VERSION ""

NS_ :

BS_:

BU_: FBD_HL IPB_App1 FBD_HM FBD_HR FBD_Miko FBD_MM FBD_Trunk FBD_VL FBD_VM FBD_VR Diagnosetool_CAN_FD_IPB_41

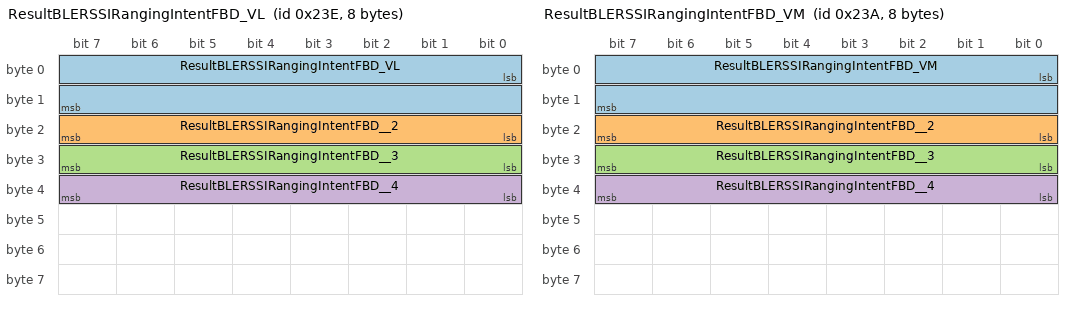
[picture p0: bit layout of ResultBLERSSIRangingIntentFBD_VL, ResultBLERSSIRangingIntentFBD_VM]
BO_ 574 ResultBLERSSIRangingIntentFBD_VL: 8 FBD_VL
 SG_ ResultBLERSSIRangingIntentFBD_VL : 0|16@1+ (1,0) [0|0] "" FBD_HL,FBD_HM,FBD_HR,FBD_MM,FBD_Miko,FBD_Trunk,FBD_VM,FBD_VR
 SG_ ResultBLERSSIRangingIntentFBD__2 : 16|8@1+ (1.0,0) [0|252] "" FBD_HL,FBD_HM,FBD_HR,FBD_MM,FBD_Miko,FBD_Trunk,FBD_VM,FBD_VR
 SG_ ResultBLERSSIRangingIntentFBD__3 : 24|8@1+ (1.0,0) [0|252] "" FBD_HL,FBD_HM,FBD_HR,FBD_MM,FBD_Miko,FBD_Trunk,FBD_VM,FBD_VR
 SG_ ResultBLERSSIRangingIntentFBD__4 : 32|8@1+ (0.004,0) [0|1] "" FBD_HL,FBD_HM,FBD_HR,FBD_MM,FBD_Miko,FBD_Trunk,FBD_VM,FBD_VR

BO_ 570 ResultBLERSSIRangingIntentFBD_VM: 8 FBD_VM
 SG_ ResultBLERSSIRangingIntentFBD_VM : 0|16@1+ (1,0) [0|0] "" FBD_HL,FBD_HM,FBD_HR,FBD_MM,FBD_Miko,FBD_Trunk,FBD_VL,FBD_VR
 SG_ ResultBLERSSIRangingIntentFBD__2 : 16|8@1+ (1.0,0) [0|252] "" FBD_HL,FBD_HM,FBD_HR,FBD_MM,FBD_Miko,FBD_Trunk,FBD_VL,FBD_VR
 SG_ ResultBLERSSIRangingIntentFBD__3 : 24|8@1+ (1.0,0) [0|252] "" FBD_HL,FBD_HM,FBD_HR,FBD_MM,FBD_Miko,FBD_Trunk,FBD_VL,FBD_VR
 SG_ ResultBLERSSIRangingIntentFBD__4 : 32|8@1+ (0.004,0) [0|1] "" FBD_HL,FBD_HM,FBD_HR,FBD_MM,FBD_Miko,FBD_Trunk,FBD_VL,FBD_VR

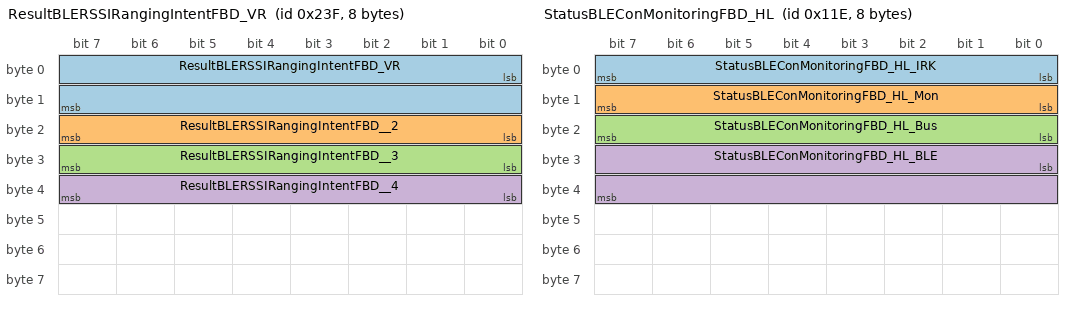
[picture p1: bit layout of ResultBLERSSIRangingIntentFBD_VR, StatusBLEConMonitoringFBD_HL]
BO_ 575 ResultBLERSSIRangingIntentFBD_VR: 8 FBD_VR
 SG_ ResultBLERSSIRangingIntentFBD_VR : 0|16@1+ (1,0) [0|0] "" FBD_HL,FBD_HM,FBD_HR,FBD_MM,FBD_Miko,FBD_Trunk,FBD_VL,FBD_VM
 SG_ ResultBLERSSIRangingIntentFBD__2 : 16|8@1+ (1.0,0) [0|252] "" FBD_HL,FBD_HM,FBD_HR,FBD_MM,FBD_Miko,FBD_Trunk,FBD_VL,FBD_VM
 SG_ ResultBLERSSIRangingIntentFBD__3 : 24|8@1+ (1.0,0) [0|252] "" FBD_HL,FBD_HM,FBD_HR,FBD_MM,FBD_Miko,FBD_Trunk,FBD_VL,FBD_VM
 SG_ ResultBLERSSIRangingIntentFBD__4 : 32|8@1+ (0.004,0) [0|1] "" FBD_HL,FBD_HM,FBD_HR,FBD_MM,FBD_Miko,FBD_Trunk,FBD_VL,FBD_VM

BO_ 486 ResumeRangingSessionFBD_HL: 20 FBD_HL
 SG_ ResumeRangingSessionFBD_HL_Funct : 0|8@1+ (1.0,0) [0|252] "" FBD_HM,FBD_HR,FBD_MM,FBD_Miko,FBD_Trunk,FBD_VL,FBD_VM,FBD_VR,IPB_App1
 SG_ ResumeRangingSessionFBD_HL_Sessi : 8|8@1+ (1.0,0) [0|252] "" FBD_HM,FBD_HR,FBD_MM,FBD_Miko,FBD_Trunk,FBD_VL,FBD_VM,FBD_VR,IPB_App1
 SG_ ResumeRangingSessionFBD_HL_STSIn : 16|32@1+ (1.0,0) [0|4294967292] "" FBD_HM,FBD_HR,FBD_MM,FBD_Miko,FBD_Trunk,FBD_VL,FBD_VM,FBD_VR,IPB_App1
 SG_ ResumeRangingSessionFBD_HL_RANMu : 48|8@1+ (1.0,0) [0|252] "" FBD_HM,FBD_HR,FBD_MM,FBD_Miko,FBD_Trunk,FBD_VL,FBD_VM,FBD_VR,IPB_App1
 SG_ ResumeRangingSessionFBD_HL_UWBTi : 56|64@1+ (1.0,0) [0|18446744073709551612] "" FBD_HM,FBD_HR,FBD_MM,FBD_Miko,FBD_Trunk,FBD_VL,FBD_VM,FBD_VR,IPB_App1
 SG_ ResumeRangingSessionFBD_HL_ToFSt : 120|8@1+ (1.0,0) [0|252] "" FBD_HM,FBD_HR,FBD_MM,FBD_Miko,FBD_Trunk,FBD_VL,FBD_VM,FBD_VR,IPB_App1
 SG_ ResumeRangingSessionFBD_HL_Rangi : 128|16@1+ (1.0,0) [0|65532] "" FBD_HM,FBD_HR,FBD_MM,FBD_Miko,FBD_Trunk,FBD_VL,FBD_VM,FBD_VR,IPB_App1
 SG_ ResumeRangingSessionFBD_HL_Ran_2 : 144|16@1+ (1.0,0) [0|65532] "" FBD_HM,FBD_HR,FBD_MM,FBD_Miko,FBD_Trunk,FBD_VL,FBD_VM,FBD_VR,IPB_App1

BO_ 481 ResumeRangingSessionFBD_HM: 20 FBD_HM
 SG_ ResumeRangingSessionFBD_HM_Funct : 0|8@1+ (1.0,0) [0|252] "" FBD_HL,FBD_HR,FBD_MM,FBD_Miko,FBD_Trunk,FBD_VL,FBD_VM,FBD_VR,IPB_App1
 SG_ ResumeRangingSessionFBD_HM_Sessi : 8|8@1+ (1.0,0) [0|252] "" FBD_HL,FBD_HR,FBD_MM,FBD_Miko,FBD_Trunk,FBD_VL,FBD_VM,FBD_VR,IPB_App1
 SG_ ResumeRangingSessionFBD_HM_STSIn : 16|32@1+ (1.0,0) [0|4294967292] "" FBD_HL,FBD_HR,FBD_MM,FBD_Miko,FBD_Trunk,FBD_VL,FBD_VM,FBD_VR,IPB_App1
 SG_ ResumeRangingSessionFBD_HM_RANMu : 48|8@1+ (1.0,0) [0|252] "" FBD_HL,FBD_HR,FBD_MM,FBD_Miko,FBD_Trunk,FBD_VL,FBD_VM,FBD_VR,IPB_App1
 SG_ ResumeRangingSessionFBD_HM_UWBTi : 56|64@1+ (1.0,0) [0|18446744073709551612] "" FBD_HL,FBD_HR,FBD_MM,FBD_Miko,FBD_Trunk,FBD_VL,FBD_VM,FBD_VR,IPB_App1
 SG_ ResumeRangingSessionFBD_HM_ToFSt : 120|8@1+ (1.0,0) [0|252] "" FBD_HL,FBD_HR,FBD_MM,FBD_Miko,FBD_Trunk,FBD_VL,FBD_VM,FBD_VR,IPB_App1
 SG_ ResumeRangingSessionFBD_HM_Rangi : 128|16@1+ (1.0,0) [0|65532] "" FBD_HL,FBD_HR,FBD_MM,FBD_Miko,FBD_Trunk,FBD_VL,FBD_VM,FBD_VR,IPB_App1
 SG_ ResumeRangingSessionFBD_HM_Ran_2 : 144|16@1+ (1.0,0) [0|65532] "" FBD_HL,FBD_HR,FBD_MM,FBD_Miko,FBD_Trunk,FBD_VL,FBD_VM,FBD_VR,IPB_App1

BO_ 487 ResumeRangingSessionFBD_HR: 20 FBD_HR
 SG_ ResumeRangingSessionFBD_HR_Funct : 0|8@1+ (1.0,0) [0|252] "" FBD_HL,FBD_HM,FBD_MM,FBD_Miko,FBD_Trunk,FBD_VL,FBD_VM,FBD_VR,IPB_App1
 SG_ ResumeRangingSessionFBD_HR_Sessi : 8|8@1+ (1.0,0) [0|252] "" FBD_HL,FBD_HM,FBD_MM,FBD_Miko,FBD_Trunk,FBD_VL,FBD_VM,FBD_VR,IPB_App1
 SG_ ResumeRangingSessionFBD_HR_STSIn : 16|32@1+ (1.0,0) [0|4294967292] "" FBD_HL,FBD_HM,FBD_MM,FBD_Miko,FBD_Trunk,FBD_VL,FBD_VM,FBD_VR,IPB_App1
 SG_ ResumeRangingSessionFBD_HR_RANMu : 48|8@1+ (1.0,0) [0|252] "" FBD_HL,FBD_HM,FBD_MM,FBD_Miko,FBD_Trunk,FBD_VL,FBD_VM,FBD_VR,IPB_App1
 SG_ ResumeRangingSessionFBD_HR_UWBTi : 56|64@1+ (1.0,0) [0|18446744073709551612] "" FBD_HL,FBD_HM,FBD_MM,FBD_Miko,FBD_Trunk,FBD_VL,FBD_VM,FBD_VR,IPB_App1
 SG_ ResumeRangingSessionFBD_HR_ToFSt : 120|8@1+ (1.0,0) [0|252] "" FBD_HL,FBD_HM,FBD_MM,FBD_Miko,FBD_Trunk,FBD_VL,FBD_VM,FBD_VR,IPB_App1
 SG_ ResumeRangingSessionFBD_HR_Rangi : 128|16@1+ (1.0,0) [0|65532] "" FBD_HL,FBD_HM,FBD_MM,FBD_Miko,FBD_Trunk,FBD_VL,FBD_VM,FBD_VR,IPB_App1
 SG_ ResumeRangingSessionFBD_HR_Ran_2 : 144|16@1+ (1.0,0) [0|65532] "" FBD_HL,FBD_HM,FBD_MM,FBD_Miko,FBD_Trunk,FBD_VL,FBD_VM,FBD_VR,IPB_App1

BO_ 482 ResumeRangingSessionFBD_Miko: 20 FBD_Miko
 SG_ ResumeRangingSessionFBD_Miko_Fun : 0|8@1+ (1.0,0) [0|252] "" FBD_HL,FBD_HM,FBD_HR,FBD_MM,FBD_Trunk,FBD_VL,FBD_VM,FBD_VR,IPB_App1
 SG_ ResumeRangingSessionFBD_Miko_Ses : 8|8@1+ (1.0,0) [0|252] "" FBD_HL,FBD_HM,FBD_HR,FBD_MM,FBD_Trunk,FBD_VL,FBD_VM,FBD_VR,IPB_App1
 SG_ ResumeRangingSessionFBD_Miko_STS : 16|32@1+ (1.0,0) [0|4294967292] "" FBD_HL,FBD_HM,FBD_HR,FBD_MM,FBD_Trunk,FBD_VL,FBD_VM,FBD_VR,IPB_App1
 SG_ ResumeRangingSessionFBD_Miko_RAN : 48|8@1+ (1.0,0) [0|252] "" FBD_HL,FBD_HM,FBD_HR,FBD_MM,FBD_Trunk,FBD_VL,FBD_VM,FBD_VR,IPB_App1
 SG_ ResumeRangingSessionFBD_Miko_UWB : 56|64@1+ (1.0,0) [0|18446744073709551612] "" FBD_HL,FBD_HM,FBD_HR,FBD_MM,FBD_Trunk,FBD_VL,FBD_VM,FBD_VR,IPB_App1
 SG_ ResumeRangingSessionFBD_Miko_ToF : 120|8@1+ (1.0,0) [0|252] "" FBD_HL,FBD_HM,FBD_HR,FBD_MM,FBD_Trunk,FBD_VL,FBD_VM,FBD_VR,IPB_App1
 SG_ ResumeRangingSessionFBD_Miko_Ran : 128|16@1+ (1.0,0) [0|65532] "" FBD_HL,FBD_HM,FBD_HR,FBD_MM,FBD_Trunk,FBD_VL,FBD_VM,FBD_VR,IPB_App1
 SG_ ResumeRangingSessionFBD_Miko_R_2 : 144|16@1+ (1.0,0) [0|65532] "" FBD_HL,FBD_HM,FBD_HR,FBD_MM,FBD_Trunk,FBD_VL,FBD_VM,FBD_VR,IPB_App1

BO_ 442 ResumeRangingSessionFBD_MM: 20 FBD_MM
 SG_ ResumeRangingSessionFBD_MM_Funct : 0|8@1+ (1.0,0) [0|252] "" FBD_HL,FBD_HM,FBD_HR,FBD_Miko,FBD_Trunk,FBD_VL,FBD_VM,FBD_VR,IPB_App1
 SG_ ResumeRangingSessionFBD_MM_Sessi : 8|8@1+ (1.0,0) [0|252] "" FBD_HL,FBD_HM,FBD_HR,FBD_Miko,FBD_Trunk,FBD_VL,FBD_VM,FBD_VR,IPB_App1
 SG_ ResumeRangingSessionFBD_MM_STSIn : 16|32@1+ (1.0,0) [0|4294967292] "" FBD_HL,FBD_HM,FBD_HR,FBD_Miko,FBD_Trunk,FBD_VL,FBD_VM,FBD_VR,IPB_App1
 SG_ ResumeRangingSessionFBD_MM_RANMu : 48|8@1+ (1.0,0) [0|252] "" FBD_HL,FBD_HM,FBD_HR,FBD_Miko,FBD_Trunk,FBD_VL,FBD_VM,FBD_VR,IPB_App1
 SG_ ResumeRangingSessionFBD_MM_UWBTi : 56|64@1+ (1.0,0) [0|18446744073709551612] "" FBD_HL,FBD_HM,FBD_HR,FBD_Miko,FBD_Trunk,FBD_VL,FBD_VM,FBD_VR,IPB_App1
 SG_ ResumeRangingSessionFBD_MM_ToFSt : 120|8@1+ (1.0,0) [0|252] "" FBD_HL,FBD_HM,FBD_HR,FBD_Miko,FBD_Trunk,FBD_VL,FBD_VM,FBD_VR,IPB_App1
 SG_ ResumeRangingSessionFBD_MM_Rangi : 128|16@1+ (1.0,0) [0|65532] "" FBD_HL,FBD_HM,FBD_HR,FBD_Miko,FBD_Trunk,FBD_VL,FBD_VM,FBD_VR,IPB_App1
 SG_ ResumeRangingSessionFBD_MM_Ran_2 : 144|16@1+ (1.0,0) [0|65532] "" FBD_HL,FBD_HM,FBD_HR,FBD_Miko,FBD_Trunk,FBD_VL,FBD_VM,FBD_VR,IPB_App1

BO_ 488 ResumeRangingSessionFBD_SML: 20 IPB_App1
 SG_ ResumeRangingSessionFBD_SML_Func : 0|8@1+ (1.0,0) [0|252] "" FBD_HL,FBD_HM,FBD_HR,FBD_MM,FBD_Miko,FBD_Trunk,FBD_VL,FBD_VM,FBD_VR
 SG_ ResumeRangingSessionFBD_SML_Sess : 8|8@1+ (1.0,0) [0|252] "" FBD_HL,FBD_HM,FBD_HR,FBD_MM,FBD_Miko,FBD_Trunk,FBD_VL,FBD_VM,FBD_VR
 SG_ ResumeRangingSessionFBD_SML_STSI : 16|32@1+ (1.0,0) [0|4294967292] "" FBD_HL,FBD_HM,FBD_HR,FBD_MM,FBD_Miko,FBD_Trunk,FBD_VL,FBD_VM,FBD_VR
 SG_ ResumeRangingSessionFBD_SML_RANM : 48|8@1+ (1.0,0) [0|252] "" FBD_HL,FBD_HM,FBD_HR,FBD_MM,FBD_Miko,FBD_Trunk,FBD_VL,FBD_VM,FBD_VR
 SG_ ResumeRangingSessionFBD_SML_UWBT : 56|64@1+ (1.0,0) [0|18446744073709551612] "" FBD_HL,FBD_HM,FBD_HR,FBD_MM,FBD_Miko,FBD_Trunk,FBD_VL,FBD_VM,FBD_VR
 SG_ ResumeRangingSessionFBD_SML_ToFS : 120|8@1+ (1.0,0) [0|252] "" FBD_HL,FBD_HM,FBD_HR,FBD_MM,FBD_Miko,FBD_Trunk,FBD_VL,FBD_VM,FBD_VR
 SG_ ResumeRangingSessionFBD_SML_Rang : 128|16@1+ (1.0,0) [0|65532] "" FBD_HL,FBD_HM,FBD_HR,FBD_MM,FBD_Miko,FBD_Trunk,FBD_VL,FBD_VM,FBD_VR
 SG_ ResumeRangingSessionFBD_SML_Ra_2 : 144|16@1+ (1.0,0) [0|65532] "" FBD_HL,FBD_HM,FBD_HR,FBD_MM,FBD_Miko,FBD_Trunk,FBD_VL,FBD_VM,FBD_VR

BO_ 489 ResumeRangingSessionFBD_SMR: 20 IPB_App1
 SG_ ResumeRangingSessionFBD_SMR_Func : 0|8@1+ (1.0,0) [0|252] "" FBD_HL,FBD_HM,FBD_HR,FBD_MM,FBD_Miko,FBD_Trunk,FBD_VL,FBD_VM,FBD_VR
 SG_ ResumeRangingSessionFBD_SMR_Sess : 8|8@1+ (1.0,0) [0|252] "" FBD_HL,FBD_HM,FBD_HR,FBD_MM,FBD_Miko,FBD_Trunk,FBD_VL,FBD_VM,FBD_VR
 SG_ ResumeRangingSessionFBD_SMR_STSI : 16|32@1+ (1.0,0) [0|4294967292] "" FBD_HL,FBD_HM,FBD_HR,FBD_MM,FBD_Miko,FBD_Trunk,FBD_VL,FBD_VM,FBD_VR
 SG_ ResumeRangingSessionFBD_SMR_RANM : 48|8@1+ (1.0,0) [0|252] "" FBD_HL,FBD_HM,FBD_HR,FBD_MM,FBD_Miko,FBD_Trunk,FBD_VL,FBD_VM,FBD_VR
 SG_ ResumeRangingSessionFBD_SMR_UWBT : 56|64@1+ (1.0,0) [0|18446744073709551612] "" FBD_HL,FBD_HM,FBD_HR,FBD_MM,FBD_Miko,FBD_Trunk,FBD_VL,FBD_VM,FBD_VR
 SG_ ResumeRangingSessionFBD_SMR_ToFS : 120|8@1+ (1.0,0) [0|252] "" FBD_HL,FBD_HM,FBD_HR,FBD_MM,FBD_Miko,FBD_Trunk,FBD_VL,FBD_VM,FBD_VR
 SG_ ResumeRangingSessionFBD_SMR_Rang : 128|16@1+ (1.0,0) [0|65532] "" FBD_HL,FBD_HM,FBD_HR,FBD_MM,FBD_Miko,FBD_Trunk,FBD_VL,FBD_VM,FBD_VR
 SG_ ResumeRangingSessionFBD_SMR_Ra_2 : 144|16@1+ (1.0,0) [0|65532] "" FBD_HL,FBD_HM,FBD_HR,FBD_MM,FBD_Miko,FBD_Trunk,FBD_VL,FBD_VM,FBD_VR

BO_ 483 ResumeRangingSessionFBD_Trunk: 20 FBD_Trunk
 SG_ ResumeRangingSessionFBD_Trunk_Fu : 0|8@1+ (1.0,0) [0|252] "" FBD_HL,FBD_HM,FBD_HR,FBD_MM,FBD_Miko,FBD_VL,FBD_VM,FBD_VR,IPB_App1
 SG_ ResumeRangingSessionFBD_Trunk_Se : 8|8@1+ (1.0,0) [0|252] "" FBD_HL,FBD_HM,FBD_HR,FBD_MM,FBD_Miko,FBD_VL,FBD_VM,FBD_VR,IPB_App1
 SG_ ResumeRangingSessionFBD_Trunk_ST : 16|32@1+ (1.0,0) [0|4294967292] "" FBD_HL,FBD_HM,FBD_HR,FBD_MM,FBD_Miko,FBD_VL,FBD_VM,FBD_VR,IPB_App1
 SG_ ResumeRangingSessionFBD_Trunk_RA : 48|8@1+ (1.0,0) [0|252] "" FBD_HL,FBD_HM,FBD_HR,FBD_MM,FBD_Miko,FBD_VL,FBD_VM,FBD_VR,IPB_App1
 SG_ ResumeRangingSessionFBD_Trunk_UW : 56|64@1+ (1.0,0) [0|18446744073709551612] "" FBD_HL,FBD_HM,FBD_HR,FBD_MM,FBD_Miko,FBD_VL,FBD_VM,FBD_VR,IPB_App1
 SG_ ResumeRangingSessionFBD_Trunk_To : 120|8@1+ (1.0,0) [0|252] "" FBD_HL,FBD_HM,FBD_HR,FBD_MM,FBD_Miko,FBD_VL,FBD_VM,FBD_VR,IPB_App1
 SG_ ResumeRangingSessionFBD_Trunk_Ra : 128|16@1+ (1.0,0) [0|65532] "" FBD_HL,FBD_HM,FBD_HR,FBD_MM,FBD_Miko,FBD_VL,FBD_VM,FBD_VR,IPB_App1
 SG_ ResumeRangingSessionFBD_Trunk__2 : 144|16@1+ (1.0,0) [0|65532] "" FBD_HL,FBD_HM,FBD_HR,FBD_MM,FBD_Miko,FBD_VL,FBD_VM,FBD_VR,IPB_App1

BO_ 484 ResumeRangingSessionFBD_VL: 20 FBD_VL
 SG_ ResumeRangingSessionFBD_VL_Funct : 0|8@1+ (1.0,0) [0|252] "" FBD_HL,FBD_HM,FBD_HR,FBD_MM,FBD_Miko,FBD_Trunk,FBD_VM,FBD_VR,IPB_App1
 SG_ ResumeRangingSessionFBD_VL_Sessi : 8|8@1+ (1.0,0) [0|252] "" FBD_HL,FBD_HM,FBD_HR,FBD_MM,FBD_Miko,FBD_Trunk,FBD_VM,FBD_VR,IPB_App1
 SG_ ResumeRangingSessionFBD_VL_STSIn : 16|32@1+ (1.0,0) [0|4294967292] "" FBD_HL,FBD_HM,FBD_HR,FBD_MM,FBD_Miko,FBD_Trunk,FBD_VM,FBD_VR,IPB_App1
 SG_ ResumeRangingSessionFBD_VL_RANMu : 48|8@1+ (1.0,0) [0|252] "" FBD_HL,FBD_HM,FBD_HR,FBD_MM,FBD_Miko,FBD_Trunk,FBD_VM,FBD_VR,IPB_App1
 SG_ ResumeRangingSessionFBD_VL_UWBTi : 56|64@1+ (1.0,0) [0|18446744073709551612] "" FBD_HL,FBD_HM,FBD_HR,FBD_MM,FBD_Miko,FBD_Trunk,FBD_VM,FBD_VR,IPB_App1
 SG_ ResumeRangingSessionFBD_VL_ToFSt : 120|8@1+ (1.0,0) [0|252] "" FBD_HL,FBD_HM,FBD_HR,FBD_MM,FBD_Miko,FBD_Trunk,FBD_VM,FBD_VR,IPB_App1
 SG_ ResumeRangingSessionFBD_VL_Rangi : 128|16@1+ (1.0,0) [0|65532] "" FBD_HL,FBD_HM,FBD_HR,FBD_MM,FBD_Miko,FBD_Trunk,FBD_VM,FBD_VR,IPB_App1
 SG_ ResumeRangingSessionFBD_VL_Ran_2 : 144|16@1+ (1.0,0) [0|65532] "" FBD_HL,FBD_HM,FBD_HR,FBD_MM,FBD_Miko,FBD_Trunk,FBD_VM,FBD_VR,IPB_App1

BO_ 480 ResumeRangingSessionFBD_VM: 20 FBD_VM
 SG_ ResumeRangingSessionFBD_VM_Funct : 0|8@1+ (1.0,0) [0|252] "" FBD_HL,FBD_HM,FBD_HR,FBD_MM,FBD_Miko,FBD_Trunk,FBD_VL,FBD_VR,IPB_App1
 SG_ ResumeRangingSessionFBD_VM_Sessi : 8|8@1+ (1.0,0) [0|252] "" FBD_HL,FBD_HM,FBD_HR,FBD_MM,FBD_Miko,FBD_Trunk,FBD_VL,FBD_VR,IPB_App1
 SG_ ResumeRangingSessionFBD_VM_STSIn : 16|32@1+ (1.0,0) [0|4294967292] "" FBD_HL,FBD_HM,FBD_HR,FBD_MM,FBD_Miko,FBD_Trunk,FBD_VL,FBD_VR,IPB_App1
 SG_ ResumeRangingSessionFBD_VM_RANMu : 48|8@1+ (1.0,0) [0|252] "" FBD_HL,FBD_HM,FBD_HR,FBD_MM,FBD_Miko,FBD_Trunk,FBD_VL,FBD_VR,IPB_App1
 SG_ ResumeRangingSessionFBD_VM_UWBTi : 56|64@1+ (1.0,0) [0|18446744073709551612] "" FBD_HL,FBD_HM,FBD_HR,FBD_MM,FBD_Miko,FBD_Trunk,FBD_VL,FBD_VR,IPB_App1
 SG_ ResumeRangingSessionFBD_VM_ToFSt : 120|8@1+ (1.0,0) [0|252] "" FBD_HL,FBD_HM,FBD_HR,FBD_MM,FBD_Miko,FBD_Trunk,FBD_VL,FBD_VR,IPB_App1
 SG_ ResumeRangingSessionFBD_VM_Rangi : 128|16@1+ (1.0,0) [0|65532] "" FBD_HL,FBD_HM,FBD_HR,FBD_MM,FBD_Miko,FBD_Trunk,FBD_VL,FBD_VR,IPB_App1
 SG_ ResumeRangingSessionFBD_VM_Ran_2 : 144|16@1+ (1.0,0) [0|65532] "" FBD_HL,FBD_HM,FBD_HR,FBD_MM,FBD_Miko,FBD_Trunk,FBD_VL,FBD_VR,IPB_App1

BO_ 485 ResumeRangingSessionFBD_VR: 20 FBD_VR
 SG_ ResumeRangingSessionFBD_VR_Funct : 0|8@1+ (1.0,0) [0|252] "" FBD_HL,FBD_HM,FBD_HR,FBD_MM,FBD_Miko,FBD_Trunk,FBD_VL,FBD_VM,IPB_App1
 SG_ ResumeRangingSessionFBD_VR_Sessi : 8|8@1+ (1.0,0) [0|252] "" FBD_HL,FBD_HM,FBD_HR,FBD_MM,FBD_Miko,FBD_Trunk,FBD_VL,FBD_VM,IPB_App1
 SG_ ResumeRangingSessionFBD_VR_STSIn : 16|32@1+ (1.0,0) [0|4294967292] "" FBD_HL,FBD_HM,FBD_HR,FBD_MM,FBD_Miko,FBD_Trunk,FBD_VL,FBD_VM,IPB_App1
 SG_ ResumeRangingSessionFBD_VR_RANMu : 48|8@1+ (1.0,0) [0|252] "" FBD_HL,FBD_HM,FBD_HR,FBD_MM,FBD_Miko,FBD_Trunk,FBD_VL,FBD_VM,IPB_App1
 SG_ ResumeRangingSessionFBD_VR_UWBTi : 56|64@1+ (1.0,0) [0|18446744073709551612] "" FBD_HL,FBD_HM,FBD_HR,FBD_MM,FBD_Miko,FBD_Trunk,FBD_VL,FBD_VM,IPB_App1
 SG_ ResumeRangingSessionFBD_VR_ToFSt : 120|8@1+ (1.0,0) [0|252] "" FBD_HL,FBD_HM,FBD_HR,FBD_MM,FBD_Miko,FBD_Trunk,FBD_VL,FBD_VM,IPB_App1
 SG_ ResumeRangingSessionFBD_VR_Rangi : 128|16@1+ (1.0,0) [0|65532] "" FBD_HL,FBD_HM,FBD_HR,FBD_MM,FBD_Miko,FBD_Trunk,FBD_VL,FBD_VM,IPB_App1
 SG_ ResumeRangingSessionFBD_VR_Ran_2 : 144|16@1+ (1.0,0) [0|65532] "" FBD_HL,FBD_HM,FBD_HR,FBD_MM,FBD_Miko,FBD_Trunk,FBD_VL,FBD_VM,IPB_App1

BO_ 276 SeamlessBLEStatusFBD_HL: 20 FBD_HL
 SG_ SeamlessBLEStatusFBD_HL_NumberAc : 0|8@1+ (1.0,0) [0|252] "" FBD_HM,FBD_HR,FBD_MM,FBD_Miko,FBD_Trunk,FBD_VL,FBD_VM,FBD_VR,IPB_App1
 SG_ SeamlessBLEStatusFBD_HL_Connecti : 8|8@1+ (1.0,0) [0|252] "" FBD_HM,FBD_HR,FBD_MM,FBD_Miko,FBD_Trunk,FBD_VL,FBD_VM,FBD_VR,IPB_App1
 SG_ SeamlessBLEStatusFBD_HL_Connec_2 : 16|8@1+ (0.5,-127) [-127|-1] "dB" FBD_HM,FBD_HR,FBD_MM,FBD_Miko,FBD_Trunk,FBD_VL,FBD_VM,FBD_VR,IPB_App1
 SG_ SeamlessBLEStatusFBD_HL_Connec_3 : 24|8@1+ (1.0,0) [0|252] "" FBD_HM,FBD_HR,FBD_MM,FBD_Miko,FBD_Trunk,FBD_VL,FBD_VM,FBD_VR,IPB_App1
 SG_ SeamlessBLEStatusFBD_HL_Connec_4 : 32|8@1+ (0.5,-127) [-127|-1] "dB" FBD_HM,FBD_HR,FBD_MM,FBD_Miko,FBD_Trunk,FBD_VL,FBD_VM,FBD_VR,IPB_App1
 SG_ SeamlessBLEStatusFBD_HL_Connec_5 : 40|8@1+ (1.0,0) [0|252] "" FBD_HM,FBD_HR,FBD_MM,FBD_Miko,FBD_Trunk,FBD_VL,FBD_VM,FBD_VR,IPB_App1
 SG_ SeamlessBLEStatusFBD_HL_Connec_6 : 48|8@1+ (0.5,-127) [-127|-1] "dB" FBD_HM,FBD_HR,FBD_MM,FBD_Miko,FBD_Trunk,FBD_VL,FBD_VM,FBD_VR,IPB_App1
 SG_ SeamlessBLEStatusFBD_HL_Connec_7 : 56|8@1+ (1.0,0) [0|252] "" FBD_HM,FBD_HR,FBD_MM,FBD_Miko,FBD_Trunk,FBD_VL,FBD_VM,FBD_VR,IPB_App1
 SG_ SeamlessBLEStatusFBD_HL_Connec_8 : 64|8@1+ (0.5,-127) [-127|-1] "dB" FBD_HM,FBD_HR,FBD_MM,FBD_Miko,FBD_Trunk,FBD_VL,FBD_VM,FBD_VR,IPB_App1
 SG_ SeamlessBLEStatusFBD_HL_Connec_9 : 72|8@1+ (1.0,0) [0|252] "" FBD_HM,FBD_HR,FBD_MM,FBD_Miko,FBD_Trunk,FBD_VL,FBD_VM,FBD_VR,IPB_App1
 SG_ SeamlessBLEStatusFBD_HL_Conne_10 : 80|8@1+ (0.5,-127) [-127|-1] "dB" FBD_HM,FBD_HR,FBD_MM,FBD_Miko,FBD_Trunk,FBD_VL,FBD_VM,FBD_VR,IPB_App1
 SG_ SeamlessBLEStatusFBD_HL_Conne_11 : 88|8@1+ (1.0,0) [0|252] "" FBD_HM,FBD_HR,FBD_MM,FBD_Miko,FBD_Trunk,FBD_VL,FBD_VM,FBD_VR,IPB_App1
 SG_ SeamlessBLEStatusFBD_HL_Conne_12 : 96|8@1+ (0.5,-127) [-127|-1] "dB" FBD_HM,FBD_HR,FBD_MM,FBD_Miko,FBD_Trunk,FBD_VL,FBD_VM,FBD_VR,IPB_App1
 SG_ SeamlessBLEStatusFBD_HL_Conne_13 : 104|8@1+ (1.0,0) [0|252] "" FBD_HM,FBD_HR,FBD_MM,FBD_Miko,FBD_Trunk,FBD_VL,FBD_VM,FBD_VR,IPB_App1
 SG_ SeamlessBLEStatusFBD_HL_Conne_14 : 112|8@1+ (0.5,-127) [-127|-1] "dB" FBD_HM,FBD_HR,FBD_MM,FBD_Miko,FBD_Trunk,FBD_VL,FBD_VM,FBD_VR,IPB_App1
 SG_ SeamlessBLEStatusFBD_HL_Conne_15 : 120|8@1+ (1.0,0) [0|252] "" FBD_HM,FBD_HR,FBD_MM,FBD_Miko,FBD_Trunk,FBD_VL,FBD_VM,FBD_VR,IPB_App1
 SG_ SeamlessBLEStatusFBD_HL_Conne_16 : 128|8@1+ (0.5,-127) [-127|-1] "dB" FBD_HM,FBD_HR,FBD_MM,FBD_Miko,FBD_Trunk,FBD_VL,FBD_VM,FBD_VR,IPB_App1

BO_ 271 SeamlessBLEStatusFBD_HM: 20 FBD_HM
 SG_ SeamlessBLEStatusFBD_HM_NumberAc : 0|8@1+ (1.0,0) [0|252] "" FBD_HL,FBD_HR,FBD_MM,FBD_Miko,FBD_Trunk,FBD_VL,FBD_VM,FBD_VR,IPB_App1
 SG_ SeamlessBLEStatusFBD_HM_Connecti : 8|8@1+ (1.0,0) [0|252] "" FBD_HL,FBD_HR,FBD_MM,FBD_Miko,FBD_Trunk,FBD_VL,FBD_VM,FBD_VR,IPB_App1
 SG_ SeamlessBLEStatusFBD_HM_Connec_2 : 16|8@1+ (0.5,-127) [-127|-1] "dB" FBD_HL,FBD_HR,FBD_MM,FBD_Miko,FBD_Trunk,FBD_VL,FBD_VM,FBD_VR,IPB_App1
 SG_ SeamlessBLEStatusFBD_HM_Connec_3 : 24|8@1+ (1.0,0) [0|252] "" FBD_HL,FBD_HR,FBD_MM,FBD_Miko,FBD_Trunk,FBD_VL,FBD_VM,FBD_VR,IPB_App1
 SG_ SeamlessBLEStatusFBD_HM_Connec_4 : 32|8@1+ (0.5,-127) [-127|-1] "dB" FBD_HL,FBD_HR,FBD_MM,FBD_Miko,FBD_Trunk,FBD_VL,FBD_VM,FBD_VR,IPB_App1
 SG_ SeamlessBLEStatusFBD_HM_Connec_5 : 40|8@1+ (1.0,0) [0|252] "" FBD_HL,FBD_HR,FBD_MM,FBD_Miko,FBD_Trunk,FBD_VL,FBD_VM,FBD_VR,IPB_App1
 SG_ SeamlessBLEStatusFBD_HM_Connec_6 : 48|8@1+ (0.5,-127) [-127|-1] "dB" FBD_HL,FBD_HR,FBD_MM,FBD_Miko,FBD_Trunk,FBD_VL,FBD_VM,FBD_VR,IPB_App1
 SG_ SeamlessBLEStatusFBD_HM_Connec_7 : 56|8@1+ (1.0,0) [0|252] "" FBD_HL,FBD_HR,FBD_MM,FBD_Miko,FBD_Trunk,FBD_VL,FBD_VM,FBD_VR,IPB_App1
 SG_ SeamlessBLEStatusFBD_HM_Connec_8 : 64|8@1+ (0.5,-127) [-127|-1] "dB" FBD_HL,FBD_HR,FBD_MM,FBD_Miko,FBD_Trunk,FBD_VL,FBD_VM,FBD_VR,IPB_App1
 SG_ SeamlessBLEStatusFBD_HM_Connec_9 : 72|8@1+ (1.0,0) [0|252] "" FBD_HL,FBD_HR,FBD_MM,FBD_Miko,FBD_Trunk,FBD_VL,FBD_VM,FBD_VR,IPB_App1
 SG_ SeamlessBLEStatusFBD_HM_Conne_10 : 80|8@1+ (0.5,-127) [-127|-1] "dB" FBD_HL,FBD_HR,FBD_MM,FBD_Miko,FBD_Trunk,FBD_VL,FBD_VM,FBD_VR,IPB_App1
 SG_ SeamlessBLEStatusFBD_HM_Conne_11 : 88|8@1+ (1.0,0) [0|252] "" FBD_HL,FBD_HR,FBD_MM,FBD_Miko,FBD_Trunk,FBD_VL,FBD_VM,FBD_VR,IPB_App1
 SG_ SeamlessBLEStatusFBD_HM_Conne_12 : 96|8@1+ (0.5,-127) [-127|-1] "dB" FBD_HL,FBD_HR,FBD_MM,FBD_Miko,FBD_Trunk,FBD_VL,FBD_VM,FBD_VR,IPB_App1
 SG_ SeamlessBLEStatusFBD_HM_Conne_13 : 104|8@1+ (1.0,0) [0|252] "" FBD_HL,FBD_HR,FBD_MM,FBD_Miko,FBD_Trunk,FBD_VL,FBD_VM,FBD_VR,IPB_App1
 SG_ SeamlessBLEStatusFBD_HM_Conne_14 : 112|8@1+ (0.5,-127) [-127|-1] "dB" FBD_HL,FBD_HR,FBD_MM,FBD_Miko,FBD_Trunk,FBD_VL,FBD_VM,FBD_VR,IPB_App1
 SG_ SeamlessBLEStatusFBD_HM_Conne_15 : 120|8@1+ (1.0,0) [0|252] "" FBD_HL,FBD_HR,FBD_MM,FBD_Miko,FBD_Trunk,FBD_VL,FBD_VM,FBD_VR,IPB_App1
 SG_ SeamlessBLEStatusFBD_HM_Conne_16 : 128|8@1+ (0.5,-127) [-127|-1] "dB" FBD_HL,FBD_HR,FBD_MM,FBD_Miko,FBD_Trunk,FBD_VL,FBD_VM,FBD_VR,IPB_App1

BO_ 277 SeamlessBLEStatusFBD_HR: 20 FBD_HR
 SG_ SeamlessBLEStatusFBD_HR_NumberAc : 0|8@1+ (1.0,0) [0|252] "" FBD_HL,FBD_HM,FBD_MM,FBD_Miko,FBD_Trunk,FBD_VL,FBD_VM,FBD_VR,IPB_App1
 SG_ SeamlessBLEStatusFBD_HR_Connecti : 8|8@1+ (1.0,0) [0|252] "" FBD_HL,FBD_HM,FBD_MM,FBD_Miko,FBD_Trunk,FBD_VL,FBD_VM,FBD_VR,IPB_App1
 SG_ SeamlessBLEStatusFBD_HR_Connec_2 : 16|8@1+ (0.5,-127) [-127|-1] "dB" FBD_HL,FBD_HM,FBD_MM,FBD_Miko,FBD_Trunk,FBD_VL,FBD_VM,FBD_VR,IPB_App1
 SG_ SeamlessBLEStatusFBD_HR_Connec_3 : 24|8@1+ (1.0,0) [0|252] "" FBD_HL,FBD_HM,FBD_MM,FBD_Miko,FBD_Trunk,FBD_VL,FBD_VM,FBD_VR,IPB_App1
 SG_ SeamlessBLEStatusFBD_HR_Connec_4 : 32|8@1+ (0.5,-127) [-127|-1] "dB" FBD_HL,FBD_HM,FBD_MM,FBD_Miko,FBD_Trunk,FBD_VL,FBD_VM,FBD_VR,IPB_App1
 SG_ SeamlessBLEStatusFBD_HR_Connec_5 : 40|8@1+ (1.0,0) [0|252] "" FBD_HL,FBD_HM,FBD_MM,FBD_Miko,FBD_Trunk,FBD_VL,FBD_VM,FBD_VR,IPB_App1
 SG_ SeamlessBLEStatusFBD_HR_Connec_6 : 48|8@1+ (0.5,-127) [-127|-1] "dB" FBD_HL,FBD_HM,FBD_MM,FBD_Miko,FBD_Trunk,FBD_VL,FBD_VM,FBD_VR,IPB_App1
 SG_ SeamlessBLEStatusFBD_HR_Connec_7 : 56|8@1+ (1.0,0) [0|252] "" FBD_HL,FBD_HM,FBD_MM,FBD_Miko,FBD_Trunk,FBD_VL,FBD_VM,FBD_VR,IPB_App1
 SG_ SeamlessBLEStatusFBD_HR_Connec_8 : 64|8@1+ (0.5,-127) [-127|-1] "dB" FBD_HL,FBD_HM,FBD_MM,FBD_Miko,FBD_Trunk,FBD_VL,FBD_VM,FBD_VR,IPB_App1
 SG_ SeamlessBLEStatusFBD_HR_Connec_9 : 72|8@1+ (1.0,0) [0|252] "" FBD_HL,FBD_HM,FBD_MM,FBD_Miko,FBD_Trunk,FBD_VL,FBD_VM,FBD_VR,IPB_App1
 SG_ SeamlessBLEStatusFBD_HR_Conne_10 : 80|8@1+ (0.5,-127) [-127|-1] "dB" FBD_HL,FBD_HM,FBD_MM,FBD_Miko,FBD_Trunk,FBD_VL,FBD_VM,FBD_VR,IPB_App1
 SG_ SeamlessBLEStatusFBD_HR_Conne_11 : 88|8@1+ (1.0,0) [0|252] "" FBD_HL,FBD_HM,FBD_MM,FBD_Miko,FBD_Trunk,FBD_VL,FBD_VM,FBD_VR,IPB_App1
 SG_ SeamlessBLEStatusFBD_HR_Conne_12 : 96|8@1+ (0.5,-127) [-127|-1] "dB" FBD_HL,FBD_HM,FBD_MM,FBD_Miko,FBD_Trunk,FBD_VL,FBD_VM,FBD_VR,IPB_App1
 SG_ SeamlessBLEStatusFBD_HR_Conne_13 : 104|8@1+ (1.0,0) [0|252] "" FBD_HL,FBD_HM,FBD_MM,FBD_Miko,FBD_Trunk,FBD_VL,FBD_VM,FBD_VR,IPB_App1
 SG_ SeamlessBLEStatusFBD_HR_Conne_14 : 112|8@1+ (0.5,-127) [-127|-1] "dB" FBD_HL,FBD_HM,FBD_MM,FBD_Miko,FBD_Trunk,FBD_VL,FBD_VM,FBD_VR,IPB_App1
 SG_ SeamlessBLEStatusFBD_HR_Conne_15 : 120|8@1+ (1.0,0) [0|252] "" FBD_HL,FBD_HM,FBD_MM,FBD_Miko,FBD_Trunk,FBD_VL,FBD_VM,FBD_VR,IPB_App1
 SG_ SeamlessBLEStatusFBD_HR_Conne_16 : 128|8@1+ (0.5,-127) [-127|-1] "dB" FBD_HL,FBD_HM,FBD_MM,FBD_Miko,FBD_Trunk,FBD_VL,FBD_VM,FBD_VR,IPB_App1

BO_ 272 SeamlessBLEStatusFBD_Miko: 20 FBD_Miko
 SG_ SeamlessBLEStatusFBD_Miko_Number : 0|8@1+ (1.0,0) [0|252] "" FBD_HL,FBD_HM,FBD_HR,FBD_MM,FBD_Trunk,FBD_VL,FBD_VM,FBD_VR,IPB_App1
 SG_ SeamlessBLEStatusFBD_Miko_Connec : 8|8@1+ (1.0,0) [0|252] "" FBD_HL,FBD_HM,FBD_HR,FBD_MM,FBD_Trunk,FBD_VL,FBD_VM,FBD_VR,IPB_App1
 SG_ SeamlessBLEStatusFBD_Miko_Conn_2 : 16|8@1+ (0.5,-127) [-127|-1] "dB" FBD_HL,FBD_HM,FBD_HR,FBD_MM,FBD_Trunk,FBD_VL,FBD_VM,FBD_VR,IPB_App1
 SG_ SeamlessBLEStatusFBD_Miko_Conn_3 : 24|8@1+ (1.0,0) [0|252] "" FBD_HL,FBD_HM,FBD_HR,FBD_MM,FBD_Trunk,FBD_VL,FBD_VM,FBD_VR,IPB_App1
 SG_ SeamlessBLEStatusFBD_Miko_Conn_4 : 32|8@1+ (0.5,-127) [-127|-1] "dB" FBD_HL,FBD_HM,FBD_HR,FBD_MM,FBD_Trunk,FBD_VL,FBD_VM,FBD_VR,IPB_App1
 SG_ SeamlessBLEStatusFBD_Miko_Conn_5 : 40|8@1+ (1.0,0) [0|252] "" FBD_HL,FBD_HM,FBD_HR,FBD_MM,FBD_Trunk,FBD_VL,FBD_VM,FBD_VR,IPB_App1
 SG_ SeamlessBLEStatusFBD_Miko_Conn_6 : 48|8@1+ (0.5,-127) [-127|-1] "dB" FBD_HL,FBD_HM,FBD_HR,FBD_MM,FBD_Trunk,FBD_VL,FBD_VM,FBD_VR,IPB_App1
 SG_ SeamlessBLEStatusFBD_Miko_Conn_7 : 56|8@1+ (1.0,0) [0|252] "" FBD_HL,FBD_HM,FBD_HR,FBD_MM,FBD_Trunk,FBD_VL,FBD_VM,FBD_VR,IPB_App1
 SG_ SeamlessBLEStatusFBD_Miko_Conn_8 : 64|8@1+ (0.5,-127) [-127|-1] "dB" FBD_HL,FBD_HM,FBD_HR,FBD_MM,FBD_Trunk,FBD_VL,FBD_VM,FBD_VR,IPB_App1
 SG_ SeamlessBLEStatusFBD_Miko_Conn_9 : 72|8@1+ (1.0,0) [0|252] "" FBD_HL,FBD_HM,FBD_HR,FBD_MM,FBD_Trunk,FBD_VL,FBD_VM,FBD_VR,IPB_App1
 SG_ SeamlessBLEStatusFBD_Miko_Con_10 : 80|8@1+ (0.5,-127) [-127|-1] "dB" FBD_HL,FBD_HM,FBD_HR,FBD_MM,FBD_Trunk,FBD_VL,FBD_VM,FBD_VR,IPB_App1
 SG_ SeamlessBLEStatusFBD_Miko_Con_11 : 88|8@1+ (1.0,0) [0|252] "" FBD_HL,FBD_HM,FBD_HR,FBD_MM,FBD_Trunk,FBD_VL,FBD_VM,FBD_VR,IPB_App1
 SG_ SeamlessBLEStatusFBD_Miko_Con_12 : 96|8@1+ (0.5,-127) [-127|-1] "dB" FBD_HL,FBD_HM,FBD_HR,FBD_MM,FBD_Trunk,FBD_VL,FBD_VM,FBD_VR,IPB_App1
 SG_ SeamlessBLEStatusFBD_Miko_Con_13 : 104|8@1+ (1.0,0) [0|252] "" FBD_HL,FBD_HM,FBD_HR,FBD_MM,FBD_Trunk,FBD_VL,FBD_VM,FBD_VR,IPB_App1
 SG_ SeamlessBLEStatusFBD_Miko_Con_14 : 112|8@1+ (0.5,-127) [-127|-1] "dB" FBD_HL,FBD_HM,FBD_HR,FBD_MM,FBD_Trunk,FBD_VL,FBD_VM,FBD_VR,IPB_App1
 SG_ SeamlessBLEStatusFBD_Miko_Con_15 : 120|8@1+ (1.0,0) [0|252] "" FBD_HL,FBD_HM,FBD_HR,FBD_MM,FBD_Trunk,FBD_VL,FBD_VM,FBD_VR,IPB_App1
 SG_ SeamlessBLEStatusFBD_Miko_Con_16 : 128|8@1+ (0.5,-127) [-127|-1] "dB" FBD_HL,FBD_HM,FBD_HR,FBD_MM,FBD_Trunk,FBD_VL,FBD_VM,FBD_VR,IPB_App1

BO_ 822 SeamlessBLEStatusFBD_MM: 20 FBD_MM
 SG_ SeamlessBLEStatusFBD_MM_NumberAc : 0|8@1+ (1.0,0) [0|252] "" FBD_HL,FBD_HM,FBD_HR,FBD_Miko,FBD_Trunk,FBD_VL,FBD_VM,FBD_VR,IPB_App1
 SG_ SeamlessBLEStatusFBD_MM_Connecti : 8|8@1+ (1.0,0) [0|252] "" FBD_HL,FBD_HM,FBD_HR,FBD_Miko,FBD_Trunk,FBD_VL,FBD_VM,FBD_VR,IPB_App1
 SG_ SeamlessBLEStatusFBD_MM_Connec_2 : 16|8@1+ (0.5,-127) [-127|-1] "dB" FBD_HL,FBD_HM,FBD_HR,FBD_Miko,FBD_Trunk,FBD_VL,FBD_VM,FBD_VR,IPB_App1
 SG_ SeamlessBLEStatusFBD_MM_Connec_3 : 24|8@1+ (1.0,0) [0|252] "" FBD_HL,FBD_HM,FBD_HR,FBD_Miko,FBD_Trunk,FBD_VL,FBD_VM,FBD_VR,IPB_App1
 SG_ SeamlessBLEStatusFBD_MM_Connec_4 : 32|8@1+ (0.5,-127) [-127|-1] "dB" FBD_HL,FBD_HM,FBD_HR,FBD_Miko,FBD_Trunk,FBD_VL,FBD_VM,FBD_VR,IPB_App1
 SG_ SeamlessBLEStatusFBD_MM_Connec_5 : 40|8@1+ (1.0,0) [0|252] "" FBD_HL,FBD_HM,FBD_HR,FBD_Miko,FBD_Trunk,FBD_VL,FBD_VM,FBD_VR,IPB_App1
 SG_ SeamlessBLEStatusFBD_MM_Connec_6 : 48|8@1+ (0.5,-127) [-127|-1] "dB" FBD_HL,FBD_HM,FBD_HR,FBD_Miko,FBD_Trunk,FBD_VL,FBD_VM,FBD_VR,IPB_App1
 SG_ SeamlessBLEStatusFBD_MM_Connec_7 : 56|8@1+ (1.0,0) [0|252] "" FBD_HL,FBD_HM,FBD_HR,FBD_Miko,FBD_Trunk,FBD_VL,FBD_VM,FBD_VR,IPB_App1
 SG_ SeamlessBLEStatusFBD_MM_Connec_8 : 64|8@1+ (0.5,-127) [-127|-1] "dB" FBD_HL,FBD_HM,FBD_HR,FBD_Miko,FBD_Trunk,FBD_VL,FBD_VM,FBD_VR,IPB_App1
 SG_ SeamlessBLEStatusFBD_MM_Connec_9 : 72|8@1+ (1.0,0) [0|252] "" FBD_HL,FBD_HM,FBD_HR,FBD_Miko,FBD_Trunk,FBD_VL,FBD_VM,FBD_VR,IPB_App1
 SG_ SeamlessBLEStatusFBD_MM_Conne_10 : 80|8@1+ (0.5,-127) [-127|-1] "dB" FBD_HL,FBD_HM,FBD_HR,FBD_Miko,FBD_Trunk,FBD_VL,FBD_VM,FBD_VR,IPB_App1
 SG_ SeamlessBLEStatusFBD_MM_Conne_11 : 88|8@1+ (1.0,0) [0|252] "" FBD_HL,FBD_HM,FBD_HR,FBD_Miko,FBD_Trunk,FBD_VL,FBD_VM,FBD_VR,IPB_App1
 SG_ SeamlessBLEStatusFBD_MM_Conne_12 : 96|8@1+ (0.5,-127) [-127|-1] "dB" FBD_HL,FBD_HM,FBD_HR,FBD_Miko,FBD_Trunk,FBD_VL,FBD_VM,FBD_VR,IPB_App1
 SG_ SeamlessBLEStatusFBD_MM_Conne_13 : 104|8@1+ (1.0,0) [0|252] "" FBD_HL,FBD_HM,FBD_HR,FBD_Miko,FBD_Trunk,FBD_VL,FBD_VM,FBD_VR,IPB_App1
 SG_ SeamlessBLEStatusFBD_MM_Conne_14 : 112|8@1+ (0.5,-127) [-127|-1] "dB" FBD_HL,FBD_HM,FBD_HR,FBD_Miko,FBD_Trunk,FBD_VL,FBD_VM,FBD_VR,IPB_App1
 SG_ SeamlessBLEStatusFBD_MM_Conne_15 : 120|8@1+ (1.0,0) [0|252] "" FBD_HL,FBD_HM,FBD_HR,FBD_Miko,FBD_Trunk,FBD_VL,FBD_VM,FBD_VR,IPB_App1
 SG_ SeamlessBLEStatusFBD_MM_Conne_16 : 128|8@1+ (0.5,-127) [-127|-1] "dB" FBD_HL,FBD_HM,FBD_HR,FBD_Miko,FBD_Trunk,FBD_VL,FBD_VM,FBD_VR,IPB_App1

BO_ 273 SeamlessBLEStatusFBD_Trunk: 20 FBD_Trunk
 SG_ SeamlessBLEStatusFBD_Trunk_Numbe : 0|8@1+ (1.0,0) [0|252] "" FBD_HL,FBD_HM,FBD_HR,FBD_MM,FBD_Miko,FBD_VL,FBD_VM,FBD_VR,IPB_App1
 SG_ SeamlessBLEStatusFBD_Trunk_Conne : 8|8@1+ (1.0,0) [0|252] "" FBD_HL,FBD_HM,FBD_HR,FBD_MM,FBD_Miko,FBD_VL,FBD_VM,FBD_VR,IPB_App1
 SG_ SeamlessBLEStatusFBD_Trunk_Con_2 : 16|8@1+ (0.5,-127) [-127|-1] "dB" FBD_HL,FBD_HM,FBD_HR,FBD_MM,FBD_Miko,FBD_VL,FBD_VM,FBD_VR,IPB_App1
 SG_ SeamlessBLEStatusFBD_Trunk_Con_3 : 24|8@1+ (1.0,0) [0|252] "" FBD_HL,FBD_HM,FBD_HR,FBD_MM,FBD_Miko,FBD_VL,FBD_VM,FBD_VR,IPB_App1
 SG_ SeamlessBLEStatusFBD_Trunk_Con_4 : 32|8@1+ (0.5,-127) [-127|-1] "dB" FBD_HL,FBD_HM,FBD_HR,FBD_MM,FBD_Miko,FBD_VL,FBD_VM,FBD_VR,IPB_App1
 SG_ SeamlessBLEStatusFBD_Trunk_Con_5 : 40|8@1+ (1.0,0) [0|252] "" FBD_HL,FBD_HM,FBD_HR,FBD_MM,FBD_Miko,FBD_VL,FBD_VM,FBD_VR,IPB_App1
 SG_ SeamlessBLEStatusFBD_Trunk_Con_6 : 48|8@1+ (0.5,-127) [-127|-1] "dB" FBD_HL,FBD_HM,FBD_HR,FBD_MM,FBD_Miko,FBD_VL,FBD_VM,FBD_VR,IPB_App1
 SG_ SeamlessBLEStatusFBD_Trunk_Con_7 : 56|8@1+ (1.0,0) [0|252] "" FBD_HL,FBD_HM,FBD_HR,FBD_MM,FBD_Miko,FBD_VL,FBD_VM,FBD_VR,IPB_App1
 SG_ SeamlessBLEStatusFBD_Trunk_Con_8 : 64|8@1+ (0.5,-127) [-127|-1] "dB" FBD_HL,FBD_HM,FBD_HR,FBD_MM,FBD_Miko,FBD_VL,FBD_VM,FBD_VR,IPB_App1
 SG_ SeamlessBLEStatusFBD_Trunk_Con_9 : 72|8@1+ (1.0,0) [0|252] "" FBD_HL,FBD_HM,FBD_HR,FBD_MM,FBD_Miko,FBD_VL,FBD_VM,FBD_VR,IPB_App1
 SG_ SeamlessBLEStatusFBD_Trunk_Co_10 : 80|8@1+ (0.5,-127) [-127|-1] "dB" FBD_HL,FBD_HM,FBD_HR,FBD_MM,FBD_Miko,FBD_VL,FBD_VM,FBD_VR,IPB_App1
 SG_ SeamlessBLEStatusFBD_Trunk_Co_11 : 88|8@1+ (1.0,0) [0|252] "" FBD_HL,FBD_HM,FBD_HR,FBD_MM,FBD_Miko,FBD_VL,FBD_VM,FBD_VR,IPB_App1
 SG_ SeamlessBLEStatusFBD_Trunk_Co_12 : 96|8@1+ (0.5,-127) [-127|-1] "dB" FBD_HL,FBD_HM,FBD_HR,FBD_MM,FBD_Miko,FBD_VL,FBD_VM,FBD_VR,IPB_App1
 SG_ SeamlessBLEStatusFBD_Trunk_Co_13 : 104|8@1+ (1.0,0) [0|252] "" FBD_HL,FBD_HM,FBD_HR,FBD_MM,FBD_Miko,FBD_VL,FBD_VM,FBD_VR,IPB_App1
 SG_ SeamlessBLEStatusFBD_Trunk_Co_14 : 112|8@1+ (0.5,-127) [-127|-1] "dB" FBD_HL,FBD_HM,FBD_HR,FBD_MM,FBD_Miko,FBD_VL,FBD_VM,FBD_VR,IPB_App1
 SG_ SeamlessBLEStatusFBD_Trunk_Co_15 : 120|8@1+ (1.0,0) [0|252] "" FBD_HL,FBD_HM,FBD_HR,FBD_MM,FBD_Miko,FBD_VL,FBD_VM,FBD_VR,IPB_App1
 SG_ SeamlessBLEStatusFBD_Trunk_Co_16 : 128|8@1+ (0.5,-127) [-127|-1] "dB" FBD_HL,FBD_HM,FBD_HR,FBD_MM,FBD_Miko,FBD_VL,FBD_VM,FBD_VR,IPB_App1

BO_ 274 SeamlessBLEStatusFBD_VL: 20 FBD_VL
 SG_ SeamlessBLEStatusFBD_VL_NumberAc : 0|8@1+ (1.0,0) [0|252] "" FBD_HL,FBD_HM,FBD_HR,FBD_MM,FBD_Miko,FBD_Trunk,FBD_VM,FBD_VR,IPB_App1
 SG_ SeamlessBLEStatusFBD_VL_Connecti : 8|8@1+ (1.0,0) [0|252] "" FBD_HL,FBD_HM,FBD_HR,FBD_MM,FBD_Miko,FBD_Trunk,FBD_VM,FBD_VR,IPB_App1
 SG_ SeamlessBLEStatusFBD_VL_Connec_2 : 16|8@1+ (0.5,-127) [-127|-1] "dB" FBD_HL,FBD_HM,FBD_HR,FBD_MM,FBD_Miko,FBD_Trunk,FBD_VM,FBD_VR,IPB_App1
 SG_ SeamlessBLEStatusFBD_VL_Connec_3 : 24|8@1+ (1.0,0) [0|252] "" FBD_HL,FBD_HM,FBD_HR,FBD_MM,FBD_Miko,FBD_Trunk,FBD_VM,FBD_VR,IPB_App1
 SG_ SeamlessBLEStatusFBD_VL_Connec_4 : 32|8@1+ (0.5,-127) [-127|-1] "dB" FBD_HL,FBD_HM,FBD_HR,FBD_MM,FBD_Miko,FBD_Trunk,FBD_VM,FBD_VR,IPB_App1
 SG_ SeamlessBLEStatusFBD_VL_Connec_5 : 40|8@1+ (1.0,0) [0|252] "" FBD_HL,FBD_HM,FBD_HR,FBD_MM,FBD_Miko,FBD_Trunk,FBD_VM,FBD_VR,IPB_App1
 SG_ SeamlessBLEStatusFBD_VL_Connec_6 : 48|8@1+ (0.5,-127) [-127|-1] "dB" FBD_HL,FBD_HM,FBD_HR,FBD_MM,FBD_Miko,FBD_Trunk,FBD_VM,FBD_VR,IPB_App1
 SG_ SeamlessBLEStatusFBD_VL_Connec_7 : 56|8@1+ (1.0,0) [0|252] "" FBD_HL,FBD_HM,FBD_HR,FBD_MM,FBD_Miko,FBD_Trunk,FBD_VM,FBD_VR,IPB_App1
 SG_ SeamlessBLEStatusFBD_VL_Connec_8 : 64|8@1+ (0.5,-127) [-127|-1] "dB" FBD_HL,FBD_HM,FBD_HR,FBD_MM,FBD_Miko,FBD_Trunk,FBD_VM,FBD_VR,IPB_App1
 SG_ SeamlessBLEStatusFBD_VL_Connec_9 : 72|8@1+ (1.0,0) [0|252] "" FBD_HL,FBD_HM,FBD_HR,FBD_MM,FBD_Miko,FBD_Trunk,FBD_VM,FBD_VR,IPB_App1
 SG_ SeamlessBLEStatusFBD_VL_Conne_10 : 80|8@1+ (0.5,-127) [-127|-1] "dB" FBD_HL,FBD_HM,FBD_HR,FBD_MM,FBD_Miko,FBD_Trunk,FBD_VM,FBD_VR,IPB_App1
 SG_ SeamlessBLEStatusFBD_VL_Conne_11 : 88|8@1+ (1.0,0) [0|252] "" FBD_HL,FBD_HM,FBD_HR,FBD_MM,FBD_Miko,FBD_Trunk,FBD_VM,FBD_VR,IPB_App1
 SG_ SeamlessBLEStatusFBD_VL_Conne_12 : 96|8@1+ (0.5,-127) [-127|-1] "dB" FBD_HL,FBD_HM,FBD_HR,FBD_MM,FBD_Miko,FBD_Trunk,FBD_VM,FBD_VR,IPB_App1
 SG_ SeamlessBLEStatusFBD_VL_Conne_13 : 104|8@1+ (1.0,0) [0|252] "" FBD_HL,FBD_HM,FBD_HR,FBD_MM,FBD_Miko,FBD_Trunk,FBD_VM,FBD_VR,IPB_App1
 SG_ SeamlessBLEStatusFBD_VL_Conne_14 : 112|8@1+ (0.5,-127) [-127|-1] "dB" FBD_HL,FBD_HM,FBD_HR,FBD_MM,FBD_Miko,FBD_Trunk,FBD_VM,FBD_VR,IPB_App1
 SG_ SeamlessBLEStatusFBD_VL_Conne_15 : 120|8@1+ (1.0,0) [0|252] "" FBD_HL,FBD_HM,FBD_HR,FBD_MM,FBD_Miko,FBD_Trunk,FBD_VM,FBD_VR,IPB_App1
 SG_ SeamlessBLEStatusFBD_VL_Conne_16 : 128|8@1+ (0.5,-127) [-127|-1] "dB" FBD_HL,FBD_HM,FBD_HR,FBD_MM,FBD_Miko,FBD_Trunk,FBD_VM,FBD_VR,IPB_App1

BO_ 270 SeamlessBLEStatusFBD_VM: 20 FBD_VM
 SG_ SeamlessBLEStatusFBD_VM_NumberAc : 0|8@1+ (1.0,0) [0|252] "" FBD_HL,FBD_HM,FBD_HR,FBD_MM,FBD_Miko,FBD_Trunk,FBD_VL,FBD_VR,IPB_App1
 SG_ SeamlessBLEStatusFBD_VM_Connecti : 8|8@1+ (1.0,0) [0|252] "" FBD_HL,FBD_HM,FBD_HR,FBD_MM,FBD_Miko,FBD_Trunk,FBD_VL,FBD_VR,IPB_App1
 SG_ SeamlessBLEStatusFBD_VM_Connec_2 : 16|8@1+ (0.5,-127) [-127|-1] "dB" FBD_HL,FBD_HM,FBD_HR,FBD_MM,FBD_Miko,FBD_Trunk,FBD_VL,FBD_VR,IPB_App1
 SG_ SeamlessBLEStatusFBD_VM_Connec_3 : 24|8@1+ (1.0,0) [0|252] "" FBD_HL,FBD_HM,FBD_HR,FBD_MM,FBD_Miko,FBD_Trunk,FBD_VL,FBD_VR,IPB_App1
 SG_ SeamlessBLEStatusFBD_VM_Connec_4 : 32|8@1+ (0.5,-127) [-127|-1] "dB" FBD_HL,FBD_HM,FBD_HR,FBD_MM,FBD_Miko,FBD_Trunk,FBD_VL,FBD_VR,IPB_App1
 SG_ SeamlessBLEStatusFBD_VM_Connec_5 : 40|8@1+ (1.0,0) [0|252] "" FBD_HL,FBD_HM,FBD_HR,FBD_MM,FBD_Miko,FBD_Trunk,FBD_VL,FBD_VR,IPB_App1
 SG_ SeamlessBLEStatusFBD_VM_Connec_6 : 48|8@1+ (0.5,-127) [-127|-1] "dB" FBD_HL,FBD_HM,FBD_HR,FBD_MM,FBD_Miko,FBD_Trunk,FBD_VL,FBD_VR,IPB_App1
 SG_ SeamlessBLEStatusFBD_VM_Connec_7 : 56|8@1+ (1.0,0) [0|252] "" FBD_HL,FBD_HM,FBD_HR,FBD_MM,FBD_Miko,FBD_Trunk,FBD_VL,FBD_VR,IPB_App1
 SG_ SeamlessBLEStatusFBD_VM_Connec_8 : 64|8@1+ (0.5,-127) [-127|-1] "dB" FBD_HL,FBD_HM,FBD_HR,FBD_MM,FBD_Miko,FBD_Trunk,FBD_VL,FBD_VR,IPB_App1
 SG_ SeamlessBLEStatusFBD_VM_Connec_9 : 72|8@1+ (1.0,0) [0|252] "" FBD_HL,FBD_HM,FBD_HR,FBD_MM,FBD_Miko,FBD_Trunk,FBD_VL,FBD_VR,IPB_App1
 SG_ SeamlessBLEStatusFBD_VM_Conne_10 : 80|8@1+ (0.5,-127) [-127|-1] "dB" FBD_HL,FBD_HM,FBD_HR,FBD_MM,FBD_Miko,FBD_Trunk,FBD_VL,FBD_VR,IPB_App1
 SG_ SeamlessBLEStatusFBD_VM_Conne_11 : 88|8@1+ (1.0,0) [0|252] "" FBD_HL,FBD_HM,FBD_HR,FBD_MM,FBD_Miko,FBD_Trunk,FBD_VL,FBD_VR,IPB_App1
 SG_ SeamlessBLEStatusFBD_VM_Conne_12 : 96|8@1+ (0.5,-127) [-127|-1] "dB" FBD_HL,FBD_HM,FBD_HR,FBD_MM,FBD_Miko,FBD_Trunk,FBD_VL,FBD_VR,IPB_App1
 SG_ SeamlessBLEStatusFBD_VM_Conne_13 : 104|8@1+ (1.0,0) [0|252] "" FBD_HL,FBD_HM,FBD_HR,FBD_MM,FBD_Miko,FBD_Trunk,FBD_VL,FBD_VR,IPB_App1
 SG_ SeamlessBLEStatusFBD_VM_Conne_14 : 112|8@1+ (0.5,-127) [-127|-1] "dB" FBD_HL,FBD_HM,FBD_HR,FBD_MM,FBD_Miko,FBD_Trunk,FBD_VL,FBD_VR,IPB_App1
 SG_ SeamlessBLEStatusFBD_VM_Conne_15 : 120|8@1+ (1.0,0) [0|252] "" FBD_HL,FBD_HM,FBD_HR,FBD_MM,FBD_Miko,FBD_Trunk,FBD_VL,FBD_VR,IPB_App1
 SG_ SeamlessBLEStatusFBD_VM_Conne_16 : 128|8@1+ (0.5,-127) [-127|-1] "dB" FBD_HL,FBD_HM,FBD_HR,FBD_MM,FBD_Miko,FBD_Trunk,FBD_VL,FBD_VR,IPB_App1

BO_ 275 SeamlessBLEStatusFBD_VR: 20 FBD_VR
 SG_ SeamlessBLEStatusFBD_VR_NumberAc : 0|8@1+ (1.0,0) [0|252] "" FBD_HL,FBD_HM,FBD_HR,FBD_MM,FBD_Miko,FBD_Trunk,FBD_VL,FBD_VM,IPB_App1
 SG_ SeamlessBLEStatusFBD_VR_Connecti : 8|8@1+ (1.0,0) [0|252] "" FBD_HL,FBD_HM,FBD_HR,FBD_MM,FBD_Miko,FBD_Trunk,FBD_VL,FBD_VM,IPB_App1
 SG_ SeamlessBLEStatusFBD_VR_Connec_2 : 16|8@1+ (0.5,-127) [-127|-1] "dB" FBD_HL,FBD_HM,FBD_HR,FBD_MM,FBD_Miko,FBD_Trunk,FBD_VL,FBD_VM,IPB_App1
 SG_ SeamlessBLEStatusFBD_VR_Connec_3 : 24|8@1+ (1.0,0) [0|252] "" FBD_HL,FBD_HM,FBD_HR,FBD_MM,FBD_Miko,FBD_Trunk,FBD_VL,FBD_VM,IPB_App1
 SG_ SeamlessBLEStatusFBD_VR_Connec_4 : 32|8@1+ (0.5,-127) [-127|-1] "dB" FBD_HL,FBD_HM,FBD_HR,FBD_MM,FBD_Miko,FBD_Trunk,FBD_VL,FBD_VM,IPB_App1
 SG_ SeamlessBLEStatusFBD_VR_Connec_5 : 40|8@1+ (1.0,0) [0|252] "" FBD_HL,FBD_HM,FBD_HR,FBD_MM,FBD_Miko,FBD_Trunk,FBD_VL,FBD_VM,IPB_App1
 SG_ SeamlessBLEStatusFBD_VR_Connec_6 : 48|8@1+ (0.5,-127) [-127|-1] "dB" FBD_HL,FBD_HM,FBD_HR,FBD_MM,FBD_Miko,FBD_Trunk,FBD_VL,FBD_VM,IPB_App1
 SG_ SeamlessBLEStatusFBD_VR_Connec_7 : 56|8@1+ (1.0,0) [0|252] "" FBD_HL,FBD_HM,FBD_HR,FBD_MM,FBD_Miko,FBD_Trunk,FBD_VL,FBD_VM,IPB_App1
 SG_ SeamlessBLEStatusFBD_VR_Connec_8 : 64|8@1+ (0.5,-127) [-127|-1] "dB" FBD_HL,FBD_HM,FBD_HR,FBD_MM,FBD_Miko,FBD_Trunk,FBD_VL,FBD_VM,IPB_App1
 SG_ SeamlessBLEStatusFBD_VR_Connec_9 : 72|8@1+ (1.0,0) [0|252] "" FBD_HL,FBD_HM,FBD_HR,FBD_MM,FBD_Miko,FBD_Trunk,FBD_VL,FBD_VM,IPB_App1
 SG_ SeamlessBLEStatusFBD_VR_Conne_10 : 80|8@1+ (0.5,-127) [-127|-1] "dB" FBD_HL,FBD_HM,FBD_HR,FBD_MM,FBD_Miko,FBD_Trunk,FBD_VL,FBD_VM,IPB_App1
 SG_ SeamlessBLEStatusFBD_VR_Conne_11 : 88|8@1+ (1.0,0) [0|252] "" FBD_HL,FBD_HM,FBD_HR,FBD_MM,FBD_Miko,FBD_Trunk,FBD_VL,FBD_VM,IPB_App1
 SG_ SeamlessBLEStatusFBD_VR_Conne_12 : 96|8@1+ (0.5,-127) [-127|-1] "dB" FBD_HL,FBD_HM,FBD_HR,FBD_MM,FBD_Miko,FBD_Trunk,FBD_VL,FBD_VM,IPB_App1
 SG_ SeamlessBLEStatusFBD_VR_Conne_13 : 104|8@1+ (1.0,0) [0|252] "" FBD_HL,FBD_HM,FBD_HR,FBD_MM,FBD_Miko,FBD_Trunk,FBD_VL,FBD_VM,IPB_App1
 SG_ SeamlessBLEStatusFBD_VR_Conne_14 : 112|8@1+ (0.5,-127) [-127|-1] "dB" FBD_HL,FBD_HM,FBD_HR,FBD_MM,FBD_Miko,FBD_Trunk,FBD_VL,FBD_VM,IPB_App1
 SG_ SeamlessBLEStatusFBD_VR_Conne_15 : 120|8@1+ (1.0,0) [0|252] "" FBD_HL,FBD_HM,FBD_HR,FBD_MM,FBD_Miko,FBD_Trunk,FBD_VL,FBD_VM,IPB_App1
 SG_ SeamlessBLEStatusFBD_VR_Conne_16 : 128|8@1+ (0.5,-127) [-127|-1] "dB" FBD_HL,FBD_HM,FBD_HR,FBD_MM,FBD_Miko,FBD_Trunk,FBD_VL,FBD_VM,IPB_App1

BO_ 626 StatusBindingFBD_HL: 64 FBD_HL
 SG_ StatusBindingFBD_HL_BindingStatu : 0|8@1+ (1.0,0) [0|252] "" IPB_App1
 SG_ StatusBindingFBD_HL_BindingCount : 8|8@1+ (1.0,0) [0|252] "" IPB_App1
 SG_ StatusBindingFBD_HL_BindingSeque : 16|8@1+ (1.0,0) [0|252] "" IPB_App1
 SG_ StatusBindingFBD_HL_Data00 : 24|8@1+ (1.0,0) [0|255] "" IPB_App1
 SG_ StatusBindingFBD_HL_Data01 : 32|8@1+ (1.0,0) [0|255] "" IPB_App1
 SG_ StatusBindingFBD_HL_Data02 : 40|8@1+ (1.0,0) [0|255] "" IPB_App1
 SG_ StatusBindingFBD_HL_Data03 : 48|8@1+ (1.0,0) [0|255] "" IPB_App1
 SG_ StatusBindingFBD_HL_Data04 : 56|8@1+ (1.0,0) [0|255] "" IPB_App1
 SG_ StatusBindingFBD_HL_Data05 : 64|8@1+ (1.0,0) [0|255] "" IPB_App1
 SG_ StatusBindingFBD_HL_Data06 : 72|8@1+ (1.0,0) [0|255] "" IPB_App1
 SG_ StatusBindingFBD_HL_Data07 : 80|8@1+ (1.0,0) [0|255] "" IPB_App1
 SG_ StatusBindingFBD_HL_Data08 : 88|8@1+ (1.0,0) [0|255] "" IPB_App1
 SG_ StatusBindingFBD_HL_Data09 : 96|8@1+ (1.0,0) [0|255] "" IPB_App1
 SG_ StatusBindingFBD_HL_Data10 : 104|8@1+ (1.0,0) [0|255] "" IPB_App1
 SG_ StatusBindingFBD_HL_Data11 : 112|8@1+ (1.0,0) [0|255] "" IPB_App1
 SG_ StatusBindingFBD_HL_Data12 : 120|8@1+ (1.0,0) [0|255] "" IPB_App1
 SG_ StatusBindingFBD_HL_Data13 : 128|8@1+ (1.0,0) [0|255] "" IPB_App1
 SG_ StatusBindingFBD_HL_Data14 : 136|8@1+ (1.0,0) [0|255] "" IPB_App1
 SG_ StatusBindingFBD_HL_Data15 : 144|8@1+ (1.0,0) [0|255] "" IPB_App1
 SG_ StatusBindingFBD_HL_Data16 : 152|8@1+ (1.0,0) [0|255] "" IPB_App1
 SG_ StatusBindingFBD_HL_Data17 : 160|8@1+ (1.0,0) [0|255] "" IPB_App1
 SG_ StatusBindingFBD_HL_Data18 : 168|8@1+ (1.0,0) [0|255] "" IPB_App1
 SG_ StatusBindingFBD_HL_Data19 : 176|8@1+ (1.0,0) [0|255] "" IPB_App1
 SG_ StatusBindingFBD_HL_Data20 : 184|8@1+ (1.0,0) [0|255] "" IPB_App1
 SG_ StatusBindingFBD_HL_Data21 : 192|8@1+ (1.0,0) [0|255] "" IPB_App1
 SG_ StatusBindingFBD_HL_Data22 : 200|8@1+ (1.0,0) [0|255] "" IPB_App1
 SG_ StatusBindingFBD_HL_Data23 : 208|8@1+ (1.0,0) [0|255] "" IPB_App1
 SG_ StatusBindingFBD_HL_Data24 : 216|8@1+ (1.0,0) [0|255] "" IPB_App1
 SG_ StatusBindingFBD_HL_Data25 : 224|8@1+ (1.0,0) [0|255] "" IPB_App1
 SG_ StatusBindingFBD_HL_Data26 : 232|8@1+ (1.0,0) [0|255] "" IPB_App1
 SG_ StatusBindingFBD_HL_Data27 : 240|8@1+ (1.0,0) [0|255] "" IPB_App1
 SG_ StatusBindingFBD_HL_Data28 : 248|8@1+ (1.0,0) [0|255] "" IPB_App1
 SG_ StatusBindingFBD_HL_Data29 : 256|8@1+ (1.0,0) [0|255] "" IPB_App1
 SG_ StatusBindingFBD_HL_Data30 : 264|8@1+ (1.0,0) [0|255] "" IPB_App1
 SG_ StatusBindingFBD_HL_Data31 : 272|8@1+ (1.0,0) [0|255] "" IPB_App1
 SG_ StatusBindingFBD_HL_Data32 : 280|8@1+ (1.0,0) [0|255] "" IPB_App1
 SG_ StatusBindingFBD_HL_Data33 : 288|8@1+ (1.0,0) [0|255] "" IPB_App1
 SG_ StatusBindingFBD_HL_Data34 : 296|8@1+ (1.0,0) [0|255] "" IPB_App1
 SG_ StatusBindingFBD_HL_Data35 : 304|8@1+ (1.0,0) [0|255] "" IPB_App1
 SG_ StatusBindingFBD_HL_Data36 : 312|8@1+ (1.0,0) [0|255] "" IPB_App1
 SG_ StatusBindingFBD_HL_Data37 : 320|8@1+ (1.0,0) [0|255] "" IPB_App1
 SG_ StatusBindingFBD_HL_Data38 : 328|8@1+ (1.0,0) [0|255] "" IPB_App1
 SG_ StatusBindingFBD_HL_Data39 : 336|8@1+ (1.0,0) [0|255] "" IPB_App1
 SG_ StatusBindingFBD_HL_Data40 : 344|8@1+ (1.0,0) [0|255] "" IPB_App1
 SG_ StatusBindingFBD_HL_Data41 : 352|8@1+ (1.0,0) [0|255] "" IPB_App1
 SG_ StatusBindingFBD_HL_Data42 : 360|8@1+ (1.0,0) [0|255] "" IPB_App1
 SG_ StatusBindingFBD_HL_Data43 : 368|8@1+ (1.0,0) [0|255] "" IPB_App1
 SG_ StatusBindingFBD_HL_Data44 : 376|8@1+ (1.0,0) [0|255] "" IPB_App1
 SG_ StatusBindingFBD_HL_Data45 : 384|8@1+ (1.0,0) [0|255] "" IPB_App1
 SG_ StatusBindingFBD_HL_Data46 : 392|8@1+ (1.0,0) [0|255] "" IPB_App1
 SG_ StatusBindingFBD_HL_Data47 : 400|8@1+ (1.0,0) [0|255] "" IPB_App1
 SG_ StatusBindingFBD_HL_Data48 : 408|8@1+ (1.0,0) [0|255] "" IPB_App1
 SG_ StatusBindingFBD_HL_Data49 : 416|8@1+ (1.0,0) [0|255] "" IPB_App1
 SG_ StatusBindingFBD_HL_Data50 : 424|8@1+ (1.0,0) [0|255] "" IPB_App1
 SG_ StatusBindingFBD_HL_Data51 : 432|8@1+ (1.0,0) [0|255] "" IPB_App1
 SG_ StatusBindingFBD_HL_Data52 : 440|8@1+ (1.0,0) [0|255] "" IPB_App1
 SG_ StatusBindingFBD_HL_Data53 : 448|8@1+ (1.0,0) [0|255] "" IPB_App1
 SG_ StatusBindingFBD_HL_Data54 : 456|8@1+ (1.0,0) [0|255] "" IPB_App1
 SG_ StatusBindingFBD_HL_Data55 : 464|8@1+ (1.0,0) [0|255] "" IPB_App1
 SG_ StatusBindingFBD_HL_Data56 : 472|8@1+ (1.0,0) [0|255] "" IPB_App1
 SG_ StatusBindingFBD_HL_Data57 : 480|8@1+ (1.0,0) [0|255] "" IPB_App1
 SG_ StatusBindingFBD_HL_Data58 : 488|8@1+ (1.0,0) [0|255] "" IPB_App1
 SG_ StatusBindingFBD_HL_Data59 : 496|8@1+ (1.0,0) [0|255] "" IPB_App1
 SG_ StatusBindingFBD_HL_Data60 : 504|8@1+ (1.0,0) [0|255] "" IPB_App1

BO_ 621 StatusBindingFBD_HM: 64 FBD_HM
 SG_ StatusBindingFBD_HM_BindingStatu : 0|8@1+ (1.0,0) [0|252] "" IPB_App1
 SG_ StatusBindingFBD_HM_BindingCount : 8|8@1+ (1.0,0) [0|252] "" IPB_App1
 SG_ StatusBindingFBD_HM_BindingSeque : 16|8@1+ (1.0,0) [0|252] "" IPB_App1
 SG_ StatusBindingFBD_HM_Data00 : 24|8@1+ (1.0,0) [0|255] "" IPB_App1
 SG_ StatusBindingFBD_HM_Data01 : 32|8@1+ (1.0,0) [0|255] "" IPB_App1
 SG_ StatusBindingFBD_HM_Data02 : 40|8@1+ (1.0,0) [0|255] "" IPB_App1
 SG_ StatusBindingFBD_HM_Data03 : 48|8@1+ (1.0,0) [0|255] "" IPB_App1
 SG_ StatusBindingFBD_HM_Data04 : 56|8@1+ (1.0,0) [0|255] "" IPB_App1
 SG_ StatusBindingFBD_HM_Data05 : 64|8@1+ (1.0,0) [0|255] "" IPB_App1
 SG_ StatusBindingFBD_HM_Data06 : 72|8@1+ (1.0,0) [0|255] "" IPB_App1
 SG_ StatusBindingFBD_HM_Data07 : 80|8@1+ (1.0,0) [0|255] "" IPB_App1
 SG_ StatusBindingFBD_HM_Data08 : 88|8@1+ (1.0,0) [0|255] "" IPB_App1
 SG_ StatusBindingFBD_HM_Data09 : 96|8@1+ (1.0,0) [0|255] "" IPB_App1
 SG_ StatusBindingFBD_HM_Data10 : 104|8@1+ (1.0,0) [0|255] "" IPB_App1
 SG_ StatusBindingFBD_HM_Data11 : 112|8@1+ (1.0,0) [0|255] "" IPB_App1
 SG_ StatusBindingFBD_HM_Data12 : 120|8@1+ (1.0,0) [0|255] "" IPB_App1
 SG_ StatusBindingFBD_HM_Data13 : 128|8@1+ (1.0,0) [0|255] "" IPB_App1
 SG_ StatusBindingFBD_HM_Data14 : 136|8@1+ (1.0,0) [0|255] "" IPB_App1
 SG_ StatusBindingFBD_HM_Data15 : 144|8@1+ (1.0,0) [0|255] "" IPB_App1
 SG_ StatusBindingFBD_HM_Data16 : 152|8@1+ (1.0,0) [0|255] "" IPB_App1
 SG_ StatusBindingFBD_HM_Data17 : 160|8@1+ (1.0,0) [0|255] "" IPB_App1
 SG_ StatusBindingFBD_HM_Data18 : 168|8@1+ (1.0,0) [0|255] "" IPB_App1
 SG_ StatusBindingFBD_HM_Data19 : 176|8@1+ (1.0,0) [0|255] "" IPB_App1
 SG_ StatusBindingFBD_HM_Data20 : 184|8@1+ (1.0,0) [0|255] "" IPB_App1
 SG_ StatusBindingFBD_HM_Data21 : 192|8@1+ (1.0,0) [0|255] "" IPB_App1
 SG_ StatusBindingFBD_HM_Data22 : 200|8@1+ (1.0,0) [0|255] "" IPB_App1
 SG_ StatusBindingFBD_HM_Data23 : 208|8@1+ (1.0,0) [0|255] "" IPB_App1
 SG_ StatusBindingFBD_HM_Data24 : 216|8@1+ (1.0,0) [0|255] "" IPB_App1
 SG_ StatusBindingFBD_HM_Data25 : 224|8@1+ (1.0,0) [0|255] "" IPB_App1
 SG_ StatusBindingFBD_HM_Data26 : 232|8@1+ (1.0,0) [0|255] "" IPB_App1
 SG_ StatusBindingFBD_HM_Data27 : 240|8@1+ (1.0,0) [0|255] "" IPB_App1
 SG_ StatusBindingFBD_HM_Data28 : 248|8@1+ (1.0,0) [0|255] "" IPB_App1
 SG_ StatusBindingFBD_HM_Data29 : 256|8@1+ (1.0,0) [0|255] "" IPB_App1
 SG_ StatusBindingFBD_HM_Data30 : 264|8@1+ (1.0,0) [0|255] "" IPB_App1
 SG_ StatusBindingFBD_HM_Data31 : 272|8@1+ (1.0,0) [0|255] "" IPB_App1
 SG_ StatusBindingFBD_HM_Data32 : 280|8@1+ (1.0,0) [0|255] "" IPB_App1
 SG_ StatusBindingFBD_HM_Data33 : 288|8@1+ (1.0,0) [0|255] "" IPB_App1
 SG_ StatusBindingFBD_HM_Data34 : 296|8@1+ (1.0,0) [0|255] "" IPB_App1
 SG_ StatusBindingFBD_HM_Data35 : 304|8@1+ (1.0,0) [0|255] "" IPB_App1
 SG_ StatusBindingFBD_HM_Data36 : 312|8@1+ (1.0,0) [0|255] "" IPB_App1
 SG_ StatusBindingFBD_HM_Data37 : 320|8@1+ (1.0,0) [0|255] "" IPB_App1
 SG_ StatusBindingFBD_HM_Data38 : 328|8@1+ (1.0,0) [0|255] "" IPB_App1
 SG_ StatusBindingFBD_HM_Data39 : 336|8@1+ (1.0,0) [0|255] "" IPB_App1
 SG_ StatusBindingFBD_HM_Data40 : 344|8@1+ (1.0,0) [0|255] "" IPB_App1
 SG_ StatusBindingFBD_HM_Data41 : 352|8@1+ (1.0,0) [0|255] "" IPB_App1
 SG_ StatusBindingFBD_HM_Data42 : 360|8@1+ (1.0,0) [0|255] "" IPB_App1
 SG_ StatusBindingFBD_HM_Data43 : 368|8@1+ (1.0,0) [0|255] "" IPB_App1
 SG_ StatusBindingFBD_HM_Data44 : 376|8@1+ (1.0,0) [0|255] "" IPB_App1
 SG_ StatusBindingFBD_HM_Data45 : 384|8@1+ (1.0,0) [0|255] "" IPB_App1
 SG_ StatusBindingFBD_HM_Data46 : 392|8@1+ (1.0,0) [0|255] "" IPB_App1
 SG_ StatusBindingFBD_HM_Data47 : 400|8@1+ (1.0,0) [0|255] "" IPB_App1
 SG_ StatusBindingFBD_HM_Data48 : 408|8@1+ (1.0,0) [0|255] "" IPB_App1
 SG_ StatusBindingFBD_HM_Data49 : 416|8@1+ (1.0,0) [0|255] "" IPB_App1
 SG_ StatusBindingFBD_HM_Data50 : 424|8@1+ (1.0,0) [0|255] "" IPB_App1
 SG_ StatusBindingFBD_HM_Data51 : 432|8@1+ (1.0,0) [0|255] "" IPB_App1
 SG_ StatusBindingFBD_HM_Data52 : 440|8@1+ (1.0,0) [0|255] "" IPB_App1
 SG_ StatusBindingFBD_HM_Data53 : 448|8@1+ (1.0,0) [0|255] "" IPB_App1
 SG_ StatusBindingFBD_HM_Data54 : 456|8@1+ (1.0,0) [0|255] "" IPB_App1
 SG_ StatusBindingFBD_HM_Data55 : 464|8@1+ (1.0,0) [0|255] "" IPB_App1
 SG_ StatusBindingFBD_HM_Data56 : 472|8@1+ (1.0,0) [0|255] "" IPB_App1
 SG_ StatusBindingFBD_HM_Data57 : 480|8@1+ (1.0,0) [0|255] "" IPB_App1
 SG_ StatusBindingFBD_HM_Data58 : 488|8@1+ (1.0,0) [0|255] "" IPB_App1
 SG_ StatusBindingFBD_HM_Data59 : 496|8@1+ (1.0,0) [0|255] "" IPB_App1
 SG_ StatusBindingFBD_HM_Data60 : 504|8@1+ (1.0,0) [0|255] "" IPB_App1

BO_ 627 StatusBindingFBD_HR: 64 FBD_HR
 SG_ StatusBindingFBD_HR_BindingStatu : 0|8@1+ (1.0,0) [0|252] "" IPB_App1
 SG_ StatusBindingFBD_HR_BindingCount : 8|8@1+ (1.0,0) [0|252] "" IPB_App1
 SG_ StatusBindingFBD_HR_BindingSeque : 16|8@1+ (1.0,0) [0|252] "" IPB_App1
 SG_ StatusBindingFBD_HR_Data00 : 24|8@1+ (1.0,0) [0|255] "" IPB_App1
 SG_ StatusBindingFBD_HR_Data01 : 32|8@1+ (1.0,0) [0|255] "" IPB_App1
 SG_ StatusBindingFBD_HR_Data02 : 40|8@1+ (1.0,0) [0|255] "" IPB_App1
 SG_ StatusBindingFBD_HR_Data03 : 48|8@1+ (1.0,0) [0|255] "" IPB_App1
 SG_ StatusBindingFBD_HR_Data04 : 56|8@1+ (1.0,0) [0|255] "" IPB_App1
 SG_ StatusBindingFBD_HR_Data05 : 64|8@1+ (1.0,0) [0|255] "" IPB_App1
 SG_ StatusBindingFBD_HR_Data06 : 72|8@1+ (1.0,0) [0|255] "" IPB_App1
 SG_ StatusBindingFBD_HR_Data07 : 80|8@1+ (1.0,0) [0|255] "" IPB_App1
 SG_ StatusBindingFBD_HR_Data08 : 88|8@1+ (1.0,0) [0|255] "" IPB_App1
 SG_ StatusBindingFBD_HR_Data09 : 96|8@1+ (1.0,0) [0|255] "" IPB_App1
 SG_ StatusBindingFBD_HR_Data10 : 104|8@1+ (1.0,0) [0|255] "" IPB_App1
 SG_ StatusBindingFBD_HR_Data11 : 112|8@1+ (1.0,0) [0|255] "" IPB_App1
 SG_ StatusBindingFBD_HR_Data12 : 120|8@1+ (1.0,0) [0|255] "" IPB_App1
 SG_ StatusBindingFBD_HR_Data13 : 128|8@1+ (1.0,0) [0|255] "" IPB_App1
 SG_ StatusBindingFBD_HR_Data14 : 136|8@1+ (1.0,0) [0|255] "" IPB_App1
 SG_ StatusBindingFBD_HR_Data15 : 144|8@1+ (1.0,0) [0|255] "" IPB_App1
 SG_ StatusBindingFBD_HR_Data16 : 152|8@1+ (1.0,0) [0|255] "" IPB_App1
 SG_ StatusBindingFBD_HR_Data17 : 160|8@1+ (1.0,0) [0|255] "" IPB_App1
 SG_ StatusBindingFBD_HR_Data18 : 168|8@1+ (1.0,0) [0|255] "" IPB_App1
 SG_ StatusBindingFBD_HR_Data19 : 176|8@1+ (1.0,0) [0|255] "" IPB_App1
 SG_ StatusBindingFBD_HR_Data20 : 184|8@1+ (1.0,0) [0|255] "" IPB_App1
 SG_ StatusBindingFBD_HR_Data21 : 192|8@1+ (1.0,0) [0|255] "" IPB_App1
 SG_ StatusBindingFBD_HR_Data22 : 200|8@1+ (1.0,0) [0|255] "" IPB_App1
 SG_ StatusBindingFBD_HR_Data23 : 208|8@1+ (1.0,0) [0|255] "" IPB_App1
 SG_ StatusBindingFBD_HR_Data24 : 216|8@1+ (1.0,0) [0|255] "" IPB_App1
 SG_ StatusBindingFBD_HR_Data25 : 224|8@1+ (1.0,0) [0|255] "" IPB_App1
 SG_ StatusBindingFBD_HR_Data26 : 232|8@1+ (1.0,0) [0|255] "" IPB_App1
 SG_ StatusBindingFBD_HR_Data27 : 240|8@1+ (1.0,0) [0|255] "" IPB_App1
 SG_ StatusBindingFBD_HR_Data28 : 248|8@1+ (1.0,0) [0|255] "" IPB_App1
 SG_ StatusBindingFBD_HR_Data29 : 256|8@1+ (1.0,0) [0|255] "" IPB_App1
 SG_ StatusBindingFBD_HR_Data30 : 264|8@1+ (1.0,0) [0|255] "" IPB_App1
 SG_ StatusBindingFBD_HR_Data31 : 272|8@1+ (1.0,0) [0|255] "" IPB_App1
 SG_ StatusBindingFBD_HR_Data32 : 280|8@1+ (1.0,0) [0|255] "" IPB_App1
 SG_ StatusBindingFBD_HR_Data33 : 288|8@1+ (1.0,0) [0|255] "" IPB_App1
 SG_ StatusBindingFBD_HR_Data34 : 296|8@1+ (1.0,0) [0|255] "" IPB_App1
 SG_ StatusBindingFBD_HR_Data35 : 304|8@1+ (1.0,0) [0|255] "" IPB_App1
 SG_ StatusBindingFBD_HR_Data36 : 312|8@1+ (1.0,0) [0|255] "" IPB_App1
 SG_ StatusBindingFBD_HR_Data37 : 320|8@1+ (1.0,0) [0|255] "" IPB_App1
 SG_ StatusBindingFBD_HR_Data38 : 328|8@1+ (1.0,0) [0|255] "" IPB_App1
 SG_ StatusBindingFBD_HR_Data39 : 336|8@1+ (1.0,0) [0|255] "" IPB_App1
 SG_ StatusBindingFBD_HR_Data40 : 344|8@1+ (1.0,0) [0|255] "" IPB_App1
 SG_ StatusBindingFBD_HR_Data41 : 352|8@1+ (1.0,0) [0|255] "" IPB_App1
 SG_ StatusBindingFBD_HR_Data42 : 360|8@1+ (1.0,0) [0|255] "" IPB_App1
 SG_ StatusBindingFBD_HR_Data43 : 368|8@1+ (1.0,0) [0|255] "" IPB_App1
 SG_ StatusBindingFBD_HR_Data44 : 376|8@1+ (1.0,0) [0|255] "" IPB_App1
 SG_ StatusBindingFBD_HR_Data45 : 384|8@1+ (1.0,0) [0|255] "" IPB_App1
 SG_ StatusBindingFBD_HR_Data46 : 392|8@1+ (1.0,0) [0|255] "" IPB_App1
 SG_ StatusBindingFBD_HR_Data47 : 400|8@1+ (1.0,0) [0|255] "" IPB_App1
 SG_ StatusBindingFBD_HR_Data48 : 408|8@1+ (1.0,0) [0|255] "" IPB_App1
 SG_ StatusBindingFBD_HR_Data49 : 416|8@1+ (1.0,0) [0|255] "" IPB_App1
 SG_ StatusBindingFBD_HR_Data50 : 424|8@1+ (1.0,0) [0|255] "" IPB_App1
 SG_ StatusBindingFBD_HR_Data51 : 432|8@1+ (1.0,0) [0|255] "" IPB_App1
 SG_ StatusBindingFBD_HR_Data52 : 440|8@1+ (1.0,0) [0|255] "" IPB_App1
 SG_ StatusBindingFBD_HR_Data53 : 448|8@1+ (1.0,0) [0|255] "" IPB_App1
 SG_ StatusBindingFBD_HR_Data54 : 456|8@1+ (1.0,0) [0|255] "" IPB_App1
 SG_ StatusBindingFBD_HR_Data55 : 464|8@1+ (1.0,0) [0|255] "" IPB_App1
 SG_ StatusBindingFBD_HR_Data56 : 472|8@1+ (1.0,0) [0|255] "" IPB_App1
 SG_ StatusBindingFBD_HR_Data57 : 480|8@1+ (1.0,0) [0|255] "" IPB_App1
 SG_ StatusBindingFBD_HR_Data58 : 488|8@1+ (1.0,0) [0|255] "" IPB_App1
 SG_ StatusBindingFBD_HR_Data59 : 496|8@1+ (1.0,0) [0|255] "" IPB_App1
 SG_ StatusBindingFBD_HR_Data60 : 504|8@1+ (1.0,0) [0|255] "" IPB_App1

BO_ 622 StatusBindingFBD_Miko: 64 FBD_Miko
 SG_ StatusBindingFBD_Miko_BindingSta : 0|8@1+ (1.0,0) [0|252] "" IPB_App1
 SG_ StatusBindingFBD_Miko_BindingCou : 8|8@1+ (1.0,0) [0|252] "" IPB_App1
 SG_ StatusBindingFBD_Miko_BindingSeq : 16|8@1+ (1.0,0) [0|252] "" IPB_App1
 SG_ StatusBindingFBD_Miko_Data00 : 24|8@1+ (1.0,0) [0|255] "" IPB_App1
 SG_ StatusBindingFBD_Miko_Data01 : 32|8@1+ (1.0,0) [0|255] "" IPB_App1
 SG_ StatusBindingFBD_Miko_Data02 : 40|8@1+ (1.0,0) [0|255] "" IPB_App1
 SG_ StatusBindingFBD_Miko_Data03 : 48|8@1+ (1.0,0) [0|255] "" IPB_App1
 SG_ StatusBindingFBD_Miko_Data04 : 56|8@1+ (1.0,0) [0|255] "" IPB_App1
 SG_ StatusBindingFBD_Miko_Data05 : 64|8@1+ (1.0,0) [0|255] "" IPB_App1
 SG_ StatusBindingFBD_Miko_Data06 : 72|8@1+ (1.0,0) [0|255] "" IPB_App1
 SG_ StatusBindingFBD_Miko_Data07 : 80|8@1+ (1.0,0) [0|255] "" IPB_App1
 SG_ StatusBindingFBD_Miko_Data08 : 88|8@1+ (1.0,0) [0|255] "" IPB_App1
 SG_ StatusBindingFBD_Miko_Data09 : 96|8@1+ (1.0,0) [0|255] "" IPB_App1
 SG_ StatusBindingFBD_Miko_Data10 : 104|8@1+ (1.0,0) [0|255] "" IPB_App1
 SG_ StatusBindingFBD_Miko_Data11 : 112|8@1+ (1.0,0) [0|255] "" IPB_App1
 SG_ StatusBindingFBD_Miko_Data12 : 120|8@1+ (1.0,0) [0|255] "" IPB_App1
 SG_ StatusBindingFBD_Miko_Data13 : 128|8@1+ (1.0,0) [0|255] "" IPB_App1
 SG_ StatusBindingFBD_Miko_Data14 : 136|8@1+ (1.0,0) [0|255] "" IPB_App1
 SG_ StatusBindingFBD_Miko_Data15 : 144|8@1+ (1.0,0) [0|255] "" IPB_App1
 SG_ StatusBindingFBD_Miko_Data16 : 152|8@1+ (1.0,0) [0|255] "" IPB_App1
 SG_ StatusBindingFBD_Miko_Data17 : 160|8@1+ (1.0,0) [0|255] "" IPB_App1
 SG_ StatusBindingFBD_Miko_Data18 : 168|8@1+ (1.0,0) [0|255] "" IPB_App1
 SG_ StatusBindingFBD_Miko_Data19 : 176|8@1+ (1.0,0) [0|255] "" IPB_App1
 SG_ StatusBindingFBD_Miko_Data20 : 184|8@1+ (1.0,0) [0|255] "" IPB_App1
 SG_ StatusBindingFBD_Miko_Data21 : 192|8@1+ (1.0,0) [0|255] "" IPB_App1
 SG_ StatusBindingFBD_Miko_Data22 : 200|8@1+ (1.0,0) [0|255] "" IPB_App1
 SG_ StatusBindingFBD_Miko_Data23 : 208|8@1+ (1.0,0) [0|255] "" IPB_App1
 SG_ StatusBindingFBD_Miko_Data24 : 216|8@1+ (1.0,0) [0|255] "" IPB_App1
 SG_ StatusBindingFBD_Miko_Data25 : 224|8@1+ (1.0,0) [0|255] "" IPB_App1
 SG_ StatusBindingFBD_Miko_Data26 : 232|8@1+ (1.0,0) [0|255] "" IPB_App1
 SG_ StatusBindingFBD_Miko_Data27 : 240|8@1+ (1.0,0) [0|255] "" IPB_App1
 SG_ StatusBindingFBD_Miko_Data28 : 248|8@1+ (1.0,0) [0|255] "" IPB_App1
 SG_ StatusBindingFBD_Miko_Data29 : 256|8@1+ (1.0,0) [0|255] "" IPB_App1
 SG_ StatusBindingFBD_Miko_Data30 : 264|8@1+ (1.0,0) [0|255] "" IPB_App1
 SG_ StatusBindingFBD_Miko_Data31 : 272|8@1+ (1.0,0) [0|255] "" IPB_App1
 SG_ StatusBindingFBD_Miko_Data32 : 280|8@1+ (1.0,0) [0|255] "" IPB_App1
 SG_ StatusBindingFBD_Miko_Data33 : 288|8@1+ (1.0,0) [0|255] "" IPB_App1
 SG_ StatusBindingFBD_Miko_Data34 : 296|8@1+ (1.0,0) [0|255] "" IPB_App1
 SG_ StatusBindingFBD_Miko_Data35 : 304|8@1+ (1.0,0) [0|255] "" IPB_App1
 SG_ StatusBindingFBD_Miko_Data36 : 312|8@1+ (1.0,0) [0|255] "" IPB_App1
 SG_ StatusBindingFBD_Miko_Data37 : 320|8@1+ (1.0,0) [0|255] "" IPB_App1
 SG_ StatusBindingFBD_Miko_Data38 : 328|8@1+ (1.0,0) [0|255] "" IPB_App1
 SG_ StatusBindingFBD_Miko_Data39 : 336|8@1+ (1.0,0) [0|255] "" IPB_App1
 SG_ StatusBindingFBD_Miko_Data40 : 344|8@1+ (1.0,0) [0|255] "" IPB_App1
 SG_ StatusBindingFBD_Miko_Data41 : 352|8@1+ (1.0,0) [0|255] "" IPB_App1
 SG_ StatusBindingFBD_Miko_Data42 : 360|8@1+ (1.0,0) [0|255] "" IPB_App1
 SG_ StatusBindingFBD_Miko_Data43 : 368|8@1+ (1.0,0) [0|255] "" IPB_App1
 SG_ StatusBindingFBD_Miko_Data44 : 376|8@1+ (1.0,0) [0|255] "" IPB_App1
 SG_ StatusBindingFBD_Miko_Data45 : 384|8@1+ (1.0,0) [0|255] "" IPB_App1
 SG_ StatusBindingFBD_Miko_Data46 : 392|8@1+ (1.0,0) [0|255] "" IPB_App1
 SG_ StatusBindingFBD_Miko_Data47 : 400|8@1+ (1.0,0) [0|255] "" IPB_App1
 SG_ StatusBindingFBD_Miko_Data48 : 408|8@1+ (1.0,0) [0|255] "" IPB_App1
 SG_ StatusBindingFBD_Miko_Data49 : 416|8@1+ (1.0,0) [0|255] "" IPB_App1
 SG_ StatusBindingFBD_Miko_Data50 : 424|8@1+ (1.0,0) [0|255] "" IPB_App1
 SG_ StatusBindingFBD_Miko_Data51 : 432|8@1+ (1.0,0) [0|255] "" IPB_App1
 SG_ StatusBindingFBD_Miko_Data52 : 440|8@1+ (1.0,0) [0|255] "" IPB_App1
 SG_ StatusBindingFBD_Miko_Data53 : 448|8@1+ (1.0,0) [0|255] "" IPB_App1
 SG_ StatusBindingFBD_Miko_Data54 : 456|8@1+ (1.0,0) [0|255] "" IPB_App1
 SG_ StatusBindingFBD_Miko_Data55 : 464|8@1+ (1.0,0) [0|255] "" IPB_App1
 SG_ StatusBindingFBD_Miko_Data56 : 472|8@1+ (1.0,0) [0|255] "" IPB_App1
 SG_ StatusBindingFBD_Miko_Data57 : 480|8@1+ (1.0,0) [0|255] "" IPB_App1
 SG_ StatusBindingFBD_Miko_Data58 : 488|8@1+ (1.0,0) [0|255] "" IPB_App1
 SG_ StatusBindingFBD_Miko_Data59 : 496|8@1+ (1.0,0) [0|255] "" IPB_App1
 SG_ StatusBindingFBD_Miko_Data60 : 504|8@1+ (1.0,0) [0|255] "" IPB_App1

BO_ 862 StatusBindingFBD_MM: 64 FBD_MM
 SG_ StatusBindingFBD_MM_BindingStatu : 0|8@1+ (1.0,0) [0|252] "" IPB_App1
 SG_ StatusBindingFBD_MM_BindingCount : 8|8@1+ (1.0,0) [0|252] "" IPB_App1
 SG_ StatusBindingFBD_MM_BindingSeque : 16|8@1+ (1.0,0) [0|252] "" IPB_App1
 SG_ StatusBindingFBD_MM_Data00 : 24|8@1+ (1.0,0) [0|255] "" IPB_App1
 SG_ StatusBindingFBD_MM_Data01 : 32|8@1+ (1.0,0) [0|255] "" IPB_App1
 SG_ StatusBindingFBD_MM_Data02 : 40|8@1+ (1.0,0) [0|255] "" IPB_App1
 SG_ StatusBindingFBD_MM_Data03 : 48|8@1+ (1.0,0) [0|255] "" IPB_App1
 SG_ StatusBindingFBD_MM_Data04 : 56|8@1+ (1.0,0) [0|255] "" IPB_App1
 SG_ StatusBindingFBD_MM_Data05 : 64|8@1+ (1.0,0) [0|255] "" IPB_App1
 SG_ StatusBindingFBD_MM_Data06 : 72|8@1+ (1.0,0) [0|255] "" IPB_App1
 SG_ StatusBindingFBD_MM_Data07 : 80|8@1+ (1.0,0) [0|255] "" IPB_App1
 SG_ StatusBindingFBD_MM_Data08 : 88|8@1+ (1.0,0) [0|255] "" IPB_App1
 SG_ StatusBindingFBD_MM_Data09 : 96|8@1+ (1.0,0) [0|255] "" IPB_App1
 SG_ StatusBindingFBD_MM_Data10 : 104|8@1+ (1.0,0) [0|255] "" IPB_App1
 SG_ StatusBindingFBD_MM_Data11 : 112|8@1+ (1.0,0) [0|255] "" IPB_App1
 SG_ StatusBindingFBD_MM_Data12 : 120|8@1+ (1.0,0) [0|255] "" IPB_App1
 SG_ StatusBindingFBD_MM_Data13 : 128|8@1+ (1.0,0) [0|255] "" IPB_App1
 SG_ StatusBindingFBD_MM_Data14 : 136|8@1+ (1.0,0) [0|255] "" IPB_App1
 SG_ StatusBindingFBD_MM_Data15 : 144|8@1+ (1.0,0) [0|255] "" IPB_App1
 SG_ StatusBindingFBD_MM_Data16 : 152|8@1+ (1.0,0) [0|255] "" IPB_App1
 SG_ StatusBindingFBD_MM_Data17 : 160|8@1+ (1.0,0) [0|255] "" IPB_App1
 SG_ StatusBindingFBD_MM_Data18 : 168|8@1+ (1.0,0) [0|255] "" IPB_App1
 SG_ StatusBindingFBD_MM_Data19 : 176|8@1+ (1.0,0) [0|255] "" IPB_App1
 SG_ StatusBindingFBD_MM_Data20 : 184|8@1+ (1.0,0) [0|255] "" IPB_App1
 SG_ StatusBindingFBD_MM_Data21 : 192|8@1+ (1.0,0) [0|255] "" IPB_App1
 SG_ StatusBindingFBD_MM_Data22 : 200|8@1+ (1.0,0) [0|255] "" IPB_App1
 SG_ StatusBindingFBD_MM_Data23 : 208|8@1+ (1.0,0) [0|255] "" IPB_App1
 SG_ StatusBindingFBD_MM_Data24 : 216|8@1+ (1.0,0) [0|255] "" IPB_App1
 SG_ StatusBindingFBD_MM_Data25 : 224|8@1+ (1.0,0) [0|255] "" IPB_App1
 SG_ StatusBindingFBD_MM_Data26 : 232|8@1+ (1.0,0) [0|255] "" IPB_App1
 SG_ StatusBindingFBD_MM_Data27 : 240|8@1+ (1.0,0) [0|255] "" IPB_App1
 SG_ StatusBindingFBD_MM_Data28 : 248|8@1+ (1.0,0) [0|255] "" IPB_App1
 SG_ StatusBindingFBD_MM_Data29 : 256|8@1+ (1.0,0) [0|255] "" IPB_App1
 SG_ StatusBindingFBD_MM_Data30 : 264|8@1+ (1.0,0) [0|255] "" IPB_App1
 SG_ StatusBindingFBD_MM_Data31 : 272|8@1+ (1.0,0) [0|255] "" IPB_App1
 SG_ StatusBindingFBD_MM_Data32 : 280|8@1+ (1.0,0) [0|255] "" IPB_App1
 SG_ StatusBindingFBD_MM_Data33 : 288|8@1+ (1.0,0) [0|255] "" IPB_App1
 SG_ StatusBindingFBD_MM_Data34 : 296|8@1+ (1.0,0) [0|255] "" IPB_App1
 SG_ StatusBindingFBD_MM_Data35 : 304|8@1+ (1.0,0) [0|255] "" IPB_App1
 SG_ StatusBindingFBD_MM_Data36 : 312|8@1+ (1.0,0) [0|255] "" IPB_App1
 SG_ StatusBindingFBD_MM_Data37 : 320|8@1+ (1.0,0) [0|255] "" IPB_App1
 SG_ StatusBindingFBD_MM_Data38 : 328|8@1+ (1.0,0) [0|255] "" IPB_App1
 SG_ StatusBindingFBD_MM_Data39 : 336|8@1+ (1.0,0) [0|255] "" IPB_App1
 SG_ StatusBindingFBD_MM_Data40 : 344|8@1+ (1.0,0) [0|255] "" IPB_App1
 SG_ StatusBindingFBD_MM_Data41 : 352|8@1+ (1.0,0) [0|255] "" IPB_App1
 SG_ StatusBindingFBD_MM_Data42 : 360|8@1+ (1.0,0) [0|255] "" IPB_App1
 SG_ StatusBindingFBD_MM_Data43 : 368|8@1+ (1.0,0) [0|255] "" IPB_App1
 SG_ StatusBindingFBD_MM_Data44 : 376|8@1+ (1.0,0) [0|255] "" IPB_App1
 SG_ StatusBindingFBD_MM_Data45 : 384|8@1+ (1.0,0) [0|255] "" IPB_App1
 SG_ StatusBindingFBD_MM_Data46 : 392|8@1+ (1.0,0) [0|255] "" IPB_App1
 SG_ StatusBindingFBD_MM_Data47 : 400|8@1+ (1.0,0) [0|255] "" IPB_App1
 SG_ StatusBindingFBD_MM_Data48 : 408|8@1+ (1.0,0) [0|255] "" IPB_App1
 SG_ StatusBindingFBD_MM_Data49 : 416|8@1+ (1.0,0) [0|255] "" IPB_App1
 SG_ StatusBindingFBD_MM_Data50 : 424|8@1+ (1.0,0) [0|255] "" IPB_App1
 SG_ StatusBindingFBD_MM_Data51 : 432|8@1+ (1.0,0) [0|255] "" IPB_App1
 SG_ StatusBindingFBD_MM_Data52 : 440|8@1+ (1.0,0) [0|255] "" IPB_App1
 SG_ StatusBindingFBD_MM_Data53 : 448|8@1+ (1.0,0) [0|255] "" IPB_App1
 SG_ StatusBindingFBD_MM_Data54 : 456|8@1+ (1.0,0) [0|255] "" IPB_App1
 SG_ StatusBindingFBD_MM_Data55 : 464|8@1+ (1.0,0) [0|255] "" IPB_App1
 SG_ StatusBindingFBD_MM_Data56 : 472|8@1+ (1.0,0) [0|255] "" IPB_App1
 SG_ StatusBindingFBD_MM_Data57 : 480|8@1+ (1.0,0) [0|255] "" IPB_App1
 SG_ StatusBindingFBD_MM_Data58 : 488|8@1+ (1.0,0) [0|255] "" IPB_App1
 SG_ StatusBindingFBD_MM_Data59 : 496|8@1+ (1.0,0) [0|255] "" IPB_App1
 SG_ StatusBindingFBD_MM_Data60 : 504|8@1+ (1.0,0) [0|255] "" IPB_App1

BO_ 623 StatusBindingFBD_Trunk: 64 FBD_Trunk
 SG_ StatusBindingFBD_Trunk_BindingSt : 0|8@1+ (1.0,0) [0|252] "" IPB_App1
 SG_ StatusBindingFBD_Trunk_BindingCo : 8|8@1+ (1.0,0) [0|252] "" IPB_App1
 SG_ StatusBindingFBD_Trunk_BindingSe : 16|8@1+ (1.0,0) [0|252] "" IPB_App1
 SG_ StatusBindingFBD_Trunk_Data00 : 24|8@1+ (1.0,0) [0|255] "" IPB_App1
 SG_ StatusBindingFBD_Trunk_Data01 : 32|8@1+ (1.0,0) [0|255] "" IPB_App1
 SG_ StatusBindingFBD_Trunk_Data02 : 40|8@1+ (1.0,0) [0|255] "" IPB_App1
 SG_ StatusBindingFBD_Trunk_Data03 : 48|8@1+ (1.0,0) [0|255] "" IPB_App1
 SG_ StatusBindingFBD_Trunk_Data04 : 56|8@1+ (1.0,0) [0|255] "" IPB_App1
 SG_ StatusBindingFBD_Trunk_Data05 : 64|8@1+ (1.0,0) [0|255] "" IPB_App1
 SG_ StatusBindingFBD_Trunk_Data06 : 72|8@1+ (1.0,0) [0|255] "" IPB_App1
 SG_ StatusBindingFBD_Trunk_Data07 : 80|8@1+ (1.0,0) [0|255] "" IPB_App1
 SG_ StatusBindingFBD_Trunk_Data08 : 88|8@1+ (1.0,0) [0|255] "" IPB_App1
 SG_ StatusBindingFBD_Trunk_Data09 : 96|8@1+ (1.0,0) [0|255] "" IPB_App1
 SG_ StatusBindingFBD_Trunk_Data10 : 104|8@1+ (1.0,0) [0|255] "" IPB_App1
 SG_ StatusBindingFBD_Trunk_Data11 : 112|8@1+ (1.0,0) [0|255] "" IPB_App1
 SG_ StatusBindingFBD_Trunk_Data12 : 120|8@1+ (1.0,0) [0|255] "" IPB_App1
 SG_ StatusBindingFBD_Trunk_Data13 : 128|8@1+ (1.0,0) [0|255] "" IPB_App1
 SG_ StatusBindingFBD_Trunk_Data14 : 136|8@1+ (1.0,0) [0|255] "" IPB_App1
 SG_ StatusBindingFBD_Trunk_Data15 : 144|8@1+ (1.0,0) [0|255] "" IPB_App1
 SG_ StatusBindingFBD_Trunk_Data16 : 152|8@1+ (1.0,0) [0|255] "" IPB_App1
 SG_ StatusBindingFBD_Trunk_Data17 : 160|8@1+ (1.0,0) [0|255] "" IPB_App1
 SG_ StatusBindingFBD_Trunk_Data18 : 168|8@1+ (1.0,0) [0|255] "" IPB_App1
 SG_ StatusBindingFBD_Trunk_Data19 : 176|8@1+ (1.0,0) [0|255] "" IPB_App1
 SG_ StatusBindingFBD_Trunk_Data20 : 184|8@1+ (1.0,0) [0|255] "" IPB_App1
 SG_ StatusBindingFBD_Trunk_Data21 : 192|8@1+ (1.0,0) [0|255] "" IPB_App1
 SG_ StatusBindingFBD_Trunk_Data22 : 200|8@1+ (1.0,0) [0|255] "" IPB_App1
 SG_ StatusBindingFBD_Trunk_Data23 : 208|8@1+ (1.0,0) [0|255] "" IPB_App1
 SG_ StatusBindingFBD_Trunk_Data24 : 216|8@1+ (1.0,0) [0|255] "" IPB_App1
 SG_ StatusBindingFBD_Trunk_Data25 : 224|8@1+ (1.0,0) [0|255] "" IPB_App1
 SG_ StatusBindingFBD_Trunk_Data26 : 232|8@1+ (1.0,0) [0|255] "" IPB_App1
 SG_ StatusBindingFBD_Trunk_Data27 : 240|8@1+ (1.0,0) [0|255] "" IPB_App1
 SG_ StatusBindingFBD_Trunk_Data28 : 248|8@1+ (1.0,0) [0|255] "" IPB_App1
 SG_ StatusBindingFBD_Trunk_Data29 : 256|8@1+ (1.0,0) [0|255] "" IPB_App1
 SG_ StatusBindingFBD_Trunk_Data30 : 264|8@1+ (1.0,0) [0|255] "" IPB_App1
 SG_ StatusBindingFBD_Trunk_Data31 : 272|8@1+ (1.0,0) [0|255] "" IPB_App1
 SG_ StatusBindingFBD_Trunk_Data32 : 280|8@1+ (1.0,0) [0|255] "" IPB_App1
 SG_ StatusBindingFBD_Trunk_Data33 : 288|8@1+ (1.0,0) [0|255] "" IPB_App1
 SG_ StatusBindingFBD_Trunk_Data34 : 296|8@1+ (1.0,0) [0|255] "" IPB_App1
 SG_ StatusBindingFBD_Trunk_Data35 : 304|8@1+ (1.0,0) [0|255] "" IPB_App1
 SG_ StatusBindingFBD_Trunk_Data36 : 312|8@1+ (1.0,0) [0|255] "" IPB_App1
 SG_ StatusBindingFBD_Trunk_Data37 : 320|8@1+ (1.0,0) [0|255] "" IPB_App1
 SG_ StatusBindingFBD_Trunk_Data38 : 328|8@1+ (1.0,0) [0|255] "" IPB_App1
 SG_ StatusBindingFBD_Trunk_Data39 : 336|8@1+ (1.0,0) [0|255] "" IPB_App1
 SG_ StatusBindingFBD_Trunk_Data40 : 344|8@1+ (1.0,0) [0|255] "" IPB_App1
 SG_ StatusBindingFBD_Trunk_Data41 : 352|8@1+ (1.0,0) [0|255] "" IPB_App1
 SG_ StatusBindingFBD_Trunk_Data42 : 360|8@1+ (1.0,0) [0|255] "" IPB_App1
 SG_ StatusBindingFBD_Trunk_Data43 : 368|8@1+ (1.0,0) [0|255] "" IPB_App1
 SG_ StatusBindingFBD_Trunk_Data44 : 376|8@1+ (1.0,0) [0|255] "" IPB_App1
 SG_ StatusBindingFBD_Trunk_Data45 : 384|8@1+ (1.0,0) [0|255] "" IPB_App1
 SG_ StatusBindingFBD_Trunk_Data46 : 392|8@1+ (1.0,0) [0|255] "" IPB_App1
 SG_ StatusBindingFBD_Trunk_Data47 : 400|8@1+ (1.0,0) [0|255] "" IPB_App1
 SG_ StatusBindingFBD_Trunk_Data48 : 408|8@1+ (1.0,0) [0|255] "" IPB_App1
 SG_ StatusBindingFBD_Trunk_Data49 : 416|8@1+ (1.0,0) [0|255] "" IPB_App1
 SG_ StatusBindingFBD_Trunk_Data50 : 424|8@1+ (1.0,0) [0|255] "" IPB_App1
 SG_ StatusBindingFBD_Trunk_Data51 : 432|8@1+ (1.0,0) [0|255] "" IPB_App1
 SG_ StatusBindingFBD_Trunk_Data52 : 440|8@1+ (1.0,0) [0|255] "" IPB_App1
 SG_ StatusBindingFBD_Trunk_Data53 : 448|8@1+ (1.0,0) [0|255] "" IPB_App1
 SG_ StatusBindingFBD_Trunk_Data54 : 456|8@1+ (1.0,0) [0|255] "" IPB_App1
 SG_ StatusBindingFBD_Trunk_Data55 : 464|8@1+ (1.0,0) [0|255] "" IPB_App1
 SG_ StatusBindingFBD_Trunk_Data56 : 472|8@1+ (1.0,0) [0|255] "" IPB_App1
 SG_ StatusBindingFBD_Trunk_Data57 : 480|8@1+ (1.0,0) [0|255] "" IPB_App1
 SG_ StatusBindingFBD_Trunk_Data58 : 488|8@1+ (1.0,0) [0|255] "" IPB_App1
 SG_ StatusBindingFBD_Trunk_Data59 : 496|8@1+ (1.0,0) [0|255] "" IPB_App1
 SG_ StatusBindingFBD_Trunk_Data60 : 504|8@1+ (1.0,0) [0|255] "" IPB_App1

BO_ 624 StatusBindingFBD_VL: 64 FBD_VL
 SG_ StatusBindingFBD_VL_BindingStatu : 0|8@1+ (1.0,0) [0|252] "" IPB_App1
 SG_ StatusBindingFBD_VL_BindingCount : 8|8@1+ (1.0,0) [0|252] "" IPB_App1
 SG_ StatusBindingFBD_VL_BindingSeque : 16|8@1+ (1.0,0) [0|252] "" IPB_App1
 SG_ StatusBindingFBD_VL_Data00 : 24|8@1+ (1.0,0) [0|255] "" IPB_App1
 SG_ StatusBindingFBD_VL_Data01 : 32|8@1+ (1.0,0) [0|255] "" IPB_App1
 SG_ StatusBindingFBD_VL_Data02 : 40|8@1+ (1.0,0) [0|255] "" IPB_App1
 SG_ StatusBindingFBD_VL_Data03 : 48|8@1+ (1.0,0) [0|255] "" IPB_App1
 SG_ StatusBindingFBD_VL_Data04 : 56|8@1+ (1.0,0) [0|255] "" IPB_App1
 SG_ StatusBindingFBD_VL_Data05 : 64|8@1+ (1.0,0) [0|255] "" IPB_App1
 SG_ StatusBindingFBD_VL_Data06 : 72|8@1+ (1.0,0) [0|255] "" IPB_App1
 SG_ StatusBindingFBD_VL_Data07 : 80|8@1+ (1.0,0) [0|255] "" IPB_App1
 SG_ StatusBindingFBD_VL_Data08 : 88|8@1+ (1.0,0) [0|255] "" IPB_App1
 SG_ StatusBindingFBD_VL_Data09 : 96|8@1+ (1.0,0) [0|255] "" IPB_App1
 SG_ StatusBindingFBD_VL_Data10 : 104|8@1+ (1.0,0) [0|255] "" IPB_App1
 SG_ StatusBindingFBD_VL_Data11 : 112|8@1+ (1.0,0) [0|255] "" IPB_App1
 SG_ StatusBindingFBD_VL_Data12 : 120|8@1+ (1.0,0) [0|255] "" IPB_App1
 SG_ StatusBindingFBD_VL_Data13 : 128|8@1+ (1.0,0) [0|255] "" IPB_App1
 SG_ StatusBindingFBD_VL_Data14 : 136|8@1+ (1.0,0) [0|255] "" IPB_App1
 SG_ StatusBindingFBD_VL_Data15 : 144|8@1+ (1.0,0) [0|255] "" IPB_App1
 SG_ StatusBindingFBD_VL_Data16 : 152|8@1+ (1.0,0) [0|255] "" IPB_App1
 SG_ StatusBindingFBD_VL_Data17 : 160|8@1+ (1.0,0) [0|255] "" IPB_App1
 SG_ StatusBindingFBD_VL_Data18 : 168|8@1+ (1.0,0) [0|255] "" IPB_App1
 SG_ StatusBindingFBD_VL_Data19 : 176|8@1+ (1.0,0) [0|255] "" IPB_App1
 SG_ StatusBindingFBD_VL_Data20 : 184|8@1+ (1.0,0) [0|255] "" IPB_App1
 SG_ StatusBindingFBD_VL_Data21 : 192|8@1+ (1.0,0) [0|255] "" IPB_App1
 SG_ StatusBindingFBD_VL_Data22 : 200|8@1+ (1.0,0) [0|255] "" IPB_App1
 SG_ StatusBindingFBD_VL_Data23 : 208|8@1+ (1.0,0) [0|255] "" IPB_App1
 SG_ StatusBindingFBD_VL_Data24 : 216|8@1+ (1.0,0) [0|255] "" IPB_App1
 SG_ StatusBindingFBD_VL_Data25 : 224|8@1+ (1.0,0) [0|255] "" IPB_App1
 SG_ StatusBindingFBD_VL_Data26 : 232|8@1+ (1.0,0) [0|255] "" IPB_App1
 SG_ StatusBindingFBD_VL_Data27 : 240|8@1+ (1.0,0) [0|255] "" IPB_App1
 SG_ StatusBindingFBD_VL_Data28 : 248|8@1+ (1.0,0) [0|255] "" IPB_App1
 SG_ StatusBindingFBD_VL_Data29 : 256|8@1+ (1.0,0) [0|255] "" IPB_App1
 SG_ StatusBindingFBD_VL_Data30 : 264|8@1+ (1.0,0) [0|255] "" IPB_App1
 SG_ StatusBindingFBD_VL_Data31 : 272|8@1+ (1.0,0) [0|255] "" IPB_App1
 SG_ StatusBindingFBD_VL_Data32 : 280|8@1+ (1.0,0) [0|255] "" IPB_App1
 SG_ StatusBindingFBD_VL_Data33 : 288|8@1+ (1.0,0) [0|255] "" IPB_App1
 SG_ StatusBindingFBD_VL_Data34 : 296|8@1+ (1.0,0) [0|255] "" IPB_App1
 SG_ StatusBindingFBD_VL_Data35 : 304|8@1+ (1.0,0) [0|255] "" IPB_App1
 SG_ StatusBindingFBD_VL_Data36 : 312|8@1+ (1.0,0) [0|255] "" IPB_App1
 SG_ StatusBindingFBD_VL_Data37 : 320|8@1+ (1.0,0) [0|255] "" IPB_App1
 SG_ StatusBindingFBD_VL_Data38 : 328|8@1+ (1.0,0) [0|255] "" IPB_App1
 SG_ StatusBindingFBD_VL_Data39 : 336|8@1+ (1.0,0) [0|255] "" IPB_App1
 SG_ StatusBindingFBD_VL_Data40 : 344|8@1+ (1.0,0) [0|255] "" IPB_App1
 SG_ StatusBindingFBD_VL_Data41 : 352|8@1+ (1.0,0) [0|255] "" IPB_App1
 SG_ StatusBindingFBD_VL_Data42 : 360|8@1+ (1.0,0) [0|255] "" IPB_App1
 SG_ StatusBindingFBD_VL_Data43 : 368|8@1+ (1.0,0) [0|255] "" IPB_App1
 SG_ StatusBindingFBD_VL_Data44 : 376|8@1+ (1.0,0) [0|255] "" IPB_App1
 SG_ StatusBindingFBD_VL_Data45 : 384|8@1+ (1.0,0) [0|255] "" IPB_App1
 SG_ StatusBindingFBD_VL_Data46 : 392|8@1+ (1.0,0) [0|255] "" IPB_App1
 SG_ StatusBindingFBD_VL_Data47 : 400|8@1+ (1.0,0) [0|255] "" IPB_App1
 SG_ StatusBindingFBD_VL_Data48 : 408|8@1+ (1.0,0) [0|255] "" IPB_App1
 SG_ StatusBindingFBD_VL_Data49 : 416|8@1+ (1.0,0) [0|255] "" IPB_App1
 SG_ StatusBindingFBD_VL_Data50 : 424|8@1+ (1.0,0) [0|255] "" IPB_App1
 SG_ StatusBindingFBD_VL_Data51 : 432|8@1+ (1.0,0) [0|255] "" IPB_App1
 SG_ StatusBindingFBD_VL_Data52 : 440|8@1+ (1.0,0) [0|255] "" IPB_App1
 SG_ StatusBindingFBD_VL_Data53 : 448|8@1+ (1.0,0) [0|255] "" IPB_App1
 SG_ StatusBindingFBD_VL_Data54 : 456|8@1+ (1.0,0) [0|255] "" IPB_App1
 SG_ StatusBindingFBD_VL_Data55 : 464|8@1+ (1.0,0) [0|255] "" IPB_App1
 SG_ StatusBindingFBD_VL_Data56 : 472|8@1+ (1.0,0) [0|255] "" IPB_App1
 SG_ StatusBindingFBD_VL_Data57 : 480|8@1+ (1.0,0) [0|255] "" IPB_App1
 SG_ StatusBindingFBD_VL_Data58 : 488|8@1+ (1.0,0) [0|255] "" IPB_App1
 SG_ StatusBindingFBD_VL_Data59 : 496|8@1+ (1.0,0) [0|255] "" IPB_App1
 SG_ StatusBindingFBD_VL_Data60 : 504|8@1+ (1.0,0) [0|255] "" IPB_App1

BO_ 620 StatusBindingFBD_VM: 64 FBD_VM
 SG_ StatusBindingFBD_VM_BindingStatu : 0|8@1+ (1.0,0) [0|252] "" IPB_App1
 SG_ StatusBindingFBD_VM_BindingCount : 8|8@1+ (1.0,0) [0|252] "" IPB_App1
 SG_ StatusBindingFBD_VM_BindingSeque : 16|8@1+ (1.0,0) [0|252] "" IPB_App1
 SG_ StatusBindingFBD_VM_Data00 : 24|8@1+ (1.0,0) [0|255] "" IPB_App1
 SG_ StatusBindingFBD_VM_Data01 : 32|8@1+ (1.0,0) [0|255] "" IPB_App1
 SG_ StatusBindingFBD_VM_Data02 : 40|8@1+ (1.0,0) [0|255] "" IPB_App1
 SG_ StatusBindingFBD_VM_Data03 : 48|8@1+ (1.0,0) [0|255] "" IPB_App1
 SG_ StatusBindingFBD_VM_Data04 : 56|8@1+ (1.0,0) [0|255] "" IPB_App1
 SG_ StatusBindingFBD_VM_Data05 : 64|8@1+ (1.0,0) [0|255] "" IPB_App1
 SG_ StatusBindingFBD_VM_Data06 : 72|8@1+ (1.0,0) [0|255] "" IPB_App1
 SG_ StatusBindingFBD_VM_Data07 : 80|8@1+ (1.0,0) [0|255] "" IPB_App1
 SG_ StatusBindingFBD_VM_Data08 : 88|8@1+ (1.0,0) [0|255] "" IPB_App1
 SG_ StatusBindingFBD_VM_Data09 : 96|8@1+ (1.0,0) [0|255] "" IPB_App1
 SG_ StatusBindingFBD_VM_Data10 : 104|8@1+ (1.0,0) [0|255] "" IPB_App1
 SG_ StatusBindingFBD_VM_Data11 : 112|8@1+ (1.0,0) [0|255] "" IPB_App1
 SG_ StatusBindingFBD_VM_Data12 : 120|8@1+ (1.0,0) [0|255] "" IPB_App1
 SG_ StatusBindingFBD_VM_Data13 : 128|8@1+ (1.0,0) [0|255] "" IPB_App1
 SG_ StatusBindingFBD_VM_Data14 : 136|8@1+ (1.0,0) [0|255] "" IPB_App1
 SG_ StatusBindingFBD_VM_Data15 : 144|8@1+ (1.0,0) [0|255] "" IPB_App1
 SG_ StatusBindingFBD_VM_Data16 : 152|8@1+ (1.0,0) [0|255] "" IPB_App1
 SG_ StatusBindingFBD_VM_Data17 : 160|8@1+ (1.0,0) [0|255] "" IPB_App1
 SG_ StatusBindingFBD_VM_Data18 : 168|8@1+ (1.0,0) [0|255] "" IPB_App1
 SG_ StatusBindingFBD_VM_Data19 : 176|8@1+ (1.0,0) [0|255] "" IPB_App1
 SG_ StatusBindingFBD_VM_Data20 : 184|8@1+ (1.0,0) [0|255] "" IPB_App1
 SG_ StatusBindingFBD_VM_Data21 : 192|8@1+ (1.0,0) [0|255] "" IPB_App1
 SG_ StatusBindingFBD_VM_Data22 : 200|8@1+ (1.0,0) [0|255] "" IPB_App1
 SG_ StatusBindingFBD_VM_Data23 : 208|8@1+ (1.0,0) [0|255] "" IPB_App1
 SG_ StatusBindingFBD_VM_Data24 : 216|8@1+ (1.0,0) [0|255] "" IPB_App1
 SG_ StatusBindingFBD_VM_Data25 : 224|8@1+ (1.0,0) [0|255] "" IPB_App1
 SG_ StatusBindingFBD_VM_Data26 : 232|8@1+ (1.0,0) [0|255] "" IPB_App1
 SG_ StatusBindingFBD_VM_Data27 : 240|8@1+ (1.0,0) [0|255] "" IPB_App1
 SG_ StatusBindingFBD_VM_Data28 : 248|8@1+ (1.0,0) [0|255] "" IPB_App1
 SG_ StatusBindingFBD_VM_Data29 : 256|8@1+ (1.0,0) [0|255] "" IPB_App1
 SG_ StatusBindingFBD_VM_Data30 : 264|8@1+ (1.0,0) [0|255] "" IPB_App1
 SG_ StatusBindingFBD_VM_Data31 : 272|8@1+ (1.0,0) [0|255] "" IPB_App1
 SG_ StatusBindingFBD_VM_Data32 : 280|8@1+ (1.0,0) [0|255] "" IPB_App1
 SG_ StatusBindingFBD_VM_Data33 : 288|8@1+ (1.0,0) [0|255] "" IPB_App1
 SG_ StatusBindingFBD_VM_Data34 : 296|8@1+ (1.0,0) [0|255] "" IPB_App1
 SG_ StatusBindingFBD_VM_Data35 : 304|8@1+ (1.0,0) [0|255] "" IPB_App1
 SG_ StatusBindingFBD_VM_Data36 : 312|8@1+ (1.0,0) [0|255] "" IPB_App1
 SG_ StatusBindingFBD_VM_Data37 : 320|8@1+ (1.0,0) [0|255] "" IPB_App1
 SG_ StatusBindingFBD_VM_Data38 : 328|8@1+ (1.0,0) [0|255] "" IPB_App1
 SG_ StatusBindingFBD_VM_Data39 : 336|8@1+ (1.0,0) [0|255] "" IPB_App1
 SG_ StatusBindingFBD_VM_Data40 : 344|8@1+ (1.0,0) [0|255] "" IPB_App1
 SG_ StatusBindingFBD_VM_Data41 : 352|8@1+ (1.0,0) [0|255] "" IPB_App1
 SG_ StatusBindingFBD_VM_Data42 : 360|8@1+ (1.0,0) [0|255] "" IPB_App1
 SG_ StatusBindingFBD_VM_Data43 : 368|8@1+ (1.0,0) [0|255] "" IPB_App1
 SG_ StatusBindingFBD_VM_Data44 : 376|8@1+ (1.0,0) [0|255] "" IPB_App1
 SG_ StatusBindingFBD_VM_Data45 : 384|8@1+ (1.0,0) [0|255] "" IPB_App1
 SG_ StatusBindingFBD_VM_Data46 : 392|8@1+ (1.0,0) [0|255] "" IPB_App1
 SG_ StatusBindingFBD_VM_Data47 : 400|8@1+ (1.0,0) [0|255] "" IPB_App1
 SG_ StatusBindingFBD_VM_Data48 : 408|8@1+ (1.0,0) [0|255] "" IPB_App1
 SG_ StatusBindingFBD_VM_Data49 : 416|8@1+ (1.0,0) [0|255] "" IPB_App1
 SG_ StatusBindingFBD_VM_Data50 : 424|8@1+ (1.0,0) [0|255] "" IPB_App1
 SG_ StatusBindingFBD_VM_Data51 : 432|8@1+ (1.0,0) [0|255] "" IPB_App1
 SG_ StatusBindingFBD_VM_Data52 : 440|8@1+ (1.0,0) [0|255] "" IPB_App1
 SG_ StatusBindingFBD_VM_Data53 : 448|8@1+ (1.0,0) [0|255] "" IPB_App1
 SG_ StatusBindingFBD_VM_Data54 : 456|8@1+ (1.0,0) [0|255] "" IPB_App1
 SG_ StatusBindingFBD_VM_Data55 : 464|8@1+ (1.0,0) [0|255] "" IPB_App1
 SG_ StatusBindingFBD_VM_Data56 : 472|8@1+ (1.0,0) [0|255] "" IPB_App1
 SG_ StatusBindingFBD_VM_Data57 : 480|8@1+ (1.0,0) [0|255] "" IPB_App1
 SG_ StatusBindingFBD_VM_Data58 : 488|8@1+ (1.0,0) [0|255] "" IPB_App1
 SG_ StatusBindingFBD_VM_Data59 : 496|8@1+ (1.0,0) [0|255] "" IPB_App1
 SG_ StatusBindingFBD_VM_Data60 : 504|8@1+ (1.0,0) [0|255] "" IPB_App1

BO_ 625 StatusBindingFBD_VR: 64 FBD_VR
 SG_ StatusBindingFBD_VR_BindingStatu : 0|8@1+ (1.0,0) [0|252] "" IPB_App1
 SG_ StatusBindingFBD_VR_BindingCount : 8|8@1+ (1.0,0) [0|252] "" IPB_App1
 SG_ StatusBindingFBD_VR_BindingSeque : 16|8@1+ (1.0,0) [0|252] "" IPB_App1
 SG_ StatusBindingFBD_VR_Data00 : 24|8@1+ (1.0,0) [0|255] "" IPB_App1
 SG_ StatusBindingFBD_VR_Data01 : 32|8@1+ (1.0,0) [0|255] "" IPB_App1
 SG_ StatusBindingFBD_VR_Data02 : 40|8@1+ (1.0,0) [0|255] "" IPB_App1
 SG_ StatusBindingFBD_VR_Data03 : 48|8@1+ (1.0,0) [0|255] "" IPB_App1
 SG_ StatusBindingFBD_VR_Data04 : 56|8@1+ (1.0,0) [0|255] "" IPB_App1
 SG_ StatusBindingFBD_VR_Data05 : 64|8@1+ (1.0,0) [0|255] "" IPB_App1
 SG_ StatusBindingFBD_VR_Data06 : 72|8@1+ (1.0,0) [0|255] "" IPB_App1
 SG_ StatusBindingFBD_VR_Data07 : 80|8@1+ (1.0,0) [0|255] "" IPB_App1
 SG_ StatusBindingFBD_VR_Data08 : 88|8@1+ (1.0,0) [0|255] "" IPB_App1
 SG_ StatusBindingFBD_VR_Data09 : 96|8@1+ (1.0,0) [0|255] "" IPB_App1
 SG_ StatusBindingFBD_VR_Data10 : 104|8@1+ (1.0,0) [0|255] "" IPB_App1
 SG_ StatusBindingFBD_VR_Data11 : 112|8@1+ (1.0,0) [0|255] "" IPB_App1
 SG_ StatusBindingFBD_VR_Data12 : 120|8@1+ (1.0,0) [0|255] "" IPB_App1
 SG_ StatusBindingFBD_VR_Data13 : 128|8@1+ (1.0,0) [0|255] "" IPB_App1
 SG_ StatusBindingFBD_VR_Data14 : 136|8@1+ (1.0,0) [0|255] "" IPB_App1
 SG_ StatusBindingFBD_VR_Data15 : 144|8@1+ (1.0,0) [0|255] "" IPB_App1
 SG_ StatusBindingFBD_VR_Data16 : 152|8@1+ (1.0,0) [0|255] "" IPB_App1
 SG_ StatusBindingFBD_VR_Data17 : 160|8@1+ (1.0,0) [0|255] "" IPB_App1
 SG_ StatusBindingFBD_VR_Data18 : 168|8@1+ (1.0,0) [0|255] "" IPB_App1
 SG_ StatusBindingFBD_VR_Data19 : 176|8@1+ (1.0,0) [0|255] "" IPB_App1
 SG_ StatusBindingFBD_VR_Data20 : 184|8@1+ (1.0,0) [0|255] "" IPB_App1
 SG_ StatusBindingFBD_VR_Data21 : 192|8@1+ (1.0,0) [0|255] "" IPB_App1
 SG_ StatusBindingFBD_VR_Data22 : 200|8@1+ (1.0,0) [0|255] "" IPB_App1
 SG_ StatusBindingFBD_VR_Data23 : 208|8@1+ (1.0,0) [0|255] "" IPB_App1
 SG_ StatusBindingFBD_VR_Data24 : 216|8@1+ (1.0,0) [0|255] "" IPB_App1
 SG_ StatusBindingFBD_VR_Data25 : 224|8@1+ (1.0,0) [0|255] "" IPB_App1
 SG_ StatusBindingFBD_VR_Data26 : 232|8@1+ (1.0,0) [0|255] "" IPB_App1
 SG_ StatusBindingFBD_VR_Data27 : 240|8@1+ (1.0,0) [0|255] "" IPB_App1
 SG_ StatusBindingFBD_VR_Data28 : 248|8@1+ (1.0,0) [0|255] "" IPB_App1
 SG_ StatusBindingFBD_VR_Data29 : 256|8@1+ (1.0,0) [0|255] "" IPB_App1
 SG_ StatusBindingFBD_VR_Data30 : 264|8@1+ (1.0,0) [0|255] "" IPB_App1
 SG_ StatusBindingFBD_VR_Data31 : 272|8@1+ (1.0,0) [0|255] "" IPB_App1
 SG_ StatusBindingFBD_VR_Data32 : 280|8@1+ (1.0,0) [0|255] "" IPB_App1
 SG_ StatusBindingFBD_VR_Data33 : 288|8@1+ (1.0,0) [0|255] "" IPB_App1
 SG_ StatusBindingFBD_VR_Data34 : 296|8@1+ (1.0,0) [0|255] "" IPB_App1
 SG_ StatusBindingFBD_VR_Data35 : 304|8@1+ (1.0,0) [0|255] "" IPB_App1
 SG_ StatusBindingFBD_VR_Data36 : 312|8@1+ (1.0,0) [0|255] "" IPB_App1
 SG_ StatusBindingFBD_VR_Data37 : 320|8@1+ (1.0,0) [0|255] "" IPB_App1
 SG_ StatusBindingFBD_VR_Data38 : 328|8@1+ (1.0,0) [0|255] "" IPB_App1
 SG_ StatusBindingFBD_VR_Data39 : 336|8@1+ (1.0,0) [0|255] "" IPB_App1
 SG_ StatusBindingFBD_VR_Data40 : 344|8@1+ (1.0,0) [0|255] "" IPB_App1
 SG_ StatusBindingFBD_VR_Data41 : 352|8@1+ (1.0,0) [0|255] "" IPB_App1
 SG_ StatusBindingFBD_VR_Data42 : 360|8@1+ (1.0,0) [0|255] "" IPB_App1
 SG_ StatusBindingFBD_VR_Data43 : 368|8@1+ (1.0,0) [0|255] "" IPB_App1
 SG_ StatusBindingFBD_VR_Data44 : 376|8@1+ (1.0,0) [0|255] "" IPB_App1
 SG_ StatusBindingFBD_VR_Data45 : 384|8@1+ (1.0,0) [0|255] "" IPB_App1
 SG_ StatusBindingFBD_VR_Data46 : 392|8@1+ (1.0,0) [0|255] "" IPB_App1
 SG_ StatusBindingFBD_VR_Data47 : 400|8@1+ (1.0,0) [0|255] "" IPB_App1
 SG_ StatusBindingFBD_VR_Data48 : 408|8@1+ (1.0,0) [0|255] "" IPB_App1
 SG_ StatusBindingFBD_VR_Data49 : 416|8@1+ (1.0,0) [0|255] "" IPB_App1
 SG_ StatusBindingFBD_VR_Data50 : 424|8@1+ (1.0,0) [0|255] "" IPB_App1
 SG_ StatusBindingFBD_VR_Data51 : 432|8@1+ (1.0,0) [0|255] "" IPB_App1
 SG_ StatusBindingFBD_VR_Data52 : 440|8@1+ (1.0,0) [0|255] "" IPB_App1
 SG_ StatusBindingFBD_VR_Data53 : 448|8@1+ (1.0,0) [0|255] "" IPB_App1
 SG_ StatusBindingFBD_VR_Data54 : 456|8@1+ (1.0,0) [0|255] "" IPB_App1
 SG_ StatusBindingFBD_VR_Data55 : 464|8@1+ (1.0,0) [0|255] "" IPB_App1
 SG_ StatusBindingFBD_VR_Data56 : 472|8@1+ (1.0,0) [0|255] "" IPB_App1
 SG_ StatusBindingFBD_VR_Data57 : 480|8@1+ (1.0,0) [0|255] "" IPB_App1
 SG_ StatusBindingFBD_VR_Data58 : 488|8@1+ (1.0,0) [0|255] "" IPB_App1
 SG_ StatusBindingFBD_VR_Data59 : 496|8@1+ (1.0,0) [0|255] "" IPB_App1
 SG_ StatusBindingFBD_VR_Data60 : 504|8@1+ (1.0,0) [0|255] "" IPB_App1

BO_ 286 StatusBLEConMonitoringFBD_HL: 8 FBD_HL
 SG_ StatusBLEConMonitoringFBD_HL_IRK : 0|8@1+ (1.0,0) [0|252] "" FBD_HM,FBD_HR,FBD_MM,FBD_Miko,FBD_Trunk,FBD_VL,FBD_VM,FBD_VR,IPB_App1
 SG_ StatusBLEConMonitoringFBD_HL_Mon : 8|8@1+ (1,0) [0|0] "" FBD_HM,FBD_HR,FBD_MM,FBD_Miko,FBD_Trunk,FBD_VL,FBD_VM,FBD_VR,IPB_App1
 SG_ StatusBLEConMonitoringFBD_HL_Bus : 16|8@1+ (10.0,0) [0|252] "ms" FBD_HM,FBD_HR,FBD_MM,FBD_Miko,FBD_Trunk,FBD_VL,FBD_VM,FBD_VR,IPB_App1
 SG_ StatusBLEConMonitoringFBD_HL_BLE : 24|16@1+ (1,0) [0|0] "" FBD_HM,FBD_HR,FBD_MM,FBD_Miko,FBD_Trunk,FBD_VL,FBD_VM,FBD_VR,IPB_App1

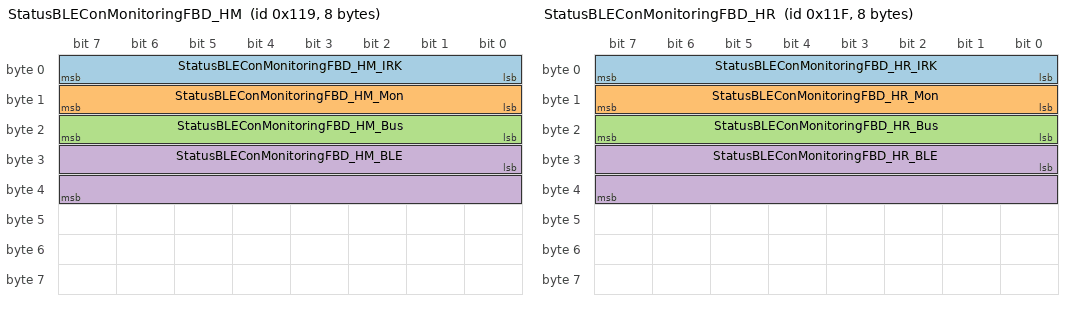
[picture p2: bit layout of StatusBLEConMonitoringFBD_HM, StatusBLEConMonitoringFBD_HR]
BO_ 281 StatusBLEConMonitoringFBD_HM: 8 FBD_HM
 SG_ StatusBLEConMonitoringFBD_HM_IRK : 0|8@1+ (1.0,0) [0|252] "" FBD_HL,FBD_HR,FBD_MM,FBD_Miko,FBD_Trunk,FBD_VL,FBD_VM,FBD_VR,IPB_App1
 SG_ StatusBLEConMonitoringFBD_HM_Mon : 8|8@1+ (1,0) [0|0] "" FBD_HL,FBD_HR,FBD_MM,FBD_Miko,FBD_Trunk,FBD_VL,FBD_VM,FBD_VR,IPB_App1
 SG_ StatusBLEConMonitoringFBD_HM_Bus : 16|8@1+ (10.0,0) [0|252] "ms" FBD_HL,FBD_HR,FBD_MM,FBD_Miko,FBD_Trunk,FBD_VL,FBD_VM,FBD_VR,IPB_App1
 SG_ StatusBLEConMonitoringFBD_HM_BLE : 24|16@1+ (1,0) [0|0] "" FBD_HL,FBD_HR,FBD_MM,FBD_Miko,FBD_Trunk,FBD_VL,FBD_VM,FBD_VR,IPB_App1

BO_ 287 StatusBLEConMonitoringFBD_HR: 8 FBD_HR
 SG_ StatusBLEConMonitoringFBD_HR_IRK : 0|8@1+ (1.0,0) [0|252] "" FBD_HL,FBD_HM,FBD_MM,FBD_Miko,FBD_Trunk,FBD_VL,FBD_VM,FBD_VR,IPB_App1
 SG_ StatusBLEConMonitoringFBD_HR_Mon : 8|8@1+ (1,0) [0|0] "" FBD_HL,FBD_HM,FBD_MM,FBD_Miko,FBD_Trunk,FBD_VL,FBD_VM,FBD_VR,IPB_App1
 SG_ StatusBLEConMonitoringFBD_HR_Bus : 16|8@1+ (10.0,0) [0|252] "ms" FBD_HL,FBD_HM,FBD_MM,FBD_Miko,FBD_Trunk,FBD_VL,FBD_VM,FBD_VR,IPB_App1
 SG_ StatusBLEConMonitoringFBD_HR_BLE : 24|16@1+ (1,0) [0|0] "" FBD_HL,FBD_HM,FBD_MM,FBD_Miko,FBD_Trunk,FBD_VL,FBD_VM,FBD_VR,IPB_App1

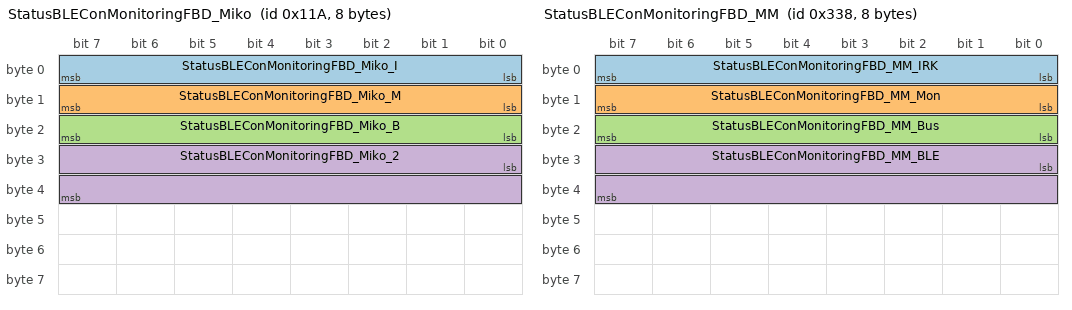
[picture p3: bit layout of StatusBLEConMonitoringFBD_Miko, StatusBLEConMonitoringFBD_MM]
BO_ 282 StatusBLEConMonitoringFBD_Miko: 8 FBD_Miko
 SG_ StatusBLEConMonitoringFBD_Miko_I : 0|8@1+ (1.0,0) [0|252] "" FBD_HL,FBD_HM,FBD_HR,FBD_MM,FBD_Trunk,FBD_VL,FBD_VM,FBD_VR,IPB_App1
 SG_ StatusBLEConMonitoringFBD_Miko_M : 8|8@1+ (1,0) [0|0] "" FBD_HL,FBD_HM,FBD_HR,FBD_MM,FBD_Trunk,FBD_VL,FBD_VM,FBD_VR,IPB_App1
 SG_ StatusBLEConMonitoringFBD_Miko_B : 16|8@1+ (10.0,0) [0|252] "ms" FBD_HL,FBD_HM,FBD_HR,FBD_MM,FBD_Trunk,FBD_VL,FBD_VM,FBD_VR,IPB_App1
 SG_ StatusBLEConMonitoringFBD_Miko_2 : 24|16@1+ (1,0) [0|0] "" FBD_HL,FBD_HM,FBD_HR,FBD_MM,FBD_Trunk,FBD_VL,FBD_VM,FBD_VR,IPB_App1

BO_ 824 StatusBLEConMonitoringFBD_MM: 8 FBD_MM
 SG_ StatusBLEConMonitoringFBD_MM_IRK : 0|8@1+ (1.0,0) [0|252] "" FBD_HL,FBD_HM,FBD_HR,FBD_Miko,FBD_Trunk,FBD_VL,FBD_VM,FBD_VR,IPB_App1
 SG_ StatusBLEConMonitoringFBD_MM_Mon : 8|8@1+ (1,0) [0|0] "" FBD_HL,FBD_HM,FBD_HR,FBD_Miko,FBD_Trunk,FBD_VL,FBD_VM,FBD_VR,IPB_App1
 SG_ StatusBLEConMonitoringFBD_MM_Bus : 16|8@1+ (10.0,0) [0|252] "ms" FBD_HL,FBD_HM,FBD_HR,FBD_Miko,FBD_Trunk,FBD_VL,FBD_VM,FBD_VR,IPB_App1
 SG_ StatusBLEConMonitoringFBD_MM_BLE : 24|16@1+ (1,0) [0|0] "" FBD_HL,FBD_HM,FBD_HR,FBD_Miko,FBD_Trunk,FBD_VL,FBD_VM,FBD_VR,IPB_App1

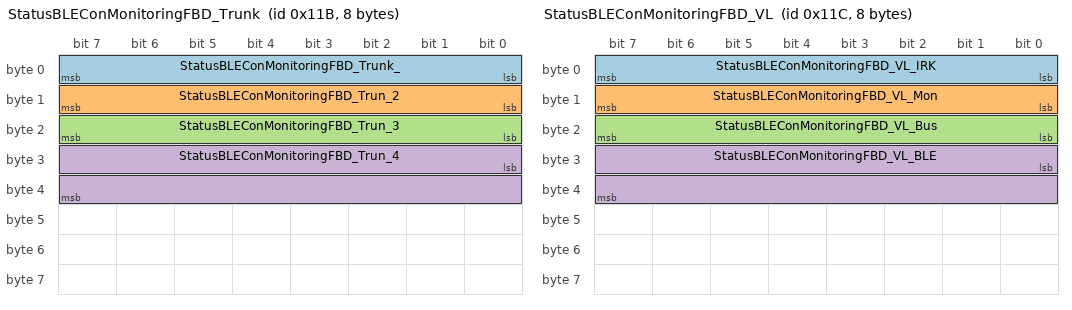
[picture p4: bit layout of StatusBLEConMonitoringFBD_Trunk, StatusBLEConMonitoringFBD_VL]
BO_ 283 StatusBLEConMonitoringFBD_Trunk: 8 FBD_Trunk
 SG_ StatusBLEConMonitoringFBD_Trunk_ : 0|8@1+ (1.0,0) [0|252] "" FBD_HL,FBD_HM,FBD_HR,FBD_MM,FBD_Miko,FBD_VL,FBD_VM,FBD_VR,IPB_App1
 SG_ StatusBLEConMonitoringFBD_Trun_2 : 8|8@1+ (1,0) [0|0] "" FBD_HL,FBD_HM,FBD_HR,FBD_MM,FBD_Miko,FBD_VL,FBD_VM,FBD_VR,IPB_App1
 SG_ StatusBLEConMonitoringFBD_Trun_3 : 16|8@1+ (10.0,0) [0|252] "ms" FBD_HL,FBD_HM,FBD_HR,FBD_MM,FBD_Miko,FBD_VL,FBD_VM,FBD_VR,IPB_App1
 SG_ StatusBLEConMonitoringFBD_Trun_4 : 24|16@1+ (1,0) [0|0] "" FBD_HL,FBD_HM,FBD_HR,FBD_MM,FBD_Miko,FBD_VL,FBD_VM,FBD_VR,IPB_App1

BO_ 284 StatusBLEConMonitoringFBD_VL: 8 FBD_VL
 SG_ StatusBLEConMonitoringFBD_VL_IRK : 0|8@1+ (1.0,0) [0|252] "" FBD_HL,FBD_HM,FBD_HR,FBD_MM,FBD_Miko,FBD_Trunk,FBD_VM,FBD_VR,IPB_App1
 SG_ StatusBLEConMonitoringFBD_VL_Mon : 8|8@1+ (1,0) [0|0] "" FBD_HL,FBD_HM,FBD_HR,FBD_MM,FBD_Miko,FBD_Trunk,FBD_VM,FBD_VR,IPB_App1
 SG_ StatusBLEConMonitoringFBD_VL_Bus : 16|8@1+ (10.0,0) [0|252] "ms" FBD_HL,FBD_HM,FBD_HR,FBD_MM,FBD_Miko,FBD_Trunk,FBD_VM,FBD_VR,IPB_App1
 SG_ StatusBLEConMonitoringFBD_VL_BLE : 24|16@1+ (1,0) [0|0] "" FBD_HL,FBD_HM,FBD_HR,FBD_MM,FBD_Miko,FBD_Trunk,FBD_VM,FBD_VR,IPB_App1

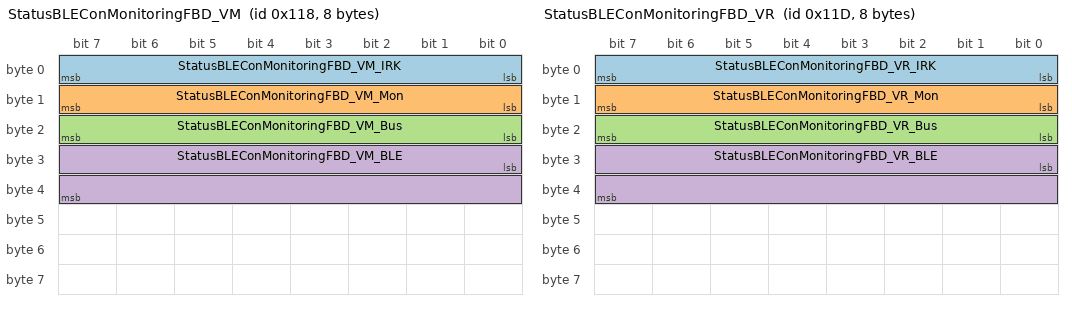
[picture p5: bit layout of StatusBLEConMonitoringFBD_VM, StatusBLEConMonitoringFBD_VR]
BO_ 280 StatusBLEConMonitoringFBD_VM: 8 FBD_VM
 SG_ StatusBLEConMonitoringFBD_VM_IRK : 0|8@1+ (1.0,0) [0|252] "" FBD_HL,FBD_HM,FBD_HR,FBD_MM,FBD_Miko,FBD_Trunk,FBD_VL,FBD_VR,IPB_App1
 SG_ StatusBLEConMonitoringFBD_VM_Mon : 8|8@1+ (1,0) [0|0] "" FBD_HL,FBD_HM,FBD_HR,FBD_MM,FBD_Miko,FBD_Trunk,FBD_VL,FBD_VR,IPB_App1
 SG_ StatusBLEConMonitoringFBD_VM_Bus : 16|8@1+ (10.0,0) [0|252] "ms" FBD_HL,FBD_HM,FBD_HR,FBD_MM,FBD_Miko,FBD_Trunk,FBD_VL,FBD_VR,IPB_App1
 SG_ StatusBLEConMonitoringFBD_VM_BLE : 24|16@1+ (1,0) [0|0] "" FBD_HL,FBD_HM,FBD_HR,FBD_MM,FBD_Miko,FBD_Trunk,FBD_VL,FBD_VR,IPB_App1

BO_ 285 StatusBLEConMonitoringFBD_VR: 8 FBD_VR
 SG_ StatusBLEConMonitoringFBD_VR_IRK : 0|8@1+ (1.0,0) [0|252] "" FBD_HL,FBD_HM,FBD_HR,FBD_MM,FBD_Miko,FBD_Trunk,FBD_VL,FBD_VM,IPB_App1
 SG_ StatusBLEConMonitoringFBD_VR_Mon : 8|8@1+ (1,0) [0|0] "" FBD_HL,FBD_HM,FBD_HR,FBD_MM,FBD_Miko,FBD_Trunk,FBD_VL,FBD_VM,IPB_App1
 SG_ StatusBLEConMonitoringFBD_VR_Bus : 16|8@1+ (10.0,0) [0|252] "ms" FBD_HL,FBD_HM,FBD_HR,FBD_MM,FBD_Miko,FBD_Trunk,FBD_VL,FBD_VM,IPB_App1
 SG_ StatusBLEConMonitoringFBD_VR_BLE : 24|16@1+ (1,0) [0|0] "" FBD_HL,FBD_HM,FBD_HR,FBD_MM,FBD_Miko,FBD_Trunk,FBD_VL,FBD_VM,IPB_App1

BO_ 376 StatusBLECSFBD_HL: 16 FBD_HL
 SG_ StatusBLECSFBD_HL_SessionID : 0|8@1+ (1.0,0) [0|252] "" IPB_App1
 SG_ StatusBLECSFBD_HL_IRKListID : 8|8@1+ (1.0,0) [0|252] "" IPB_App1
 SG_ StatusBLECSFBD_HL_DeviceGroup : 16|8@1+ (1.0,0) [0|252] "" IPB_App1
 SG_ StatusBLECSFBD_HL_Algorithm : 24|8@1+ (1,0) [0|0] "" IPB_App1
 SG_ StatusBLECSFBD_HL_DistanceOffset : 32|16@1+ (1.0,0) [0|65532] "" IPB_App1
 SG_ StatusBLECSFBD_HL_AntennaConfig : 48|8@1+ (1,0) [0|0] "" IPB_App1
 SG_ StatusBLECSFBD_HL_TxPower : 56|8@1+ (1.0,0) [0|252] "" IPB_App1
 SG_ StatusBLECSFBD_HL_Role : 64|8@1+ (1,0) [0|0] "" IPB_App1
 SG_ StatusBLECSFBD_HL_ProcedureResul : 72|8@1+ (1,0) [0|0] "" IPB_App1
 SG_ StatusBLECSFBD_HL_AntennaPathPro : 80|8@1+ (1,0) [0|0] "" IPB_App1
 SG_ StatusBLECSFBD_HL_FBDonlyThresho : 88|8@1+ (1.0,0) [0|252] "" IPB_App1
 SG_ StatusBLECSFBD_HL_InlinePCT : 96|8@1+ (1,0) [0|0] "" IPB_App1

BO_ 371 StatusBLECSFBD_HM: 16 FBD_HM
 SG_ StatusBLECSFBD_HM_SessionID : 0|8@1+ (1.0,0) [0|252] "" IPB_App1
 SG_ StatusBLECSFBD_HM_IRKListID : 8|8@1+ (1.0,0) [0|252] "" IPB_App1
 SG_ StatusBLECSFBD_HM_DeviceGroup : 16|8@1+ (1.0,0) [0|252] "" IPB_App1
 SG_ StatusBLECSFBD_HM_Algorithm : 24|8@1+ (1,0) [0|0] "" IPB_App1
 SG_ StatusBLECSFBD_HM_DistanceOffset : 32|16@1+ (1.0,0) [0|65532] "" IPB_App1
 SG_ StatusBLECSFBD_HM_AntennaConfig : 48|8@1+ (1,0) [0|0] "" IPB_App1
 SG_ StatusBLECSFBD_HM_TxPower : 56|8@1+ (1.0,0) [0|252] "" IPB_App1
 SG_ StatusBLECSFBD_HM_Role : 64|8@1+ (1,0) [0|0] "" IPB_App1
 SG_ StatusBLECSFBD_HM_ProcedureResul : 72|8@1+ (1,0) [0|0] "" IPB_App1
 SG_ StatusBLECSFBD_HM_AntennaPathPro : 80|8@1+ (1,0) [0|0] "" IPB_App1
 SG_ StatusBLECSFBD_HM_FBDonlyThresho : 88|8@1+ (1.0,0) [0|252] "" IPB_App1
 SG_ StatusBLECSFBD_HM_InlinePCT : 96|8@1+ (1,0) [0|0] "" IPB_App1

BO_ 377 StatusBLECSFBD_HR: 16 FBD_HR
 SG_ StatusBLECSFBD_HR_SessionID : 0|8@1+ (1.0,0) [0|252] "" IPB_App1
 SG_ StatusBLECSFBD_HR_IRKListID : 8|8@1+ (1.0,0) [0|252] "" IPB_App1
 SG_ StatusBLECSFBD_HR_DeviceGroup : 16|8@1+ (1.0,0) [0|252] "" IPB_App1
 SG_ StatusBLECSFBD_HR_Algorithm : 24|8@1+ (1,0) [0|0] "" IPB_App1
 SG_ StatusBLECSFBD_HR_DistanceOffset : 32|16@1+ (1.0,0) [0|65532] "" IPB_App1
 SG_ StatusBLECSFBD_HR_AntennaConfig : 48|8@1+ (1,0) [0|0] "" IPB_App1
 SG_ StatusBLECSFBD_HR_TxPower : 56|8@1+ (1.0,0) [0|252] "" IPB_App1
 SG_ StatusBLECSFBD_HR_Role : 64|8@1+ (1,0) [0|0] "" IPB_App1
 SG_ StatusBLECSFBD_HR_ProcedureResul : 72|8@1+ (1,0) [0|0] "" IPB_App1
 SG_ StatusBLECSFBD_HR_AntennaPathPro : 80|8@1+ (1,0) [0|0] "" IPB_App1
 SG_ StatusBLECSFBD_HR_FBDonlyThresho : 88|8@1+ (1.0,0) [0|252] "" IPB_App1
 SG_ StatusBLECSFBD_HR_InlinePCT : 96|8@1+ (1,0) [0|0] "" IPB_App1

BO_ 372 StatusBLECSFBD_Miko: 16 FBD_Miko
 SG_ StatusBLECSFBD_Miko_SessionID : 0|8@1+ (1.0,0) [0|252] "" IPB_App1
 SG_ StatusBLECSFBD_Miko_IRKListID : 8|8@1+ (1.0,0) [0|252] "" IPB_App1
 SG_ StatusBLECSFBD_Miko_DeviceGroup : 16|8@1+ (1.0,0) [0|252] "" IPB_App1
 SG_ StatusBLECSFBD_Miko_Algorithm : 24|8@1+ (1,0) [0|0] "" IPB_App1
 SG_ StatusBLECSFBD_Miko_DistanceOffs : 32|16@1+ (1.0,0) [0|65532] "" IPB_App1
 SG_ StatusBLECSFBD_Miko_AntennaConfi : 48|8@1+ (1,0) [0|0] "" IPB_App1
 SG_ StatusBLECSFBD_Miko_TxPower : 56|8@1+ (1.0,0) [0|252] "" IPB_App1
 SG_ StatusBLECSFBD_Miko_Role : 64|8@1+ (1,0) [0|0] "" IPB_App1
 SG_ StatusBLECSFBD_Miko_ProcedureRes : 72|8@1+ (1,0) [0|0] "" IPB_App1
 SG_ StatusBLECSFBD_Miko_AntennaPathP : 80|8@1+ (1,0) [0|0] "" IPB_App1
 SG_ StatusBLECSFBD_Miko_FBDonlyThres : 88|8@1+ (1.0,0) [0|252] "" IPB_App1
 SG_ StatusBLECSFBD_Miko_InlinePCT : 96|8@1+ (1,0) [0|0] "" IPB_App1

BO_ 380 StatusBLECSFBD_MM: 16 FBD_MM
 SG_ StatusBLECSFBD_MM_SessionID : 0|8@1+ (1.0,0) [0|252] "" IPB_App1
 SG_ StatusBLECSFBD_MM_IRKListID : 8|8@1+ (1.0,0) [0|252] "" IPB_App1
 SG_ StatusBLECSFBD_MM_DeviceGroup : 16|8@1+ (1.0,0) [0|252] "" IPB_App1
 SG_ StatusBLECSFBD_MM_Algorithm : 24|8@1+ (1,0) [0|0] "" IPB_App1
 SG_ StatusBLECSFBD_MM_DistanceOffset : 32|16@1+ (1.0,0) [0|65532] "" IPB_App1
 SG_ StatusBLECSFBD_MM_AntennaConfig : 48|8@1+ (1,0) [0|0] "" IPB_App1
 SG_ StatusBLECSFBD_MM_TxPower : 56|8@1+ (1.0,0) [0|252] "" IPB_App1
 SG_ StatusBLECSFBD_MM_Role : 64|8@1+ (1,0) [0|0] "" IPB_App1
 SG_ StatusBLECSFBD_MM_ProcedureResul : 72|8@1+ (1,0) [0|0] "" IPB_App1
 SG_ StatusBLECSFBD_MM_AntennaPathPro : 80|8@1+ (1,0) [0|0] "" IPB_App1
 SG_ StatusBLECSFBD_MM_FBDonlyThresho : 88|8@1+ (1.0,0) [0|252] "" IPB_App1
 SG_ StatusBLECSFBD_MM_InlinePCT : 96|8@1+ (1,0) [0|0] "" IPB_App1

BO_ 373 StatusBLECSFBD_Trunk: 16 FBD_Trunk
 SG_ StatusBLECSFBD_Trunk_SessionID : 0|8@1+ (1.0,0) [0|252] "" IPB_App1
 SG_ StatusBLECSFBD_Trunk_IRKListID : 8|8@1+ (1.0,0) [0|252] "" IPB_App1
 SG_ StatusBLECSFBD_Trunk_DeviceGroup : 16|8@1+ (1.0,0) [0|252] "" IPB_App1
 SG_ StatusBLECSFBD_Trunk_Algorithm : 24|8@1+ (1,0) [0|0] "" IPB_App1
 SG_ StatusBLECSFBD_Trunk_DistanceOff : 32|16@1+ (1.0,0) [0|65532] "" IPB_App1
 SG_ StatusBLECSFBD_Trunk_AntennaConf : 48|8@1+ (1,0) [0|0] "" IPB_App1
 SG_ StatusBLECSFBD_Trunk_TxPower : 56|8@1+ (1.0,0) [0|252] "" IPB_App1
 SG_ StatusBLECSFBD_Trunk_Role : 64|8@1+ (1,0) [0|0] "" IPB_App1
 SG_ StatusBLECSFBD_Trunk_ProcedureRe : 72|8@1+ (1,0) [0|0] "" IPB_App1
 SG_ StatusBLECSFBD_Trunk_AntennaPath : 80|8@1+ (1,0) [0|0] "" IPB_App1
 SG_ StatusBLECSFBD_Trunk_FBDonlyThre : 88|8@1+ (1.0,0) [0|252] "" IPB_App1
 SG_ StatusBLECSFBD_Trunk_InlinePCT : 96|8@1+ (1,0) [0|0] "" IPB_App1

BO_ 374 StatusBLECSFBD_VL: 16 FBD_VL
 SG_ StatusBLECSFBD_VL_SessionID : 0|8@1+ (1.0,0) [0|252] "" IPB_App1
 SG_ StatusBLECSFBD_VL_IRKListID : 8|8@1+ (1.0,0) [0|252] "" IPB_App1
 SG_ StatusBLECSFBD_VL_DeviceGroup : 16|8@1+ (1.0,0) [0|252] "" IPB_App1
 SG_ StatusBLECSFBD_VL_Algorithm : 24|8@1+ (1,0) [0|0] "" IPB_App1
 SG_ StatusBLECSFBD_VL_DistanceOffset : 32|16@1+ (1.0,0) [0|65532] "" IPB_App1
 SG_ StatusBLECSFBD_VL_AntennaConfig : 48|8@1+ (1,0) [0|0] "" IPB_App1
 SG_ StatusBLECSFBD_VL_TxPower : 56|8@1+ (1.0,0) [0|252] "" IPB_App1
 SG_ StatusBLECSFBD_VL_Role : 64|8@1+ (1,0) [0|0] "" IPB_App1
 SG_ StatusBLECSFBD_VL_ProcedureResul : 72|8@1+ (1,0) [0|0] "" IPB_App1
 SG_ StatusBLECSFBD_VL_AntennaPathPro : 80|8@1+ (1,0) [0|0] "" IPB_App1
 SG_ StatusBLECSFBD_VL_FBDonlyThresho : 88|8@1+ (1.0,0) [0|252] "" IPB_App1
 SG_ StatusBLECSFBD_VL_InlinePCT : 96|8@1+ (1,0) [0|0] "" IPB_App1

BO_ 370 StatusBLECSFBD_VM: 16 FBD_VM
 SG_ StatusBLECSFBD_VM_SessionID : 0|8@1+ (1.0,0) [0|252] "" IPB_App1
 SG_ StatusBLECSFBD_VM_IRKListID : 8|8@1+ (1.0,0) [0|252] "" IPB_App1
 SG_ StatusBLECSFBD_VM_DeviceGroup : 16|8@1+ (1.0,0) [0|252] "" IPB_App1
 SG_ StatusBLECSFBD_VM_Algorithm : 24|8@1+ (1,0) [0|0] "" IPB_App1
 SG_ StatusBLECSFBD_VM_DistanceOffset : 32|16@1+ (1.0,0) [0|65532] "" IPB_App1
 SG_ StatusBLECSFBD_VM_AntennaConfig : 48|8@1+ (1,0) [0|0] "" IPB_App1
 SG_ StatusBLECSFBD_VM_TxPower : 56|8@1+ (1.0,0) [0|252] "" IPB_App1
 SG_ StatusBLECSFBD_VM_Role : 64|8@1+ (1,0) [0|0] "" IPB_App1
 SG_ StatusBLECSFBD_VM_ProcedureResul : 72|8@1+ (1,0) [0|0] "" IPB_App1
 SG_ StatusBLECSFBD_VM_AntennaPathPro : 80|8@1+ (1,0) [0|0] "" IPB_App1
 SG_ StatusBLECSFBD_VM_FBDonlyThresho : 88|8@1+ (1.0,0) [0|252] "" IPB_App1
 SG_ StatusBLECSFBD_VM_InlinePCT : 96|8@1+ (1,0) [0|0] "" IPB_App1

BO_ 375 StatusBLECSFBD_VR: 16 FBD_VR
 SG_ StatusBLECSFBD_VR_SessionID : 0|8@1+ (1.0,0) [0|252] "" IPB_App1
 SG_ StatusBLECSFBD_VR_IRKListID : 8|8@1+ (1.0,0) [0|252] "" IPB_App1
 SG_ StatusBLECSFBD_VR_DeviceGroup : 16|8@1+ (1.0,0) [0|252] "" IPB_App1
 SG_ StatusBLECSFBD_VR_Algorithm : 24|8@1+ (1,0) [0|0] "" IPB_App1
 SG_ StatusBLECSFBD_VR_DistanceOffset : 32|16@1+ (1.0,0) [0|65532] "" IPB_App1
 SG_ StatusBLECSFBD_VR_AntennaConfig : 48|8@1+ (1,0) [0|0] "" IPB_App1
 SG_ StatusBLECSFBD_VR_TxPower : 56|8@1+ (1.0,0) [0|252] "" IPB_App1
 SG_ StatusBLECSFBD_VR_Role : 64|8@1+ (1,0) [0|0] "" IPB_App1
 SG_ StatusBLECSFBD_VR_ProcedureResul : 72|8@1+ (1,0) [0|0] "" IPB_App1
 SG_ StatusBLECSFBD_VR_AntennaPathPro : 80|8@1+ (1,0) [0|0] "" IPB_App1
 SG_ StatusBLECSFBD_VR_FBDonlyThresho : 88|8@1+ (1.0,0) [0|252] "" IPB_App1
 SG_ StatusBLECSFBD_VR_InlinePCT : 96|8@1+ (1,0) [0|0] "" IPB_App1

BO_ 656 StatusBLEDeviceNameFBD_HL: 32 FBD_HL
 SG_ StatusBLEDeviceNameFBD_HL_Charac : 0|8@1+ (1.0,0) [0|252] "" IPB_App1
 SG_ StatusBLEDeviceNameFBD_HL_Char_2 : 8|8@1+ (1.0,0) [0|252] "" IPB_App1
 SG_ StatusBLEDeviceNameFBD_HL_Char_3 : 16|8@1+ (1.0,0) [0|252] "" IPB_App1
 SG_ StatusBLEDeviceNameFBD_HL_Char_4 : 24|8@1+ (1.0,0) [0|252] "" IPB_App1
 SG_ StatusBLEDeviceNameFBD_HL_Char_5 : 32|8@1+ (1.0,0) [0|252] "" IPB_App1
 SG_ StatusBLEDeviceNameFBD_HL_Char_6 : 40|8@1+ (1.0,0) [0|252] "" IPB_App1
 SG_ StatusBLEDeviceNameFBD_HL_Char_7 : 48|8@1+ (1.0,0) [0|252] "" IPB_App1
 SG_ StatusBLEDeviceNameFBD_HL_Char_8 : 56|8@1+ (1.0,0) [0|252] "" IPB_App1
 SG_ StatusBLEDeviceNameFBD_HL_Char_9 : 64|8@1+ (1.0,0) [0|252] "" IPB_App1
 SG_ StatusBLEDeviceNameFBD_HL_Cha_10 : 72|8@1+ (1.0,0) [0|252] "" IPB_App1
 SG_ StatusBLEDeviceNameFBD_HL_Cha_11 : 80|8@1+ (1.0,0) [0|252] "" IPB_App1
 SG_ StatusBLEDeviceNameFBD_HL_Cha_12 : 88|8@1+ (1.0,0) [0|252] "" IPB_App1
 SG_ StatusBLEDeviceNameFBD_HL_Cha_13 : 96|8@1+ (1.0,0) [0|252] "" IPB_App1
 SG_ StatusBLEDeviceNameFBD_HL_Cha_14 : 104|8@1+ (1.0,0) [0|252] "" IPB_App1
 SG_ StatusBLEDeviceNameFBD_HL_Cha_15 : 112|8@1+ (1.0,0) [0|252] "" IPB_App1
 SG_ StatusBLEDeviceNameFBD_HL_Cha_16 : 120|8@1+ (1.0,0) [0|252] "" IPB_App1
 SG_ StatusBLEDeviceNameFBD_HL_Cha_17 : 128|8@1+ (1.0,0) [0|252] "" IPB_App1
 SG_ StatusBLEDeviceNameFBD_HL_Cha_18 : 136|8@1+ (1.0,0) [0|252] "" IPB_App1
 SG_ StatusBLEDeviceNameFBD_HL_Cha_19 : 144|8@1+ (1.0,0) [0|252] "" IPB_App1
 SG_ StatusBLEDeviceNameFBD_HL_Cha_20 : 152|8@1+ (1.0,0) [0|252] "" IPB_App1
 SG_ StatusBLEDeviceNameFBD_HL_Cha_21 : 160|8@1+ (1.0,0) [0|252] "" IPB_App1
 SG_ StatusBLEDeviceNameFBD_HL_Cha_22 : 168|8@1+ (1.0,0) [0|252] "" IPB_App1
 SG_ StatusBLEDeviceNameFBD_HL_Cha_23 : 176|8@1+ (1.0,0) [0|252] "" IPB_App1
 SG_ StatusBLEDeviceNameFBD_HL_Cha_24 : 184|8@1+ (1.0,0) [0|252] "" IPB_App1
 SG_ StatusBLEDeviceNameFBD_HL_Cha_25 : 192|8@1+ (1.0,0) [0|252] "" IPB_App1
 SG_ StatusBLEDeviceNameFBD_HL_Cha_26 : 200|8@1+ (1.0,0) [0|252] "" IPB_App1
 SG_ StatusBLEDeviceNameFBD_HL_Cha_27 : 208|8@1+ (1.0,0) [0|252] "" IPB_App1
 SG_ StatusBLEDeviceNameFBD_HL_Cha_28 : 216|8@1+ (1.0,0) [0|252] "" IPB_App1
 SG_ StatusBLEDeviceNameFBD_HL_Cha_29 : 224|8@1+ (1.0,0) [0|252] "" IPB_App1
 SG_ StatusBLEDeviceNameFBD_HL_Cha_30 : 232|8@1+ (1.0,0) [0|252] "" IPB_App1

CM_ SG_ 574 ResultBLERSSIRangingIntentFBD_VL "addressing of the UWB anchors";
CM_ SG_ 574 ResultBLERSSIRangingIntentFBD__2 "contains IRK List ID";
CM_ SG_ 574 ResultBLERSSIRangingIntentFBD__3 "contains status to motion detection";
CM_ SG_ 574 ResultBLERSSIRangingIntentFBD__4 "containes decision confidence";
CM_ SG_ 570 ResultBLERSSIRangingIntentFBD_VM "addressing of the UWB anchors";
CM_ SG_ 570 ResultBLERSSIRangingIntentFBD__2 "contains IRK List ID";
CM_ SG_ 570 ResultBLERSSIRangingIntentFBD__3 "contains status to motion detection";
CM_ SG_ 570 ResultBLERSSIRangingIntentFBD__4 "containes decision confidence";
CM_ SG_ 575 ResultBLERSSIRangingIntentFBD_VR "addressing of the UWB anchors";
CM_ SG_ 575 ResultBLERSSIRangingIntentFBD__2 "contains IRK List ID";
CM_ SG_ 575 ResultBLERSSIRangingIntentFBD__3 "contains status to motion detection";
CM_ SG_ 575 ResultBLERSSIRangingIntentFBD__4 "containes decision confidence";
CM_ SG_ 486 ResumeRangingSessionFBD_HL_Funct "contains function";
CM_ SG_ 486 ResumeRangingSessionFBD_HL_Sessi "definition of Session-ID";
CM_ SG_ 486 ResumeRangingSessionFBD_HL_STSIn "contains STS-Index";
CM_ SG_ 486 ResumeRangingSessionFBD_HL_RANMu "set RAN multiplier";
CM_ SG_ 486 ResumeRangingSessionFBD_HL_UWBTi "contains NONCE, only signal TAG 0xFF possible";
CM_ SG_ 486 ResumeRangingSessionFBD_HL_ToFSt "contains status to ToF reception";
CM_ SG_ 486 ResumeRangingSessionFBD_HL_Rangi "contains Ranging Round Index (Hopping Offset)";
CM_ SG_ 486 ResumeRangingSessionFBD_HL_Ran_2 "contains Ranging Block Index (Frame Index)";
CM_ SG_ 481 ResumeRangingSessionFBD_HM_Funct "contains function";
CM_ SG_ 481 ResumeRangingSessionFBD_HM_Sessi "definition of Session-ID";
CM_ SG_ 481 ResumeRangingSessionFBD_HM_STSIn "contains STS-Index";
CM_ SG_ 481 ResumeRangingSessionFBD_HM_RANMu "set RAN multiplier";
CM_ SG_ 481 ResumeRangingSessionFBD_HM_UWBTi "contains NONCE, only signal TAG 0xFF possible";
CM_ SG_ 481 ResumeRangingSessionFBD_HM_ToFSt "contains status to ToF reception";
CM_ SG_ 481 ResumeRangingSessionFBD_HM_Rangi "contains Ranging Round Index (Hopping Offset)";
CM_ SG_ 481 ResumeRangingSessionFBD_HM_Ran_2 "contains Ranging Block Index (Frame Index)";
CM_ SG_ 487 ResumeRangingSessionFBD_HR_Funct "contains function";
CM_ SG_ 487 ResumeRangingSessionFBD_HR_Sessi "definition of Session-ID";
CM_ SG_ 487 ResumeRangingSessionFBD_HR_STSIn "contains STS-Index";
CM_ SG_ 487 ResumeRangingSessionFBD_HR_RANMu "set RAN multiplier";
CM_ SG_ 487 ResumeRangingSessionFBD_HR_UWBTi "contains NONCE, only signal TAG 0xFF possible";
CM_ SG_ 487 ResumeRangingSessionFBD_HR_ToFSt "contains status to ToF reception";
CM_ SG_ 487 ResumeRangingSessionFBD_HR_Rangi "contains Ranging Round Index (Hopping Offset)";
CM_ SG_ 487 ResumeRangingSessionFBD_HR_Ran_2 "contains Ranging Block Index (Frame Index)";
CM_ SG_ 482 ResumeRangingSessionFBD_Miko_Fun "contains function";
CM_ SG_ 482 ResumeRangingSessionFBD_Miko_Ses "definition of Session-ID";
CM_ SG_ 482 ResumeRangingSessionFBD_Miko_STS "contains STS-Index";
CM_ SG_ 482 ResumeRangingSessionFBD_Miko_RAN "set RAN multiplier";
CM_ SG_ 482 ResumeRangingSessionFBD_Miko_UWB "contains NONCE, only signal TAG 0xFF possible";
CM_ SG_ 482 ResumeRangingSessionFBD_Miko_ToF "contains status to ToF reception";
CM_ SG_ 482 ResumeRangingSessionFBD_Miko_Ran "contains Ranging Round Index (Hopping Offset)";
CM_ SG_ 482 ResumeRangingSessionFBD_Miko_R_2 "contains Ranging Block Index (Frame Index)";
CM_ SG_ 442 ResumeRangingSessionFBD_MM_Funct "contains function";
CM_ SG_ 442 ResumeRangingSessionFBD_MM_Sessi "definition of Session-ID";
CM_ SG_ 442 ResumeRangingSessionFBD_MM_STSIn "contains STS-Index";
CM_ SG_ 442 ResumeRangingSessionFBD_MM_RANMu "set RAN multiplier";
CM_ SG_ 442 ResumeRangingSessionFBD_MM_UWBTi "contains Time0";
CM_ SG_ 442 ResumeRangingSessionFBD_MM_ToFSt "contains status to ToF reception";
CM_ SG_ 442 ResumeRangingSessionFBD_MM_Rangi "contains Ranging Round Index (Hopping Offset)";
CM_ SG_ 442 ResumeRangingSessionFBD_MM_Ran_2 "contains Ranging Block Index (Frame Index)";
CM_ SG_ 488 ResumeRangingSessionFBD_SML_Func "contains function";
CM_ SG_ 488 ResumeRangingSessionFBD_SML_Sess "definition of Session-ID";
CM_ SG_ 488 ResumeRangingSessionFBD_SML_STSI "contains STS-Index";
CM_ SG_ 488 ResumeRangingSessionFBD_SML_RANM "set RAN multiplier";
CM_ SG_ 488 ResumeRangingSessionFBD_SML_UWBT "contains NONCE, only signal TAG 0xFF possible";
CM_ SG_ 488 ResumeRangingSessionFBD_SML_ToFS "contains status to ToF reception";
CM_ SG_ 488 ResumeRangingSessionFBD_SML_Rang "contains Ranging Round Index (Hopping Offset)";
CM_ SG_ 488 ResumeRangingSessionFBD_SML_Ra_2 "contains Ranging Block Index (Frame Index)";
CM_ SG_ 489 ResumeRangingSessionFBD_SMR_Func "contains function";
CM_ SG_ 489 ResumeRangingSessionFBD_SMR_Sess "definition of Session-ID";
CM_ SG_ 489 ResumeRangingSessionFBD_SMR_STSI "contains STS-Index";
CM_ SG_ 489 ResumeRangingSessionFBD_SMR_RANM "set RAN multiplier";
CM_ SG_ 489 ResumeRangingSessionFBD_SMR_UWBT "contains NONCE, only signal TAG 0xFF possible";
CM_ SG_ 489 ResumeRangingSessionFBD_SMR_ToFS "contains status to ToF reception";
CM_ SG_ 489 ResumeRangingSessionFBD_SMR_Rang "contains Ranging Round Index (Hopping Offset)";
CM_ SG_ 489 ResumeRangingSessionFBD_SMR_Ra_2 "contains Ranging Block Index (Frame Index)";
CM_ SG_ 483 ResumeRangingSessionFBD_Trunk_Fu "contains function";
CM_ SG_ 483 ResumeRangingSessionFBD_Trunk_Se "definition of Session-ID";
CM_ SG_ 483 ResumeRangingSessionFBD_Trunk_ST "contains STS-Index";
CM_ SG_ 483 ResumeRangingSessionFBD_Trunk_RA "set RAN multiplier";
CM_ SG_ 483 ResumeRangingSessionFBD_Trunk_UW "contains NONCE, only signal TAG 0xFF possible";
CM_ SG_ 483 ResumeRangingSessionFBD_Trunk_To "contains status to ToF reception";
CM_ SG_ 483 ResumeRangingSessionFBD_Trunk_Ra "contains Ranging Round Index (Hopping Offset)";
CM_ SG_ 483 ResumeRangingSessionFBD_Trunk__2 "contains Ranging Block Index (Frame Index)";
CM_ SG_ 484 ResumeRangingSessionFBD_VL_Funct "contains function";
CM_ SG_ 484 ResumeRangingSessionFBD_VL_Sessi "definition of Session-ID";
CM_ SG_ 484 ResumeRangingSessionFBD_VL_STSIn "contains STS-Index";
CM_ SG_ 484 ResumeRangingSessionFBD_VL_RANMu "set RAN multiplier";
CM_ SG_ 484 ResumeRangingSessionFBD_VL_UWBTi "contains NONCE, only signal TAG 0xFF possible";
CM_ SG_ 484 ResumeRangingSessionFBD_VL_ToFSt "contains status to ToF reception";
CM_ SG_ 484 ResumeRangingSessionFBD_VL_Rangi "contains Ranging Round Index (Hopping Offset)";
CM_ SG_ 484 ResumeRangingSessionFBD_VL_Ran_2 "contains Ranging Block Index (Frame Index)";
CM_ SG_ 480 ResumeRangingSessionFBD_VM_Funct "contains function";
CM_ SG_ 480 ResumeRangingSessionFBD_VM_Sessi "definition of Session-ID";
CM_ SG_ 480 ResumeRangingSessionFBD_VM_STSIn "contains STS-Index";
CM_ SG_ 480 ResumeRangingSessionFBD_VM_RANMu "set RAN multiplier";
CM_ SG_ 480 ResumeRangingSessionFBD_VM_UWBTi "contains NONCE, only signal TAG 0xFF possible";
CM_ SG_ 480 ResumeRangingSessionFBD_VM_ToFSt "contains status to ToF reception";
CM_ SG_ 480 ResumeRangingSessionFBD_VM_Rangi "contains Ranging Round Index (Hopping Offset)";
CM_ SG_ 480 ResumeRangingSessionFBD_VM_Ran_2 "contains Ranging Block Index (Frame Index)";
CM_ SG_ 485 ResumeRangingSessionFBD_VR_Funct "contains function";
CM_ SG_ 485 ResumeRangingSessionFBD_VR_Sessi "definition of Session-ID";
CM_ SG_ 485 ResumeRangingSessionFBD_VR_STSIn "contains STS-Index";
CM_ SG_ 485 ResumeRangingSessionFBD_VR_RANMu "set RAN multiplier";
CM_ SG_ 485 ResumeRangingSessionFBD_VR_UWBTi "contains NONCE, only signal TAG 0xFF possible";
CM_ SG_ 485 ResumeRangingSessionFBD_VR_ToFSt "contains status to ToF reception";
CM_ SG_ 485 ResumeRangingSessionFBD_VR_Rangi "contains Ranging Round Index (Hopping Offset)";
CM_ SG_ 485 ResumeRangingSessionFBD_VR_Ran_2 "contains Ranging Block Index (Frame Index)";
CM_ SG_ 276 SeamlessBLEStatusFBD_HL_NumberAc "number of active BLE connections";
CM_ SG_ 276 SeamlessBLEStatusFBD_HL_Connecti "connection ID1";
CM_ SG_ 276 SeamlessBLEStatusFBD_HL_Connec_2 "receive power to connection ID1 (Range: -127 ... -1 dB / step: 0.5dB)";
CM_ SG_ 276 SeamlessBLEStatusFBD_HL_Connec_3 "connection ID2";
CM_ SG_ 276 SeamlessBLEStatusFBD_HL_Connec_4 "receive power to connection ID2 (Range: -127 ... -1 dB / step: 0.5dB)";
CM_ SG_ 276 SeamlessBLEStatusFBD_HL_Connec_5 "connection ID3";
CM_ SG_ 276 SeamlessBLEStatusFBD_HL_Connec_6 "receive power to connection ID3 (Range: -127 ... -1 dB / step: 0.5dB)";
CM_ SG_ 276 SeamlessBLEStatusFBD_HL_Connec_7 "connection ID4";
CM_ SG_ 276 SeamlessBLEStatusFBD_HL_Connec_8 "receive power to connection ID4 (Range: -127 ... -1 dB / step: 0.5dB)";
CM_ SG_ 276 SeamlessBLEStatusFBD_HL_Connec_9 "connection ID5";
CM_ SG_ 276 SeamlessBLEStatusFBD_HL_Conne_10 "receive power to connection ID5 (Range: -127 ... -1 dB / step: 0.5dB)";
CM_ SG_ 276 SeamlessBLEStatusFBD_HL_Conne_11 "connection ID6";
CM_ SG_ 276 SeamlessBLEStatusFBD_HL_Conne_12 "receive power to connection ID6 (Range: -127 ... -1 dB / step: 0.5dB)";
CM_ SG_ 276 SeamlessBLEStatusFBD_HL_Conne_13 "connection ID7";
CM_ SG_ 276 SeamlessBLEStatusFBD_HL_Conne_14 "receive power to connection ID7 (Range: -127 ... -1 dB / step: 0.5dB)";
CM_ SG_ 276 SeamlessBLEStatusFBD_HL_Conne_15 "connection ID8";
CM_ SG_ 276 SeamlessBLEStatusFBD_HL_Conne_16 "receive power to connection ID8 (Range: -127 ... -1 dB / step: 0.5dB)";
CM_ SG_ 271 SeamlessBLEStatusFBD_HM_NumberAc "number of active BLE connections";
CM_ SG_ 271 SeamlessBLEStatusFBD_HM_Connecti "connection ID1";
CM_ SG_ 271 SeamlessBLEStatusFBD_HM_Connec_2 "receive power to connection ID1 (Range: -127 ... -1 dB / step: 0.5dB)";
CM_ SG_ 271 SeamlessBLEStatusFBD_HM_Connec_3 "connection ID2";
CM_ SG_ 271 SeamlessBLEStatusFBD_HM_Connec_4 "receive power to connection ID2 (Range: -127 ... -1 dB / step: 0.5dB)";
CM_ SG_ 271 SeamlessBLEStatusFBD_HM_Connec_5 "connection ID3";
CM_ SG_ 271 SeamlessBLEStatusFBD_HM_Connec_6 "receive power to connection ID3 (Range: -127 ... -1 dB / step: 0.5dB)";
CM_ SG_ 271 SeamlessBLEStatusFBD_HM_Connec_7 "connection ID4";
CM_ SG_ 271 SeamlessBLEStatusFBD_HM_Connec_8 "receive power to connection ID4 (Range: -127 ... -1 dB / step: 0.5dB)";
CM_ SG_ 271 SeamlessBLEStatusFBD_HM_Connec_9 "connection ID5";
CM_ SG_ 271 SeamlessBLEStatusFBD_HM_Conne_10 "receive power to connection ID5 (Range: -127 ... -1 dB / step: 0.5dB)";
CM_ SG_ 271 SeamlessBLEStatusFBD_HM_Conne_11 "connection ID6";
CM_ SG_ 271 SeamlessBLEStatusFBD_HM_Conne_12 "receive power to connection ID6 (Range: -127 ... -1 dB / step: 0.5dB)";
CM_ SG_ 271 SeamlessBLEStatusFBD_HM_Conne_13 "connection ID7";
CM_ SG_ 271 SeamlessBLEStatusFBD_HM_Conne_14 "receive power to connection ID7 (Range: -127 ... -1 dB / step: 0.5dB)";
CM_ SG_ 271 SeamlessBLEStatusFBD_HM_Conne_15 "connection ID8";
CM_ SG_ 271 SeamlessBLEStatusFBD_HM_Conne_16 "receive power to connection ID8 (Range: -127 ... -1 dB / step: 0.5dB)";
CM_ SG_ 277 SeamlessBLEStatusFBD_HR_NumberAc "number of active BLE connections";
CM_ SG_ 277 SeamlessBLEStatusFBD_HR_Connecti "connection ID1";
CM_ SG_ 277 SeamlessBLEStatusFBD_HR_Connec_2 "receive power to connection ID1 (Range: -127 ... -1 dB / step: 0.5dB)";
CM_ SG_ 277 SeamlessBLEStatusFBD_HR_Connec_3 "connection ID2";
CM_ SG_ 277 SeamlessBLEStatusFBD_HR_Connec_4 "receive power to connection ID2 (Range: -127 ... -1 dB / step: 0.5dB)";
CM_ SG_ 277 SeamlessBLEStatusFBD_HR_Connec_5 "connection ID3";
CM_ SG_ 277 SeamlessBLEStatusFBD_HR_Connec_6 "receive power to connection ID3 (Range: -127 ... -1 dB / step: 0.5dB)";
CM_ SG_ 277 SeamlessBLEStatusFBD_HR_Connec_7 "connection ID4";
CM_ SG_ 277 SeamlessBLEStatusFBD_HR_Connec_8 "receive power to connection ID4 (Range: -127 ... -1 dB / step: 0.5dB)";
CM_ SG_ 277 SeamlessBLEStatusFBD_HR_Connec_9 "connection ID5";
CM_ SG_ 277 SeamlessBLEStatusFBD_HR_Conne_10 "receive power to connection ID5 (Range: -127 ... -1 dB / step: 0.5dB)";
CM_ SG_ 277 SeamlessBLEStatusFBD_HR_Conne_11 "connection ID6";
CM_ SG_ 277 SeamlessBLEStatusFBD_HR_Conne_12 "receive power to connection ID6 (Range: -127 ... -1 dB / step: 0.5dB)";
CM_ SG_ 277 SeamlessBLEStatusFBD_HR_Conne_13 "connection ID7";
CM_ SG_ 277 SeamlessBLEStatusFBD_HR_Conne_14 "receive power to connection ID7 (Range: -127 ... -1 dB / step: 0.5dB)";
CM_ SG_ 277 SeamlessBLEStatusFBD_HR_Conne_15 "connection ID8";
CM_ SG_ 277 SeamlessBLEStatusFBD_HR_Conne_16 "receive power to connection ID8 (Range: -127 ... -1 dB / step: 0.5dB)";
CM_ SG_ 272 SeamlessBLEStatusFBD_Miko_Number "number of active BLE connections";
CM_ SG_ 272 SeamlessBLEStatusFBD_Miko_Connec "connection ID1";
CM_ SG_ 272 SeamlessBLEStatusFBD_Miko_Conn_2 "receive power to connection ID1 (Range: -127 ... -1 dB / step: 0.5dB)";
CM_ SG_ 272 SeamlessBLEStatusFBD_Miko_Conn_3 "connection ID2";
CM_ SG_ 272 SeamlessBLEStatusFBD_Miko_Conn_4 "receive power to connection ID2 (Range: -127 ... -1 dB / step: 0.5dB)";
CM_ SG_ 272 SeamlessBLEStatusFBD_Miko_Conn_5 "connection ID3";
CM_ SG_ 272 SeamlessBLEStatusFBD_Miko_Conn_6 "receive power to connection ID3 (Range: -127 ... -1 dB / step: 0.5dB)";
CM_ SG_ 272 SeamlessBLEStatusFBD_Miko_Conn_7 "connection ID4";
CM_ SG_ 272 SeamlessBLEStatusFBD_Miko_Conn_8 "receive power to connection ID4 (Range: -127 ... -1 dB / step: 0.5dB)";
CM_ SG_ 272 SeamlessBLEStatusFBD_Miko_Conn_9 "connection ID5";
CM_ SG_ 272 SeamlessBLEStatusFBD_Miko_Con_10 "receive power to connection ID5 (Range: -127 ... -1 dB / step: 0.5dB)";
CM_ SG_ 272 SeamlessBLEStatusFBD_Miko_Con_11 "connection ID6";
CM_ SG_ 272 SeamlessBLEStatusFBD_Miko_Con_12 "receive power to connection ID6 (Range: -127 ... -1 dB / step: 0.5dB)";
CM_ SG_ 272 SeamlessBLEStatusFBD_Miko_Con_13 "connection ID7";
CM_ SG_ 272 SeamlessBLEStatusFBD_Miko_Con_14 "receive power to connection ID7 (Range: -127 ... -1 dB / step: 0.5dB)";
CM_ SG_ 272 SeamlessBLEStatusFBD_Miko_Con_15 "connection ID8";
CM_ SG_ 272 SeamlessBLEStatusFBD_Miko_Con_16 "receive power to connection ID8 (Range: -127 ... -1 dB / step: 0.5dB)";
CM_ SG_ 822 SeamlessBLEStatusFBD_MM_NumberAc "number of active BLE connections";
CM_ SG_ 822 SeamlessBLEStatusFBD_MM_Connecti "connection ID1";
CM_ SG_ 822 SeamlessBLEStatusFBD_MM_Connec_2 "receive power to connection ID1 (Range: -127 ... -1 dB / step: 0.5dB)";
CM_ SG_ 822 SeamlessBLEStatusFBD_MM_Connec_3 "connection ID2";
CM_ SG_ 822 SeamlessBLEStatusFBD_MM_Connec_4 "receive power to connection ID2 (Range: -127 ... -1 dB / step: 0.5dB)";
CM_ SG_ 822 SeamlessBLEStatusFBD_MM_Connec_5 "connection ID3";
CM_ SG_ 822 SeamlessBLEStatusFBD_MM_Connec_6 "receive power to connection ID3 (Range: -127 ... -1 dB / step: 0.5dB)";
CM_ SG_ 822 SeamlessBLEStatusFBD_MM_Connec_7 "connection ID4";
CM_ SG_ 822 SeamlessBLEStatusFBD_MM_Connec_8 "receive power to connection ID4 (Range: -127 ... -1 dB / step: 0.5dB)";
CM_ SG_ 822 SeamlessBLEStatusFBD_MM_Connec_9 "connection ID5";
CM_ SG_ 822 SeamlessBLEStatusFBD_MM_Conne_10 "receive power to connection ID5 (Range: -127 ... -1 dB / step: 0.5dB)";
CM_ SG_ 822 SeamlessBLEStatusFBD_MM_Conne_11 "connection ID6";
CM_ SG_ 822 SeamlessBLEStatusFBD_MM_Conne_12 "receive power to connection ID6 (Range: -127 ... -1 dB / step: 0.5dB)";
CM_ SG_ 822 SeamlessBLEStatusFBD_MM_Conne_13 "connection ID7";
CM_ SG_ 822 SeamlessBLEStatusFBD_MM_Conne_14 "receive power to connection ID7 (Range: -127 ... -1 dB / step: 0.5dB)";
CM_ SG_ 822 SeamlessBLEStatusFBD_MM_Conne_15 "connection ID8";
CM_ SG_ 822 SeamlessBLEStatusFBD_MM_Conne_16 "receive power to connection ID8 (Range: -127 ... -1 dB / step: 0.5dB)";
CM_ SG_ 273 SeamlessBLEStatusFBD_Trunk_Numbe "number of active BLE connections";
CM_ SG_ 273 SeamlessBLEStatusFBD_Trunk_Conne "connection ID1";
CM_ SG_ 273 SeamlessBLEStatusFBD_Trunk_Con_2 "receive power to connection ID1 (Range: -127 ... -1 dB / step: 0.5dB)";
CM_ SG_ 273 SeamlessBLEStatusFBD_Trunk_Con_3 "connection ID2";
CM_ SG_ 273 SeamlessBLEStatusFBD_Trunk_Con_4 "receive power to connection ID2 (Range: -127 ... -1 dB / step: 0.5dB)";
CM_ SG_ 273 SeamlessBLEStatusFBD_Trunk_Con_5 "connection ID3";
CM_ SG_ 273 SeamlessBLEStatusFBD_Trunk_Con_6 "receive power to connection ID3 (Range: -127 ... -1 dB / step: 0.5dB)";
CM_ SG_ 273 SeamlessBLEStatusFBD_Trunk_Con_7 "connection ID4";
CM_ SG_ 273 SeamlessBLEStatusFBD_Trunk_Con_8 "receive power to connection ID4 (Range: -127 ... -1 dB / step: 0.5dB)";
CM_ SG_ 273 SeamlessBLEStatusFBD_Trunk_Con_9 "connection ID5";
CM_ SG_ 273 SeamlessBLEStatusFBD_Trunk_Co_10 "receive power to connection ID5 (Range: -127 ... -1 dB / step: 0.5dB)";
CM_ SG_ 273 SeamlessBLEStatusFBD_Trunk_Co_11 "connection ID6";
CM_ SG_ 273 SeamlessBLEStatusFBD_Trunk_Co_12 "receive power to connection ID6 (Range: -127 ... -1 dB / step: 0.5dB)";
CM_ SG_ 273 SeamlessBLEStatusFBD_Trunk_Co_13 "connection ID7";
CM_ SG_ 273 SeamlessBLEStatusFBD_Trunk_Co_14 "receive power to connection ID7 (Range: -127 ... -1 dB / step: 0.5dB)";
CM_ SG_ 273 SeamlessBLEStatusFBD_Trunk_Co_15 "connection ID8";
CM_ SG_ 273 SeamlessBLEStatusFBD_Trunk_Co_16 "receive power to connection ID8 (Range: -127 ... -1 dB / step: 0.5dB)";
CM_ SG_ 274 SeamlessBLEStatusFBD_VL_NumberAc "number of active BLE connections";
CM_ SG_ 274 SeamlessBLEStatusFBD_VL_Connecti "connection ID1";
CM_ SG_ 274 SeamlessBLEStatusFBD_VL_Connec_2 "receive power to connection ID1 (Range: -127 ... -1 dB / step: 0.5dB)";
CM_ SG_ 274 SeamlessBLEStatusFBD_VL_Connec_3 "connection ID2";
CM_ SG_ 274 SeamlessBLEStatusFBD_VL_Connec_4 "receive power to connection ID2 (Range: -127 ... -1 dB / step: 0.5dB)";
CM_ SG_ 274 SeamlessBLEStatusFBD_VL_Connec_5 "connection ID3";
CM_ SG_ 274 SeamlessBLEStatusFBD_VL_Connec_6 "receive power to connection ID3 (Range: -127 ... -1 dB / step: 0.5dB)";
CM_ SG_ 274 SeamlessBLEStatusFBD_VL_Connec_7 "connection ID4";
CM_ SG_ 274 SeamlessBLEStatusFBD_VL_Connec_8 "receive power to connection ID4 (Range: -127 ... -1 dB / step: 0.5dB)";
CM_ SG_ 274 SeamlessBLEStatusFBD_VL_Connec_9 "connection ID5";
CM_ SG_ 274 SeamlessBLEStatusFBD_VL_Conne_10 "receive power to connection ID5 (Range: -127 ... -1 dB / step: 0.5dB)";
CM_ SG_ 274 SeamlessBLEStatusFBD_VL_Conne_11 "connection ID6";
CM_ SG_ 274 SeamlessBLEStatusFBD_VL_Conne_12 "receive power to connection ID6 (Range: -127 ... -1 dB / step: 0.5dB)";
CM_ SG_ 274 SeamlessBLEStatusFBD_VL_Conne_13 "connection ID7";
CM_ SG_ 274 SeamlessBLEStatusFBD_VL_Conne_14 "receive power to connection ID7 (Range: -127 ... -1 dB / step: 0.5dB)";
CM_ SG_ 274 SeamlessBLEStatusFBD_VL_Conne_15 "connection ID8";
CM_ SG_ 274 SeamlessBLEStatusFBD_VL_Conne_16 "receive power to connection ID8 (Range: -127 ... -1 dB / step: 0.5dB)";
CM_ SG_ 270 SeamlessBLEStatusFBD_VM_NumberAc "number of active BLE connections";
CM_ SG_ 270 SeamlessBLEStatusFBD_VM_Connecti "connection ID1";
CM_ SG_ 270 SeamlessBLEStatusFBD_VM_Connec_2 "receive power to connection ID1 (Range: -127 ... -1 dB / step: 0.5dB)";
CM_ SG_ 270 SeamlessBLEStatusFBD_VM_Connec_3 "connection ID2";
CM_ SG_ 270 SeamlessBLEStatusFBD_VM_Connec_4 "receive power to connection ID2 (Range: -127 ... -1 dB / step: 0.5dB)";
CM_ SG_ 270 SeamlessBLEStatusFBD_VM_Connec_5 "connection ID3";
CM_ SG_ 270 SeamlessBLEStatusFBD_VM_Connec_6 "receive power to connection ID3 (Range: -127 ... -1 dB / step: 0.5dB)";
CM_ SG_ 270 SeamlessBLEStatusFBD_VM_Connec_7 "connection ID4";
CM_ SG_ 270 SeamlessBLEStatusFBD_VM_Connec_8 "receive power to connection ID4 (Range: -127 ... -1 dB / step: 0.5dB)";
CM_ SG_ 270 SeamlessBLEStatusFBD_VM_Connec_9 "connection ID5";
CM_ SG_ 270 SeamlessBLEStatusFBD_VM_Conne_10 "receive power to connection ID5 (Range: -127 ... -1 dB / step: 0.5dB)";
CM_ SG_ 270 SeamlessBLEStatusFBD_VM_Conne_11 "connection ID6";
CM_ SG_ 270 SeamlessBLEStatusFBD_VM_Conne_12 "receive power to connection ID6 (Range: -127 ... -1 dB / step: 0.5dB)";
CM_ SG_ 270 SeamlessBLEStatusFBD_VM_Conne_13 "connection ID7";
CM_ SG_ 270 SeamlessBLEStatusFBD_VM_Conne_14 "receive power to connection ID7 (Range: -127 ... -1 dB / step: 0.5dB)";
CM_ SG_ 270 SeamlessBLEStatusFBD_VM_Conne_15 "connection ID8";
CM_ SG_ 270 SeamlessBLEStatusFBD_VM_Conne_16 "receive power to connection ID8 (Range: -127 ... -1 dB / step: 0.5dB)";
CM_ SG_ 275 SeamlessBLEStatusFBD_VR_NumberAc "number of active BLE connections";
CM_ SG_ 275 SeamlessBLEStatusFBD_VR_Connecti "connection ID1";
CM_ SG_ 275 SeamlessBLEStatusFBD_VR_Connec_2 "receive power to connection ID1 (Range: -127 ... -1 dB / step: 0.5dB)";
CM_ SG_ 275 SeamlessBLEStatusFBD_VR_Connec_3 "connection ID2";
CM_ SG_ 275 SeamlessBLEStatusFBD_VR_Connec_4 "receive power to connection ID2 (Range: -127 ... -1 dB / step: 0.5dB)";
CM_ SG_ 275 SeamlessBLEStatusFBD_VR_Connec_5 "connection ID3";
CM_ SG_ 275 SeamlessBLEStatusFBD_VR_Connec_6 "receive power to connection ID3 (Range: -127 ... -1 dB / step: 0.5dB)";
CM_ SG_ 275 SeamlessBLEStatusFBD_VR_Connec_7 "connection ID4";
CM_ SG_ 275 SeamlessBLEStatusFBD_VR_Connec_8 "receive power to connection ID4 (Range: -127 ... -1 dB / step: 0.5dB)";
CM_ SG_ 275 SeamlessBLEStatusFBD_VR_Connec_9 "connection ID5";
CM_ SG_ 275 SeamlessBLEStatusFBD_VR_Conne_10 "receive power to connection ID5 (Range: -127 ... -1 dB / step: 0.5dB)";
CM_ SG_ 275 SeamlessBLEStatusFBD_VR_Conne_11 "connection ID6";
CM_ SG_ 275 SeamlessBLEStatusFBD_VR_Conne_12 "receive power to connection ID6 (Range: -127 ... -1 dB / step: 0.5dB)";
CM_ SG_ 275 SeamlessBLEStatusFBD_VR_Conne_13 "connection ID7";
CM_ SG_ 275 SeamlessBLEStatusFBD_VR_Conne_14 "receive power to connection ID7 (Range: -127 ... -1 dB / step: 0.5dB)";
CM_ SG_ 275 SeamlessBLEStatusFBD_VR_Conne_15 "connection ID8";
CM_ SG_ 275 SeamlessBLEStatusFBD_VR_Conne_16 "receive power to connection ID8 (Range: -127 ... -1 dB / step: 0.5dB)";
CM_ SG_ 626 StatusBindingFBD_HL_BindingStatu "contains actual binding status";
CM_ SG_ 626 StatusBindingFBD_HL_BindingCount "contains actual binding counter";
CM_ SG_ 626 StatusBindingFBD_HL_BindingSeque "contains actual binding sequence";
CM_ SG_ 626 StatusBindingFBD_HL_Data00 "contains Auth. Signal is encrypted, signal TAG not possible";
CM_ SG_ 626 StatusBindingFBD_HL_Data01 "contains Auth. Signal is encrypted, signal TAG not possible";
CM_ SG_ 626 StatusBindingFBD_HL_Data02 "contains Auth. Signal is encrypted, signal TAG not possible";
CM_ SG_ 626 StatusBindingFBD_HL_Data03 "contains Auth. Signal is encrypted, signal TAG not possible";
CM_ SG_ 626 StatusBindingFBD_HL_Data04 "contains Auth. Signal is encrypted, signal TAG not possible";
CM_ SG_ 626 StatusBindingFBD_HL_Data05 "contains Auth. Signal is encrypted, signal TAG not possible";
CM_ SG_ 626 StatusBindingFBD_HL_Data06 "contains Auth. Signal is encrypted, signal TAG not possible";
CM_ SG_ 626 StatusBindingFBD_HL_Data07 "contains Auth. Signal is encrypted, signal TAG not possible";
CM_ SG_ 626 StatusBindingFBD_HL_Data08 "contains Auth. Signal is encrypted, signal TAG not possible";
CM_ SG_ 626 StatusBindingFBD_HL_Data09 "contains Auth. Signal is encrypted, signal TAG not possible";
CM_ SG_ 626 StatusBindingFBD_HL_Data10 "contains Auth. Signal is encrypted, signal TAG not possible";
CM_ SG_ 626 StatusBindingFBD_HL_Data11 "contains Auth. Signal is encrypted, signal TAG not possible";
CM_ SG_ 626 StatusBindingFBD_HL_Data12 "contains Auth. Signal is encrypted, signal TAG not possible";
CM_ SG_ 626 StatusBindingFBD_HL_Data13 "contains Auth. Signal is encrypted, signal TAG not possible";
CM_ SG_ 626 StatusBindingFBD_HL_Data14 "contains Auth. Signal is encrypted, signal TAG not possible";
CM_ SG_ 626 StatusBindingFBD_HL_Data15 "contains Auth. Signal is encrypted, signal TAG not possible";
CM_ SG_ 626 StatusBindingFBD_HL_Data16 "contains Auth. Signal is encrypted, signal TAG not possible";
CM_ SG_ 626 StatusBindingFBD_HL_Data17 "contains Auth. Signal is encrypted, signal TAG not possible";
CM_ SG_ 626 StatusBindingFBD_HL_Data18 "contains Auth. Signal is encrypted, signal TAG not possible";
CM_ SG_ 626 StatusBindingFBD_HL_Data19 "contains Auth. Signal is encrypted, signal TAG not possible";
CM_ SG_ 626 StatusBindingFBD_HL_Data20 "contains Auth. Signal is encrypted, signal TAG not possible";
CM_ SG_ 626 StatusBindingFBD_HL_Data21 "contains Auth. Signal is encrypted, signal TAG not possible";
CM_ SG_ 626 StatusBindingFBD_HL_Data22 "contains Auth. Signal is encrypted, signal TAG not possible";
CM_ SG_ 626 StatusBindingFBD_HL_Data23 "contains Auth. Signal is encrypted, signal TAG not possible";
CM_ SG_ 626 StatusBindingFBD_HL_Data24 "contains Auth. Signal is encrypted, signal TAG not possible";
CM_ SG_ 626 StatusBindingFBD_HL_Data25 "contains Auth. Signal is encrypted, signal TAG not possible";
CM_ SG_ 626 StatusBindingFBD_HL_Data26 "contains Auth. Signal is encrypted, signal TAG not possible";
CM_ SG_ 626 StatusBindingFBD_HL_Data27 "contains Auth. Signal is encrypted, signal TAG not possible";
CM_ SG_ 626 StatusBindingFBD_HL_Data28 "contains Auth. Signal is encrypted, signal TAG not possible";
CM_ SG_ 626 StatusBindingFBD_HL_Data29 "contains Auth. Signal is encrypted, signal TAG not possible";
CM_ SG_ 626 StatusBindingFBD_HL_Data30 "contains Auth. Signal is encrypted, signal TAG not possible";
CM_ SG_ 626 StatusBindingFBD_HL_Data31 "contains Auth. Signal is encrypted, signal TAG not possible";
CM_ SG_ 626 StatusBindingFBD_HL_Data32 "contains Auth. Signal is encrypted, signal TAG not possible";
CM_ SG_ 626 StatusBindingFBD_HL_Data33 "contains Auth. Signal is encrypted, signal TAG not possible";
CM_ SG_ 626 StatusBindingFBD_HL_Data34 "contains Auth. Signal is encrypted, signal TAG not possible";
CM_ SG_ 626 StatusBindingFBD_HL_Data35 "contains Auth. Signal is encrypted, signal TAG not possible";
CM_ SG_ 626 StatusBindingFBD_HL_Data36 "contains Auth. Signal is encrypted, signal TAG not possible";
CM_ SG_ 626 StatusBindingFBD_HL_Data37 "contains Auth. Signal is encrypted, signal TAG not possible";
CM_ SG_ 626 StatusBindingFBD_HL_Data38 "contains Auth. Signal is encrypted, signal TAG not possible";
CM_ SG_ 626 StatusBindingFBD_HL_Data39 "contains Auth. Signal is encrypted, signal TAG not possible";
CM_ SG_ 626 StatusBindingFBD_HL_Data40 "contains Auth. Signal is encrypted, signal TAG not possible";
CM_ SG_ 626 StatusBindingFBD_HL_Data41 "contains Auth. Signal is encrypted, signal TAG not possible";
CM_ SG_ 626 StatusBindingFBD_HL_Data42 "contains Auth. Signal is encrypted, signal TAG not possible";
CM_ SG_ 626 StatusBindingFBD_HL_Data43 "contains Auth. Signal is encrypted, signal TAG not possible";
CM_ SG_ 626 StatusBindingFBD_HL_Data44 "contains Auth. Signal is encrypted, signal TAG not possible";
CM_ SG_ 626 StatusBindingFBD_HL_Data45 "contains Auth. Signal is encrypted, signal TAG not possible";
CM_ SG_ 626 StatusBindingFBD_HL_Data46 "contains Auth. Signal is encrypted, signal TAG not possible";
CM_ SG_ 626 StatusBindingFBD_HL_Data47 "contains Auth. Signal is encrypted, signal TAG not possible";
CM_ SG_ 626 StatusBindingFBD_HL_Data48 "contains Auth. Signal is encrypted, signal TAG not possible";
CM_ SG_ 626 StatusBindingFBD_HL_Data49 "contains Auth. Signal is encrypted, signal TAG not possible";
CM_ SG_ 626 StatusBindingFBD_HL_Data50 "contains Auth. Signal is encrypted, signal TAG not possible";
CM_ SG_ 626 StatusBindingFBD_HL_Data51 "contains Auth. Signal is encrypted, signal TAG not possible";
CM_ SG_ 626 StatusBindingFBD_HL_Data52 "contains Auth. Signal is encrypted, signal TAG not possible";
CM_ SG_ 626 StatusBindingFBD_HL_Data53 "contains Auth. Signal is encrypted, signal TAG not possible";
CM_ SG_ 626 StatusBindingFBD_HL_Data54 "contains Auth. Signal is encrypted, signal TAG not possible";
CM_ SG_ 626 StatusBindingFBD_HL_Data55 "contains Auth. Signal is encrypted, signal TAG not possible";
CM_ SG_ 626 StatusBindingFBD_HL_Data56 "contains Auth. Signal is encrypted, signal TAG not possible";
CM_ SG_ 626 StatusBindingFBD_HL_Data57 "contains Auth. Signal is encrypted, signal TAG not possible";
CM_ SG_ 626 StatusBindingFBD_HL_Data58 "contains Auth. Signal is encrypted, signal TAG not possible";
CM_ SG_ 626 StatusBindingFBD_HL_Data59 "contains Auth. Signal is encrypted, signal TAG not possible";
CM_ SG_ 626 StatusBindingFBD_HL_Data60 "contains Auth. Signal is encrypted, signal TAG not possible";
CM_ SG_ 621 StatusBindingFBD_HM_BindingStatu "contains actual binding status";
CM_ SG_ 621 StatusBindingFBD_HM_BindingCount "contains actual binding counter";
CM_ SG_ 621 StatusBindingFBD_HM_BindingSeque "contains actual binding sequence";
CM_ SG_ 621 StatusBindingFBD_HM_Data00 "contains Auth. Signal is encrypted, signal TAG not possible";
CM_ SG_ 621 StatusBindingFBD_HM_Data01 "contains Auth. Signal is encrypted, signal TAG not possible";
CM_ SG_ 621 StatusBindingFBD_HM_Data02 "contains Auth. Signal is encrypted, signal TAG not possible";
CM_ SG_ 621 StatusBindingFBD_HM_Data03 "contains Auth. Signal is encrypted, signal TAG not possible";
CM_ SG_ 621 StatusBindingFBD_HM_Data04 "contains Auth. Signal is encrypted, signal TAG not possible";
CM_ SG_ 621 StatusBindingFBD_HM_Data05 "contains Auth. Signal is encrypted, signal TAG not possible";
CM_ SG_ 621 StatusBindingFBD_HM_Data06 "contains Auth. Signal is encrypted, signal TAG not possible";
CM_ SG_ 621 StatusBindingFBD_HM_Data07 "contains Auth. Signal is encrypted, signal TAG not possible";
CM_ SG_ 621 StatusBindingFBD_HM_Data08 "contains Auth. Signal is encrypted, signal TAG not possible";
CM_ SG_ 621 StatusBindingFBD_HM_Data09 "contains Auth. Signal is encrypted, signal TAG not possible";
CM_ SG_ 621 StatusBindingFBD_HM_Data10 "contains Auth. Signal is encrypted, signal TAG not possible";
CM_ SG_ 621 StatusBindingFBD_HM_Data11 "contains Auth. Signal is encrypted, signal TAG not possible";
CM_ SG_ 621 StatusBindingFBD_HM_Data12 "contains Auth. Signal is encrypted, signal TAG not possible";
CM_ SG_ 621 StatusBindingFBD_HM_Data13 "contains Auth. Signal is encrypted, signal TAG not possible";
CM_ SG_ 621 StatusBindingFBD_HM_Data14 "contains Auth. Signal is encrypted, signal TAG not possible";
CM_ SG_ 621 StatusBindingFBD_HM_Data15 "contains Auth. Signal is encrypted, signal TAG not possible";
CM_ SG_ 621 StatusBindingFBD_HM_Data16 "contains Auth. Signal is encrypted, signal TAG not possible";
CM_ SG_ 621 StatusBindingFBD_HM_Data17 "contains Auth. Signal is encrypted, signal TAG not possible";
CM_ SG_ 621 StatusBindingFBD_HM_Data18 "contains Auth. Signal is encrypted, signal TAG not possible";
CM_ SG_ 621 StatusBindingFBD_HM_Data19 "contains Auth. Signal is encrypted, signal TAG not possible";
CM_ SG_ 621 StatusBindingFBD_HM_Data20 "contains Auth. Signal is encrypted, signal TAG not possible";
CM_ SG_ 621 StatusBindingFBD_HM_Data21 "contains Auth. Signal is encrypted, signal TAG not possible";
CM_ SG_ 621 StatusBindingFBD_HM_Data22 "contains Auth. Signal is encrypted, signal TAG not possible";
CM_ SG_ 621 StatusBindingFBD_HM_Data23 "contains Auth. Signal is encrypted, signal TAG not possible";
CM_ SG_ 621 StatusBindingFBD_HM_Data24 "contains Auth. Signal is encrypted, signal TAG not possible";
CM_ SG_ 621 StatusBindingFBD_HM_Data25 "contains Auth. Signal is encrypted, signal TAG not possible";
CM_ SG_ 621 StatusBindingFBD_HM_Data26 "contains Auth. Signal is encrypted, signal TAG not possible";
CM_ SG_ 621 StatusBindingFBD_HM_Data27 "contains Auth. Signal is encrypted, signal TAG not possible";
CM_ SG_ 621 StatusBindingFBD_HM_Data28 "contains Auth. Signal is encrypted, signal TAG not possible";
CM_ SG_ 621 StatusBindingFBD_HM_Data29 "contains Auth. Signal is encrypted, signal TAG not possible";
CM_ SG_ 621 StatusBindingFBD_HM_Data30 "contains Auth. Signal is encrypted, signal TAG not possible";
CM_ SG_ 621 StatusBindingFBD_HM_Data31 "contains Auth. Signal is encrypted, signal TAG not possible";
CM_ SG_ 621 StatusBindingFBD_HM_Data32 "contains Auth. Signal is encrypted, signal TAG not possible";
CM_ SG_ 621 StatusBindingFBD_HM_Data33 "contains Auth. Signal is encrypted, signal TAG not possible";
CM_ SG_ 621 StatusBindingFBD_HM_Data34 "contains Auth. Signal is encrypted, signal TAG not possible";
CM_ SG_ 621 StatusBindingFBD_HM_Data35 "contains Auth. Signal is encrypted, signal TAG not possible";
CM_ SG_ 621 StatusBindingFBD_HM_Data36 "contains Auth. Signal is encrypted, signal TAG not possible";
CM_ SG_ 621 StatusBindingFBD_HM_Data37 "contains Auth. Signal is encrypted, signal TAG not possible";
CM_ SG_ 621 StatusBindingFBD_HM_Data38 "contains Auth. Signal is encrypted, signal TAG not possible";
CM_ SG_ 621 StatusBindingFBD_HM_Data39 "contains Auth. Signal is encrypted, signal TAG not possible";
CM_ SG_ 621 StatusBindingFBD_HM_Data40 "contains Auth. Signal is encrypted, signal TAG not possible";
CM_ SG_ 621 StatusBindingFBD_HM_Data41 "contains Auth. Signal is encrypted, signal TAG not possible";
CM_ SG_ 621 StatusBindingFBD_HM_Data42 "contains Auth. Signal is encrypted, signal TAG not possible";
CM_ SG_ 621 StatusBindingFBD_HM_Data43 "contains Auth. Signal is encrypted, signal TAG not possible";
CM_ SG_ 621 StatusBindingFBD_HM_Data44 "contains Auth. Signal is encrypted, signal TAG not possible";
CM_ SG_ 621 StatusBindingFBD_HM_Data45 "contains Auth. Signal is encrypted, signal TAG not possible";
CM_ SG_ 621 StatusBindingFBD_HM_Data46 "contains Auth. Signal is encrypted, signal TAG not possible";
CM_ SG_ 621 StatusBindingFBD_HM_Data47 "contains Auth. Signal is encrypted, signal TAG not possible";
CM_ SG_ 621 StatusBindingFBD_HM_Data48 "contains Auth. Signal is encrypted, signal TAG not possible";
CM_ SG_ 621 StatusBindingFBD_HM_Data49 "contains Auth. Signal is encrypted, signal TAG not possible";
CM_ SG_ 621 StatusBindingFBD_HM_Data50 "contains Auth. Signal is encrypted, signal TAG not possible";
CM_ SG_ 621 StatusBindingFBD_HM_Data51 "contains Auth. Signal is encrypted, signal TAG not possible";
CM_ SG_ 621 StatusBindingFBD_HM_Data52 "contains Auth. Signal is encrypted, signal TAG not possible";
CM_ SG_ 621 StatusBindingFBD_HM_Data53 "contains Auth. Signal is encrypted, signal TAG not possible";
CM_ SG_ 621 StatusBindingFBD_HM_Data54 "contains Auth. Signal is encrypted, signal TAG not possible";
CM_ SG_ 621 StatusBindingFBD_HM_Data55 "contains Auth. Signal is encrypted, signal TAG not possible";
CM_ SG_ 621 StatusBindingFBD_HM_Data56 "contains Auth. Signal is encrypted, signal TAG not possible";
CM_ SG_ 621 StatusBindingFBD_HM_Data57 "contains Auth. Signal is encrypted, signal TAG not possible";
CM_ SG_ 621 StatusBindingFBD_HM_Data58 "contains Auth. Signal is encrypted, signal TAG not possible";
CM_ SG_ 621 StatusBindingFBD_HM_Data59 "contains Auth. Signal is encrypted, signal TAG not possible";
CM_ SG_ 621 StatusBindingFBD_HM_Data60 "contains Auth. Signal is encrypted, signal TAG not possible";
CM_ SG_ 627 StatusBindingFBD_HR_BindingStatu "contains actual binding status";
CM_ SG_ 627 StatusBindingFBD_HR_BindingCount "contains actual binding counter";
CM_ SG_ 627 StatusBindingFBD_HR_BindingSeque "contains actual binding sequence";
CM_ SG_ 627 StatusBindingFBD_HR_Data00 "contains Auth. Signal is encrypted, signal TAG not possible";
CM_ SG_ 627 StatusBindingFBD_HR_Data01 "contains Auth. Signal is encrypted, signal TAG not possible";
CM_ SG_ 627 StatusBindingFBD_HR_Data02 "contains Auth. Signal is encrypted, signal TAG not possible";
CM_ SG_ 627 StatusBindingFBD_HR_Data03 "contains Auth. Signal is encrypted, signal TAG not possible";
CM_ SG_ 627 StatusBindingFBD_HR_Data04 "contains Auth. Signal is encrypted, signal TAG not possible";
CM_ SG_ 627 StatusBindingFBD_HR_Data05 "contains Auth. Signal is encrypted, signal TAG not possible";
CM_ SG_ 627 StatusBindingFBD_HR_Data06 "contains Auth. Signal is encrypted, signal TAG not possible";
CM_ SG_ 627 StatusBindingFBD_HR_Data07 "contains Auth. Signal is encrypted, signal TAG not possible";
CM_ SG_ 627 StatusBindingFBD_HR_Data08 "contains Auth. Signal is encrypted, signal TAG not possible";
CM_ SG_ 627 StatusBindingFBD_HR_Data09 "contains Auth. Signal is encrypted, signal TAG not possible";
CM_ SG_ 627 StatusBindingFBD_HR_Data10 "contains Auth. Signal is encrypted, signal TAG not possible";
CM_ SG_ 627 StatusBindingFBD_HR_Data11 "contains Auth. Signal is encrypted, signal TAG not possible";
CM_ SG_ 627 StatusBindingFBD_HR_Data12 "contains Auth. Signal is encrypted, signal TAG not possible";
CM_ SG_ 627 StatusBindingFBD_HR_Data13 "contains Auth. Signal is encrypted, signal TAG not possible";
CM_ SG_ 627 StatusBindingFBD_HR_Data14 "contains Auth. Signal is encrypted, signal TAG not possible";
CM_ SG_ 627 StatusBindingFBD_HR_Data15 "contains Auth. Signal is encrypted, signal TAG not possible";
CM_ SG_ 627 StatusBindingFBD_HR_Data16 "contains Auth. Signal is encrypted, signal TAG not possible";
CM_ SG_ 627 StatusBindingFBD_HR_Data17 "contains Auth. Signal is encrypted, signal TAG not possible";
CM_ SG_ 627 StatusBindingFBD_HR_Data18 "contains Auth. Signal is encrypted, signal TAG not possible";
CM_ SG_ 627 StatusBindingFBD_HR_Data19 "contains Auth. Signal is encrypted, signal TAG not possible";
CM_ SG_ 627 StatusBindingFBD_HR_Data20 "contains Auth. Signal is encrypted, signal TAG not possible";
CM_ SG_ 627 StatusBindingFBD_HR_Data21 "contains Auth. Signal is encrypted, signal TAG not possible";
CM_ SG_ 627 StatusBindingFBD_HR_Data22 "contains Auth. Signal is encrypted, signal TAG not possible";
CM_ SG_ 627 StatusBindingFBD_HR_Data23 "contains Auth. Signal is encrypted, signal TAG not possible";
CM_ SG_ 627 StatusBindingFBD_HR_Data24 "contains Auth. Signal is encrypted, signal TAG not possible";
CM_ SG_ 627 StatusBindingFBD_HR_Data25 "contains Auth. Signal is encrypted, signal TAG not possible";
CM_ SG_ 627 StatusBindingFBD_HR_Data26 "contains Auth. Signal is encrypted, signal TAG not possible";
CM_ SG_ 627 StatusBindingFBD_HR_Data27 "contains Auth. Signal is encrypted, signal TAG not possible";
CM_ SG_ 627 StatusBindingFBD_HR_Data28 "contains Auth. Signal is encrypted, signal TAG not possible";
CM_ SG_ 627 StatusBindingFBD_HR_Data29 "contains Auth. Signal is encrypted, signal TAG not possible";
CM_ SG_ 627 StatusBindingFBD_HR_Data30 "contains Auth. Signal is encrypted, signal TAG not possible";
CM_ SG_ 627 StatusBindingFBD_HR_Data31 "contains Auth. Signal is encrypted, signal TAG not possible";
CM_ SG_ 627 StatusBindingFBD_HR_Data32 "contains Auth. Signal is encrypted, signal TAG not possible";
CM_ SG_ 627 StatusBindingFBD_HR_Data33 "contains Auth. Signal is encrypted, signal TAG not possible";
CM_ SG_ 627 StatusBindingFBD_HR_Data34 "contains Auth. Signal is encrypted, signal TAG not possible";
CM_ SG_ 627 StatusBindingFBD_HR_Data35 "contains Auth. Signal is encrypted, signal TAG not possible";
CM_ SG_ 627 StatusBindingFBD_HR_Data36 "contains Auth. Signal is encrypted, signal TAG not possible";
CM_ SG_ 627 StatusBindingFBD_HR_Data37 "contains Auth. Signal is encrypted, signal TAG not possible";
CM_ SG_ 627 StatusBindingFBD_HR_Data38 "contains Auth. Signal is encrypted, signal TAG not possible";
CM_ SG_ 627 StatusBindingFBD_HR_Data39 "contains Auth. Signal is encrypted, signal TAG not possible";
CM_ SG_ 627 StatusBindingFBD_HR_Data40 "contains Auth. Signal is encrypted, signal TAG not possible";
CM_ SG_ 627 StatusBindingFBD_HR_Data41 "contains Auth. Signal is encrypted, signal TAG not possible";
CM_ SG_ 627 StatusBindingFBD_HR_Data42 "contains Auth. Signal is encrypted, signal TAG not possible";
CM_ SG_ 627 StatusBindingFBD_HR_Data43 "contains Auth. Signal is encrypted, signal TAG not possible";
CM_ SG_ 627 StatusBindingFBD_HR_Data44 "contains Auth. Signal is encrypted, signal TAG not possible";
CM_ SG_ 627 StatusBindingFBD_HR_Data45 "contains Auth. Signal is encrypted, signal TAG not possible";
CM_ SG_ 627 StatusBindingFBD_HR_Data46 "contains Auth. Signal is encrypted, signal TAG not possible";
CM_ SG_ 627 StatusBindingFBD_HR_Data47 "contains Auth. Signal is encrypted, signal TAG not possible";
CM_ SG_ 627 StatusBindingFBD_HR_Data48 "contains Auth. Signal is encrypted, signal TAG not possible";
CM_ SG_ 627 StatusBindingFBD_HR_Data49 "contains Auth. Signal is encrypted, signal TAG not possible";
CM_ SG_ 627 StatusBindingFBD_HR_Data50 "contains Auth. Signal is encrypted, signal TAG not possible";
CM_ SG_ 627 StatusBindingFBD_HR_Data51 "contains Auth. Signal is encrypted, signal TAG not possible";
CM_ SG_ 627 StatusBindingFBD_HR_Data52 "contains Auth. Signal is encrypted, signal TAG not possible";
CM_ SG_ 627 StatusBindingFBD_HR_Data53 "contains Auth. Signal is encrypted, signal TAG not possible";
CM_ SG_ 627 StatusBindingFBD_HR_Data54 "contains Auth. Signal is encrypted, signal TAG not possible";
CM_ SG_ 627 StatusBindingFBD_HR_Data55 "contains Auth. Signal is encrypted, signal TAG not possible";
CM_ SG_ 627 StatusBindingFBD_HR_Data56 "contains Auth. Signal is encrypted, signal TAG not possible";
CM_ SG_ 627 StatusBindingFBD_HR_Data57 "contains Auth. Signal is encrypted, signal TAG not possible";
CM_ SG_ 627 StatusBindingFBD_HR_Data58 "contains Auth. Signal is encrypted, signal TAG not possible";
CM_ SG_ 627 StatusBindingFBD_HR_Data59 "contains Auth. Signal is encrypted, signal TAG not possible";
CM_ SG_ 627 StatusBindingFBD_HR_Data60 "contains Auth. Signal is encrypted, signal TAG not possible";
CM_ SG_ 622 StatusBindingFBD_Miko_BindingSta "contains actual binding status";
CM_ SG_ 622 StatusBindingFBD_Miko_BindingCou "contains actual binding counter";
CM_ SG_ 622 StatusBindingFBD_Miko_BindingSeq "contains actual binding sequence";
CM_ SG_ 622 StatusBindingFBD_Miko_Data00 "contains Auth. Signal is encrypted, signal TAG not possible";
CM_ SG_ 622 StatusBindingFBD_Miko_Data01 "contains Auth. Signal is encrypted, signal TAG not possible";
CM_ SG_ 622 StatusBindingFBD_Miko_Data02 "contains Auth. Signal is encrypted, signal TAG not possible";
CM_ SG_ 622 StatusBindingFBD_Miko_Data03 "contains Auth. Signal is encrypted, signal TAG not possible";
CM_ SG_ 622 StatusBindingFBD_Miko_Data04 "contains Auth. Signal is encrypted, signal TAG not possible";
CM_ SG_ 622 StatusBindingFBD_Miko_Data05 "contains Auth. Signal is encrypted, signal TAG not possible";
CM_ SG_ 622 StatusBindingFBD_Miko_Data06 "contains Auth. Signal is encrypted, signal TAG not possible";
CM_ SG_ 622 StatusBindingFBD_Miko_Data07 "contains Auth. Signal is encrypted, signal TAG not possible";
CM_ SG_ 622 StatusBindingFBD_Miko_Data08 "contains Auth. Signal is encrypted, signal TAG not possible";
CM_ SG_ 622 StatusBindingFBD_Miko_Data09 "contains Auth. Signal is encrypted, signal TAG not possible";
CM_ SG_ 622 StatusBindingFBD_Miko_Data10 "contains Auth. Signal is encrypted, signal TAG not possible";
CM_ SG_ 622 StatusBindingFBD_Miko_Data11 "contains Auth. Signal is encrypted, signal TAG not possible";
CM_ SG_ 622 StatusBindingFBD_Miko_Data12 "contains Auth. Signal is encrypted, signal TAG not possible";
CM_ SG_ 622 StatusBindingFBD_Miko_Data13 "contains Auth. Signal is encrypted, signal TAG not possible";
CM_ SG_ 622 StatusBindingFBD_Miko_Data14 "contains Auth. Signal is encrypted, signal TAG not possible";
CM_ SG_ 622 StatusBindingFBD_Miko_Data15 "contains Auth. Signal is encrypted, signal TAG not possible";
CM_ SG_ 622 StatusBindingFBD_Miko_Data16 "contains Auth. Signal is encrypted, signal TAG not possible";
CM_ SG_ 622 StatusBindingFBD_Miko_Data17 "contains Auth. Signal is encrypted, signal TAG not possible";
CM_ SG_ 622 StatusBindingFBD_Miko_Data18 "contains Auth. Signal is encrypted, signal TAG not possible";
CM_ SG_ 622 StatusBindingFBD_Miko_Data19 "contains Auth. Signal is encrypted, signal TAG not possible";
CM_ SG_ 622 StatusBindingFBD_Miko_Data20 "contains Auth. Signal is encrypted, signal TAG not possible";
CM_ SG_ 622 StatusBindingFBD_Miko_Data21 "contains Auth. Signal is encrypted, signal TAG not possible";
CM_ SG_ 622 StatusBindingFBD_Miko_Data22 "contains Auth. Signal is encrypted, signal TAG not possible";
CM_ SG_ 622 StatusBindingFBD_Miko_Data23 "contains Auth. Signal is encrypted, signal TAG not possible";
CM_ SG_ 622 StatusBindingFBD_Miko_Data24 "contains Auth. Signal is encrypted, signal TAG not possible";
CM_ SG_ 622 StatusBindingFBD_Miko_Data25 "contains Auth. Signal is encrypted, signal TAG not possible";
CM_ SG_ 622 StatusBindingFBD_Miko_Data26 "contains Auth. Signal is encrypted, signal TAG not possible";
CM_ SG_ 622 StatusBindingFBD_Miko_Data27 "contains Auth. Signal is encrypted, signal TAG not possible";
CM_ SG_ 622 StatusBindingFBD_Miko_Data28 "contains Auth. Signal is encrypted, signal TAG not possible";
CM_ SG_ 622 StatusBindingFBD_Miko_Data29 "contains Auth. Signal is encrypted, signal TAG not possible";
CM_ SG_ 622 StatusBindingFBD_Miko_Data30 "contains Auth. Signal is encrypted, signal TAG not possible";
CM_ SG_ 622 StatusBindingFBD_Miko_Data31 "contains Auth. Signal is encrypted, signal TAG not possible";
CM_ SG_ 622 StatusBindingFBD_Miko_Data32 "contains Auth. Signal is encrypted, signal TAG not possible";
CM_ SG_ 622 StatusBindingFBD_Miko_Data33 "contains Auth. Signal is encrypted, signal TAG not possible";
CM_ SG_ 622 StatusBindingFBD_Miko_Data34 "contains Auth. Signal is encrypted, signal TAG not possible";
CM_ SG_ 622 StatusBindingFBD_Miko_Data35 "contains Auth. Signal is encrypted, signal TAG not possible";
CM_ SG_ 622 StatusBindingFBD_Miko_Data36 "contains Auth. Signal is encrypted, signal TAG not possible";
CM_ SG_ 622 StatusBindingFBD_Miko_Data37 "contains Auth. Signal is encrypted, signal TAG not possible";
CM_ SG_ 622 StatusBindingFBD_Miko_Data38 "contains Auth. Signal is encrypted, signal TAG not possible";
CM_ SG_ 622 StatusBindingFBD_Miko_Data39 "contains Auth. Signal is encrypted, signal TAG not possible";
CM_ SG_ 622 StatusBindingFBD_Miko_Data40 "contains Auth. Signal is encrypted, signal TAG not possible";
CM_ SG_ 622 StatusBindingFBD_Miko_Data41 "contains Auth. Signal is encrypted, signal TAG not possible";
CM_ SG_ 622 StatusBindingFBD_Miko_Data42 "contains Auth. Signal is encrypted, signal TAG not possible";
CM_ SG_ 622 StatusBindingFBD_Miko_Data43 "contains Auth. Signal is encrypted, signal TAG not possible";
CM_ SG_ 622 StatusBindingFBD_Miko_Data44 "contains Auth. Signal is encrypted, signal TAG not possible";
CM_ SG_ 622 StatusBindingFBD_Miko_Data45 "contains Auth. Signal is encrypted, signal TAG not possible";
CM_ SG_ 622 StatusBindingFBD_Miko_Data46 "contains Auth. Signal is encrypted, signal TAG not possible";
CM_ SG_ 622 StatusBindingFBD_Miko_Data47 "contains Auth. Signal is encrypted, signal TAG not possible";
CM_ SG_ 622 StatusBindingFBD_Miko_Data48 "contains Auth. Signal is encrypted, signal TAG not possible";
CM_ SG_ 622 StatusBindingFBD_Miko_Data49 "contains Auth. Signal is encrypted, signal TAG not possible";
CM_ SG_ 622 StatusBindingFBD_Miko_Data50 "contains Auth. Signal is encrypted, signal TAG not possible";
CM_ SG_ 622 StatusBindingFBD_Miko_Data51 "contains Auth. Signal is encrypted, signal TAG not possible";
CM_ SG_ 622 StatusBindingFBD_Miko_Data52 "contains Auth. Signal is encrypted, signal TAG not possible";
CM_ SG_ 622 StatusBindingFBD_Miko_Data53 "contains Auth. Signal is encrypted, signal TAG not possible";
CM_ SG_ 622 StatusBindingFBD_Miko_Data54 "contains Auth. Signal is encrypted, signal TAG not possible";
CM_ SG_ 622 StatusBindingFBD_Miko_Data55 "contains Auth. Signal is encrypted, signal TAG not possible";
CM_ SG_ 622 StatusBindingFBD_Miko_Data56 "contains Auth. Signal is encrypted, signal TAG not possible";
CM_ SG_ 622 StatusBindingFBD_Miko_Data57 "contains Auth. Signal is encrypted, signal TAG not possible";
CM_ SG_ 622 StatusBindingFBD_Miko_Data58 "contains Auth. Signal is encrypted, signal TAG not possible";
CM_ SG_ 622 StatusBindingFBD_Miko_Data59 "contains Auth. Signal is encrypted, signal TAG not possible";
CM_ SG_ 622 StatusBindingFBD_Miko_Data60 "contains Auth. Signal is encrypted, signal TAG not possible";
CM_ SG_ 862 StatusBindingFBD_MM_BindingStatu "contains actual binding status";
CM_ SG_ 862 StatusBindingFBD_MM_BindingCount "contains actual binding counter";
CM_ SG_ 862 StatusBindingFBD_MM_BindingSeque "contains actual binding sequence";
CM_ SG_ 862 StatusBindingFBD_MM_Data00 "contains Auth. Signal is encrypted, signal TAG not possible";
CM_ SG_ 862 StatusBindingFBD_MM_Data01 "contains Auth. Signal is encrypted, signal TAG not possible";
CM_ SG_ 862 StatusBindingFBD_MM_Data02 "contains Auth. Signal is encrypted, signal TAG not possible";
CM_ SG_ 862 StatusBindingFBD_MM_Data03 "contains Auth. Signal is encrypted, signal TAG not possible";
CM_ SG_ 862 StatusBindingFBD_MM_Data04 "contains Auth. Signal is encrypted, signal TAG not possible";
CM_ SG_ 862 StatusBindingFBD_MM_Data05 "contains Auth. Signal is encrypted, signal TAG not possible";
CM_ SG_ 862 StatusBindingFBD_MM_Data06 "contains Auth. Signal is encrypted, signal TAG not possible";
CM_ SG_ 862 StatusBindingFBD_MM_Data07 "contains Auth. Signal is encrypted, signal TAG not possible";
CM_ SG_ 862 StatusBindingFBD_MM_Data08 "contains Auth. Signal is encrypted, signal TAG not possible";
CM_ SG_ 862 StatusBindingFBD_MM_Data09 "contains Auth. Signal is encrypted, signal TAG not possible";
CM_ SG_ 862 StatusBindingFBD_MM_Data10 "contains Auth. Signal is encrypted, signal TAG not possible";
CM_ SG_ 862 StatusBindingFBD_MM_Data11 "contains Auth. Signal is encrypted, signal TAG not possible";
CM_ SG_ 862 StatusBindingFBD_MM_Data12 "contains Auth. Signal is encrypted, signal TAG not possible";
CM_ SG_ 862 StatusBindingFBD_MM_Data13 "contains Auth. Signal is encrypted, signal TAG not possible";
CM_ SG_ 862 StatusBindingFBD_MM_Data14 "contains Auth. Signal is encrypted, signal TAG not possible";
CM_ SG_ 862 StatusBindingFBD_MM_Data15 "contains Auth. Signal is encrypted, signal TAG not possible";
CM_ SG_ 862 StatusBindingFBD_MM_Data16 "contains Auth. Signal is encrypted, signal TAG not possible";
CM_ SG_ 862 StatusBindingFBD_MM_Data17 "contains Auth. Signal is encrypted, signal TAG not possible";
CM_ SG_ 862 StatusBindingFBD_MM_Data18 "contains Auth. Signal is encrypted, signal TAG not possible";
CM_ SG_ 862 StatusBindingFBD_MM_Data19 "contains Auth. Signal is encrypted, signal TAG not possible";
CM_ SG_ 862 StatusBindingFBD_MM_Data20 "contains Auth. Signal is encrypted, signal TAG not possible";
CM_ SG_ 862 StatusBindingFBD_MM_Data21 "contains Auth. Signal is encrypted, signal TAG not possible";
CM_ SG_ 862 StatusBindingFBD_MM_Data22 "contains Auth. Signal is encrypted, signal TAG not possible";
CM_ SG_ 862 StatusBindingFBD_MM_Data23 "contains Auth. Signal is encrypted, signal TAG not possible";
CM_ SG_ 862 StatusBindingFBD_MM_Data24 "contains Auth. Signal is encrypted, signal TAG not possible";
CM_ SG_ 862 StatusBindingFBD_MM_Data25 "contains Auth. Signal is encrypted, signal TAG not possible";
CM_ SG_ 862 StatusBindingFBD_MM_Data26 "contains Auth. Signal is encrypted, signal TAG not possible";
CM_ SG_ 862 StatusBindingFBD_MM_Data27 "contains Auth. Signal is encrypted, signal TAG not possible";
CM_ SG_ 862 StatusBindingFBD_MM_Data28 "contains Auth. Signal is encrypted, signal TAG not possible";
CM_ SG_ 862 StatusBindingFBD_MM_Data29 "contains Auth. Signal is encrypted, signal TAG not possible";
CM_ SG_ 862 StatusBindingFBD_MM_Data30 "contains Auth. Signal is encrypted, signal TAG not possible";
CM_ SG_ 862 StatusBindingFBD_MM_Data31 "contains Auth. Signal is encrypted, signal TAG not possible";
CM_ SG_ 862 StatusBindingFBD_MM_Data32 "contains Auth. Signal is encrypted, signal TAG not possible";
CM_ SG_ 862 StatusBindingFBD_MM_Data33 "contains Auth. Signal is encrypted, signal TAG not possible";
CM_ SG_ 862 StatusBindingFBD_MM_Data34 "contains Auth. Signal is encrypted, signal TAG not possible";
CM_ SG_ 862 StatusBindingFBD_MM_Data35 "contains Auth. Signal is encrypted, signal TAG not possible";
CM_ SG_ 862 StatusBindingFBD_MM_Data36 "contains Auth. Signal is encrypted, signal TAG not possible";
CM_ SG_ 862 StatusBindingFBD_MM_Data37 "contains Auth. Signal is encrypted, signal TAG not possible";
CM_ SG_ 862 StatusBindingFBD_MM_Data38 "contains Auth. Signal is encrypted, signal TAG not possible";
CM_ SG_ 862 StatusBindingFBD_MM_Data39 "contains Auth. Signal is encrypted, signal TAG not possible";
CM_ SG_ 862 StatusBindingFBD_MM_Data40 "contains Auth. Signal is encrypted, signal TAG not possible";
CM_ SG_ 862 StatusBindingFBD_MM_Data41 "contains Auth. Signal is encrypted, signal TAG not possible";
CM_ SG_ 862 StatusBindingFBD_MM_Data42 "contains Auth. Signal is encrypted, signal TAG not possible";
CM_ SG_ 862 StatusBindingFBD_MM_Data43 "contains Auth. Signal is encrypted, signal TAG not possible";
CM_ SG_ 862 StatusBindingFBD_MM_Data44 "contains Auth. Signal is encrypted, signal TAG not possible";
CM_ SG_ 862 StatusBindingFBD_MM_Data45 "contains Auth. Signal is encrypted, signal TAG not possible";
CM_ SG_ 862 StatusBindingFBD_MM_Data46 "contains Auth. Signal is encrypted, signal TAG not possible";
CM_ SG_ 862 StatusBindingFBD_MM_Data47 "contains Auth. Signal is encrypted, signal TAG not possible";
CM_ SG_ 862 StatusBindingFBD_MM_Data48 "contains Auth. Signal is encrypted, signal TAG not possible";
CM_ SG_ 862 StatusBindingFBD_MM_Data49 "contains Auth. Signal is encrypted, signal TAG not possible";
CM_ SG_ 862 StatusBindingFBD_MM_Data50 "contains Auth. Signal is encrypted, signal TAG not possible";
CM_ SG_ 862 StatusBindingFBD_MM_Data51 "contains Auth. Signal is encrypted, signal TAG not possible";
CM_ SG_ 862 StatusBindingFBD_MM_Data52 "contains Auth. Signal is encrypted, signal TAG not possible";
CM_ SG_ 862 StatusBindingFBD_MM_Data53 "contains Auth. Signal is encrypted, signal TAG not possible";
CM_ SG_ 862 StatusBindingFBD_MM_Data54 "contains Auth. Signal is encrypted, signal TAG not possible";
CM_ SG_ 862 StatusBindingFBD_MM_Data55 "contains Auth. Signal is encrypted, signal TAG not possible";
CM_ SG_ 862 StatusBindingFBD_MM_Data56 "contains Auth. Signal is encrypted, signal TAG not possible";
CM_ SG_ 862 StatusBindingFBD_MM_Data57 "contains Auth. Signal is encrypted, signal TAG not possible";
CM_ SG_ 862 StatusBindingFBD_MM_Data58 "contains Auth. Signal is encrypted, signal TAG not possible";
CM_ SG_ 862 StatusBindingFBD_MM_Data59 "contains Auth. Signal is encrypted, signal TAG not possible";
CM_ SG_ 862 StatusBindingFBD_MM_Data60 "contains Auth. Signal is encrypted, signal TAG not possible";
CM_ SG_ 623 StatusBindingFBD_Trunk_BindingSt "contains actual binding status";
CM_ SG_ 623 StatusBindingFBD_Trunk_BindingCo "contains actual binding counter";
CM_ SG_ 623 StatusBindingFBD_Trunk_BindingSe "contains actual binding sequence";
CM_ SG_ 623 StatusBindingFBD_Trunk_Data00 "contains Auth. Signal is encrypted, signal TAG not possible";
CM_ SG_ 623 StatusBindingFBD_Trunk_Data01 "contains Auth. Signal is encrypted, signal TAG not possible";
CM_ SG_ 623 StatusBindingFBD_Trunk_Data02 "contains Auth. Signal is encrypted, signal TAG not possible";
CM_ SG_ 623 StatusBindingFBD_Trunk_Data03 "contains Auth. Signal is encrypted, signal TAG not possible";
CM_ SG_ 623 StatusBindingFBD_Trunk_Data04 "contains Auth. Signal is encrypted, signal TAG not possible";
CM_ SG_ 623 StatusBindingFBD_Trunk_Data05 "contains Auth. Signal is encrypted, signal TAG not possible";
CM_ SG_ 623 StatusBindingFBD_Trunk_Data06 "contains Auth. Signal is encrypted, signal TAG not possible";
CM_ SG_ 623 StatusBindingFBD_Trunk_Data07 "contains Auth. Signal is encrypted, signal TAG not possible";
CM_ SG_ 623 StatusBindingFBD_Trunk_Data08 "contains Auth. Signal is encrypted, signal TAG not possible";
CM_ SG_ 623 StatusBindingFBD_Trunk_Data09 "contains Auth. Signal is encrypted, signal TAG not possible";
CM_ SG_ 623 StatusBindingFBD_Trunk_Data10 "contains Auth. Signal is encrypted, signal TAG not possible";
CM_ SG_ 623 StatusBindingFBD_Trunk_Data11 "contains Auth. Signal is encrypted, signal TAG not possible";
CM_ SG_ 623 StatusBindingFBD_Trunk_Data12 "contains Auth. Signal is encrypted, signal TAG not possible";
CM_ SG_ 623 StatusBindingFBD_Trunk_Data13 "contains Auth. Signal is encrypted, signal TAG not possible";
CM_ SG_ 623 StatusBindingFBD_Trunk_Data14 "contains Auth. Signal is encrypted, signal TAG not possible";
CM_ SG_ 623 StatusBindingFBD_Trunk_Data15 "contains Auth. Signal is encrypted, signal TAG not possible";
CM_ SG_ 623 StatusBindingFBD_Trunk_Data16 "contains Auth. Signal is encrypted, signal TAG not possible";
CM_ SG_ 623 StatusBindingFBD_Trunk_Data17 "contains Auth. Signal is encrypted, signal TAG not possible";
CM_ SG_ 623 StatusBindingFBD_Trunk_Data18 "contains Auth. Signal is encrypted, signal TAG not possible";
CM_ SG_ 623 StatusBindingFBD_Trunk_Data19 "contains Auth. Signal is encrypted, signal TAG not possible";
CM_ SG_ 623 StatusBindingFBD_Trunk_Data20 "contains Auth. Signal is encrypted, signal TAG not possible";
CM_ SG_ 623 StatusBindingFBD_Trunk_Data21 "contains Auth. Signal is encrypted, signal TAG not possible";
CM_ SG_ 623 StatusBindingFBD_Trunk_Data22 "contains Auth. Signal is encrypted, signal TAG not possible";
CM_ SG_ 623 StatusBindingFBD_Trunk_Data23 "contains Auth. Signal is encrypted, signal TAG not possible";
CM_ SG_ 623 StatusBindingFBD_Trunk_Data24 "contains Auth. Signal is encrypted, signal TAG not possible";
CM_ SG_ 623 StatusBindingFBD_Trunk_Data25 "contains Auth. Signal is encrypted, signal TAG not possible";
CM_ SG_ 623 StatusBindingFBD_Trunk_Data26 "contains Auth. Signal is encrypted, signal TAG not possible";
CM_ SG_ 623 StatusBindingFBD_Trunk_Data27 "contains Auth. Signal is encrypted, signal TAG not possible";
CM_ SG_ 623 StatusBindingFBD_Trunk_Data28 "contains Auth. Signal is encrypted, signal TAG not possible";
CM_ SG_ 623 StatusBindingFBD_Trunk_Data29 "contains Auth. Signal is encrypted, signal TAG not possible";
CM_ SG_ 623 StatusBindingFBD_Trunk_Data30 "contains Auth. Signal is encrypted, signal TAG not possible";
CM_ SG_ 623 StatusBindingFBD_Trunk_Data31 "contains Auth. Signal is encrypted, signal TAG not possible";
CM_ SG_ 623 StatusBindingFBD_Trunk_Data32 "contains Auth. Signal is encrypted, signal TAG not possible";
CM_ SG_ 623 StatusBindingFBD_Trunk_Data33 "contains Auth. Signal is encrypted, signal TAG not possible";
CM_ SG_ 623 StatusBindingFBD_Trunk_Data34 "contains Auth. Signal is encrypted, signal TAG not possible";
CM_ SG_ 623 StatusBindingFBD_Trunk_Data35 "contains Auth. Signal is encrypted, signal TAG not possible";
CM_ SG_ 623 StatusBindingFBD_Trunk_Data36 "contains Auth. Signal is encrypted, signal TAG not possible";
CM_ SG_ 623 StatusBindingFBD_Trunk_Data37 "contains Auth. Signal is encrypted, signal TAG not possible";
CM_ SG_ 623 StatusBindingFBD_Trunk_Data38 "contains Auth. Signal is encrypted, signal TAG not possible";
CM_ SG_ 623 StatusBindingFBD_Trunk_Data39 "contains Auth. Signal is encrypted, signal TAG not possible";
CM_ SG_ 623 StatusBindingFBD_Trunk_Data40 "contains Auth. Signal is encrypted, signal TAG not possible";
CM_ SG_ 623 StatusBindingFBD_Trunk_Data41 "contains Auth. Signal is encrypted, signal TAG not possible";
CM_ SG_ 623 StatusBindingFBD_Trunk_Data42 "contains Auth. Signal is encrypted, signal TAG not possible";
CM_ SG_ 623 StatusBindingFBD_Trunk_Data43 "contains Auth. Signal is encrypted, signal TAG not possible";
CM_ SG_ 623 StatusBindingFBD_Trunk_Data44 "contains Auth. Signal is encrypted, signal TAG not possible";
CM_ SG_ 623 StatusBindingFBD_Trunk_Data45 "contains Auth. Signal is encrypted, signal TAG not possible";
CM_ SG_ 623 StatusBindingFBD_Trunk_Data46 "contains Auth. Signal is encrypted, signal TAG not possible";
CM_ SG_ 623 StatusBindingFBD_Trunk_Data47 "contains Auth. Signal is encrypted, signal TAG not possible";
CM_ SG_ 623 StatusBindingFBD_Trunk_Data48 "contains Auth. Signal is encrypted, signal TAG not possible";
CM_ SG_ 623 StatusBindingFBD_Trunk_Data49 "contains Auth. Signal is encrypted, signal TAG not possible";
CM_ SG_ 623 StatusBindingFBD_Trunk_Data50 "contains Auth. Signal is encrypted, signal TAG not possible";
CM_ SG_ 623 StatusBindingFBD_Trunk_Data51 "contains Auth. Signal is encrypted, signal TAG not possible";
CM_ SG_ 623 StatusBindingFBD_Trunk_Data52 "contains Auth. Signal is encrypted, signal TAG not possible";
CM_ SG_ 623 StatusBindingFBD_Trunk_Data53 "contains Auth. Signal is encrypted, signal TAG not possible";
CM_ SG_ 623 StatusBindingFBD_Trunk_Data54 "contains Auth. Signal is encrypted, signal TAG not possible";
CM_ SG_ 623 StatusBindingFBD_Trunk_Data55 "contains Auth. Signal is encrypted, signal TAG not possible";
CM_ SG_ 623 StatusBindingFBD_Trunk_Data56 "contains Auth. Signal is encrypted, signal TAG not possible";
CM_ SG_ 623 StatusBindingFBD_Trunk_Data57 "contains Auth. Signal is encrypted, signal TAG not possible";
CM_ SG_ 623 StatusBindingFBD_Trunk_Data58 "contains Auth. Signal is encrypted, signal TAG not possible";
CM_ SG_ 623 StatusBindingFBD_Trunk_Data59 "contains Auth. Signal is encrypted, signal TAG not possible";
CM_ SG_ 623 StatusBindingFBD_Trunk_Data60 "contains Auth. Signal is encrypted, signal TAG not possible";
CM_ SG_ 624 StatusBindingFBD_VL_BindingStatu "contains actual binding status";
CM_ SG_ 624 StatusBindingFBD_VL_BindingCount "contains actual binding counter";
CM_ SG_ 624 StatusBindingFBD_VL_BindingSeque "contains actual binding sequence";
CM_ SG_ 624 StatusBindingFBD_VL_Data00 "contains Auth. Signal is encrypted, signal TAG not possible";
CM_ SG_ 624 StatusBindingFBD_VL_Data01 "contains Auth. Signal is encrypted, signal TAG not possible";
CM_ SG_ 624 StatusBindingFBD_VL_Data02 "contains Auth. Signal is encrypted, signal TAG not possible";
CM_ SG_ 624 StatusBindingFBD_VL_Data03 "contains Auth. Signal is encrypted, signal TAG not possible";
CM_ SG_ 624 StatusBindingFBD_VL_Data04 "contains Auth. Signal is encrypted, signal TAG not possible";
CM_ SG_ 624 StatusBindingFBD_VL_Data05 "contains Auth. Signal is encrypted, signal TAG not possible";
CM_ SG_ 624 StatusBindingFBD_VL_Data06 "contains Auth. Signal is encrypted, signal TAG not possible";
CM_ SG_ 624 StatusBindingFBD_VL_Data07 "contains Auth. Signal is encrypted, signal TAG not possible";
CM_ SG_ 624 StatusBindingFBD_VL_Data08 "contains Auth. Signal is encrypted, signal TAG not possible";
CM_ SG_ 624 StatusBindingFBD_VL_Data09 "contains Auth. Signal is encrypted, signal TAG not possible";
CM_ SG_ 624 StatusBindingFBD_VL_Data10 "contains Auth. Signal is encrypted, signal TAG not possible";
CM_ SG_ 624 StatusBindingFBD_VL_Data11 "contains Auth. Signal is encrypted, signal TAG not possible";
CM_ SG_ 624 StatusBindingFBD_VL_Data12 "contains Auth. Signal is encrypted, signal TAG not possible";
CM_ SG_ 624 StatusBindingFBD_VL_Data13 "contains Auth. Signal is encrypted, signal TAG not possible";
CM_ SG_ 624 StatusBindingFBD_VL_Data14 "contains Auth. Signal is encrypted, signal TAG not possible";
CM_ SG_ 624 StatusBindingFBD_VL_Data15 "contains Auth. Signal is encrypted, signal TAG not possible";
CM_ SG_ 624 StatusBindingFBD_VL_Data16 "contains Auth. Signal is encrypted, signal TAG not possible";
CM_ SG_ 624 StatusBindingFBD_VL_Data17 "contains Auth. Signal is encrypted, signal TAG not possible";
CM_ SG_ 624 StatusBindingFBD_VL_Data18 "contains Auth. Signal is encrypted, signal TAG not possible";
CM_ SG_ 624 StatusBindingFBD_VL_Data19 "contains Auth. Signal is encrypted, signal TAG not possible";
CM_ SG_ 624 StatusBindingFBD_VL_Data20 "contains Auth. Signal is encrypted, signal TAG not possible";
CM_ SG_ 624 StatusBindingFBD_VL_Data21 "contains Auth. Signal is encrypted, signal TAG not possible";
CM_ SG_ 624 StatusBindingFBD_VL_Data22 "contains Auth. Signal is encrypted, signal TAG not possible";
CM_ SG_ 624 StatusBindingFBD_VL_Data23 "contains Auth. Signal is encrypted, signal TAG not possible";
CM_ SG_ 624 StatusBindingFBD_VL_Data24 "contains Auth. Signal is encrypted, signal TAG not possible";
CM_ SG_ 624 StatusBindingFBD_VL_Data25 "contains Auth. Signal is encrypted, signal TAG not possible";
CM_ SG_ 624 StatusBindingFBD_VL_Data26 "contains Auth. Signal is encrypted, signal TAG not possible";
CM_ SG_ 624 StatusBindingFBD_VL_Data27 "contains Auth. Signal is encrypted, signal TAG not possible";
CM_ SG_ 624 StatusBindingFBD_VL_Data28 "contains Auth. Signal is encrypted, signal TAG not possible";
CM_ SG_ 624 StatusBindingFBD_VL_Data29 "contains Auth. Signal is encrypted, signal TAG not possible";
CM_ SG_ 624 StatusBindingFBD_VL_Data30 "contains Auth. Signal is encrypted, signal TAG not possible";
CM_ SG_ 624 StatusBindingFBD_VL_Data31 "contains Auth. Signal is encrypted, signal TAG not possible";
CM_ SG_ 624 StatusBindingFBD_VL_Data32 "contains Auth. Signal is encrypted, signal TAG not possible";
CM_ SG_ 624 StatusBindingFBD_VL_Data33 "contains Auth. Signal is encrypted, signal TAG not possible";
CM_ SG_ 624 StatusBindingFBD_VL_Data34 "contains Auth. Signal is encrypted, signal TAG not possible";
CM_ SG_ 624 StatusBindingFBD_VL_Data35 "contains Auth. Signal is encrypted, signal TAG not possible";
CM_ SG_ 624 StatusBindingFBD_VL_Data36 "contains Auth. Signal is encrypted, signal TAG not possible";
CM_ SG_ 624 StatusBindingFBD_VL_Data37 "contains Auth. Signal is encrypted, signal TAG not possible";
CM_ SG_ 624 StatusBindingFBD_VL_Data38 "contains Auth. Signal is encrypted, signal TAG not possible";
CM_ SG_ 624 StatusBindingFBD_VL_Data39 "contains Auth. Signal is encrypted, signal TAG not possible";
CM_ SG_ 624 StatusBindingFBD_VL_Data40 "contains Auth. Signal is encrypted, signal TAG not possible";
CM_ SG_ 624 StatusBindingFBD_VL_Data41 "contains Auth. Signal is encrypted, signal TAG not possible";
CM_ SG_ 624 StatusBindingFBD_VL_Data42 "contains Auth. Signal is encrypted, signal TAG not possible";
CM_ SG_ 624 StatusBindingFBD_VL_Data43 "contains Auth. Signal is encrypted, signal TAG not possible";
CM_ SG_ 624 StatusBindingFBD_VL_Data44 "contains Auth. Signal is encrypted, signal TAG not possible";
CM_ SG_ 624 StatusBindingFBD_VL_Data45 "contains Auth. Signal is encrypted, signal TAG not possible";
CM_ SG_ 624 StatusBindingFBD_VL_Data46 "contains Auth. Signal is encrypted, signal TAG not possible";
CM_ SG_ 624 StatusBindingFBD_VL_Data47 "contains Auth. Signal is encrypted, signal TAG not possible";
CM_ SG_ 624 StatusBindingFBD_VL_Data48 "contains Auth. Signal is encrypted, signal TAG not possible";
CM_ SG_ 624 StatusBindingFBD_VL_Data49 "contains Auth. Signal is encrypted, signal TAG not possible";
CM_ SG_ 624 StatusBindingFBD_VL_Data50 "contains Auth. Signal is encrypted, signal TAG not possible";
CM_ SG_ 624 StatusBindingFBD_VL_Data51 "contains Auth. Signal is encrypted, signal TAG not possible";
CM_ SG_ 624 StatusBindingFBD_VL_Data52 "contains Auth. Signal is encrypted, signal TAG not possible";
CM_ SG_ 624 StatusBindingFBD_VL_Data53 "contains Auth. Signal is encrypted, signal TAG not possible";
CM_ SG_ 624 StatusBindingFBD_VL_Data54 "contains Auth. Signal is encrypted, signal TAG not possible";
CM_ SG_ 624 StatusBindingFBD_VL_Data55 "contains Auth. Signal is encrypted, signal TAG not possible";
CM_ SG_ 624 StatusBindingFBD_VL_Data56 "contains Auth. Signal is encrypted, signal TAG not possible";
CM_ SG_ 624 StatusBindingFBD_VL_Data57 "contains Auth. Signal is encrypted, signal TAG not possible";
CM_ SG_ 624 StatusBindingFBD_VL_Data58 "contains Auth. Signal is encrypted, signal TAG not possible";
CM_ SG_ 624 StatusBindingFBD_VL_Data59 "contains Auth. Signal is encrypted, signal TAG not possible";
CM_ SG_ 624 StatusBindingFBD_VL_Data60 "contains Auth. Signal is encrypted, signal TAG not possible";
CM_ SG_ 620 StatusBindingFBD_VM_BindingStatu "contains actual binding status";
CM_ SG_ 620 StatusBindingFBD_VM_BindingCount "contains actual binding counter";
CM_ SG_ 620 StatusBindingFBD_VM_BindingSeque "contains actual binding sequence";
CM_ SG_ 620 StatusBindingFBD_VM_Data00 "contains Auth. Signal is encrypted, signal TAG not possible";
CM_ SG_ 620 StatusBindingFBD_VM_Data01 "contains Auth. Signal is encrypted, signal TAG not possible";
CM_ SG_ 620 StatusBindingFBD_VM_Data02 "contains Auth. Signal is encrypted, signal TAG not possible";
CM_ SG_ 620 StatusBindingFBD_VM_Data03 "contains Auth. Signal is encrypted, signal TAG not possible";
CM_ SG_ 620 StatusBindingFBD_VM_Data04 "contains Auth. Signal is encrypted, signal TAG not possible";
CM_ SG_ 620 StatusBindingFBD_VM_Data05 "contains Auth. Signal is encrypted, signal TAG not possible";
CM_ SG_ 620 StatusBindingFBD_VM_Data06 "contains Auth. Signal is encrypted, signal TAG not possible";
CM_ SG_ 620 StatusBindingFBD_VM_Data07 "contains Auth. Signal is encrypted, signal TAG not possible";
CM_ SG_ 620 StatusBindingFBD_VM_Data08 "contains Auth. Signal is encrypted, signal TAG not possible";
CM_ SG_ 620 StatusBindingFBD_VM_Data09 "contains Auth. Signal is encrypted, signal TAG not possible";
CM_ SG_ 620 StatusBindingFBD_VM_Data10 "contains Auth. Signal is encrypted, signal TAG not possible";
CM_ SG_ 620 StatusBindingFBD_VM_Data11 "contains Auth. Signal is encrypted, signal TAG not possible";
CM_ SG_ 620 StatusBindingFBD_VM_Data12 "contains Auth. Signal is encrypted, signal TAG not possible";
CM_ SG_ 620 StatusBindingFBD_VM_Data13 "contains Auth. Signal is encrypted, signal TAG not possible";
CM_ SG_ 620 StatusBindingFBD_VM_Data14 "contains Auth. Signal is encrypted, signal TAG not possible";
CM_ SG_ 620 StatusBindingFBD_VM_Data15 "contains Auth. Signal is encrypted, signal TAG not possible";
CM_ SG_ 620 StatusBindingFBD_VM_Data16 "contains Auth. Signal is encrypted, signal TAG not possible";
CM_ SG_ 620 StatusBindingFBD_VM_Data17 "contains Auth. Signal is encrypted, signal TAG not possible";
CM_ SG_ 620 StatusBindingFBD_VM_Data18 "contains Auth. Signal is encrypted, signal TAG not possible";
CM_ SG_ 620 StatusBindingFBD_VM_Data19 "contains Auth. Signal is encrypted, signal TAG not possible";
CM_ SG_ 620 StatusBindingFBD_VM_Data20 "contains Auth. Signal is encrypted, signal TAG not possible";
CM_ SG_ 620 StatusBindingFBD_VM_Data21 "contains Auth. Signal is encrypted, signal TAG not possible";
CM_ SG_ 620 StatusBindingFBD_VM_Data22 "contains Auth. Signal is encrypted, signal TAG not possible";
CM_ SG_ 620 StatusBindingFBD_VM_Data23 "contains Auth. Signal is encrypted, signal TAG not possible";
CM_ SG_ 620 StatusBindingFBD_VM_Data24 "contains Auth. Signal is encrypted, signal TAG not possible";
CM_ SG_ 620 StatusBindingFBD_VM_Data25 "contains Auth. Signal is encrypted, signal TAG not possible";
CM_ SG_ 620 StatusBindingFBD_VM_Data26 "contains Auth. Signal is encrypted, signal TAG not possible";
CM_ SG_ 620 StatusBindingFBD_VM_Data27 "contains Auth. Signal is encrypted, signal TAG not possible";
CM_ SG_ 620 StatusBindingFBD_VM_Data28 "contains Auth. Signal is encrypted, signal TAG not possible";
CM_ SG_ 620 StatusBindingFBD_VM_Data29 "contains Auth. Signal is encrypted, signal TAG not possible";
CM_ SG_ 620 StatusBindingFBD_VM_Data30 "contains Auth. Signal is encrypted, signal TAG not possible";
CM_ SG_ 620 StatusBindingFBD_VM_Data31 "contains Auth. Signal is encrypted, signal TAG not possible";
CM_ SG_ 620 StatusBindingFBD_VM_Data32 "contains Auth. Signal is encrypted, signal TAG not possible";
CM_ SG_ 620 StatusBindingFBD_VM_Data33 "contains Auth. Signal is encrypted, signal TAG not possible";
CM_ SG_ 620 StatusBindingFBD_VM_Data34 "contains Auth. Signal is encrypted, signal TAG not possible";
CM_ SG_ 620 StatusBindingFBD_VM_Data35 "contains Auth. Signal is encrypted, signal TAG not possible";
CM_ SG_ 620 StatusBindingFBD_VM_Data36 "contains Auth. Signal is encrypted, signal TAG not possible";
CM_ SG_ 620 StatusBindingFBD_VM_Data37 "contains Auth. Signal is encrypted, signal TAG not possible";
CM_ SG_ 620 StatusBindingFBD_VM_Data38 "contains Auth. Signal is encrypted, signal TAG not possible";
CM_ SG_ 620 StatusBindingFBD_VM_Data39 "contains Auth. Signal is encrypted, signal TAG not possible";
CM_ SG_ 620 StatusBindingFBD_VM_Data40 "contains Auth. Signal is encrypted, signal TAG not possible";
CM_ SG_ 620 StatusBindingFBD_VM_Data41 "contains Auth. Signal is encrypted, signal TAG not possible";
CM_ SG_ 620 StatusBindingFBD_VM_Data42 "contains Auth. Signal is encrypted, signal TAG not possible";
CM_ SG_ 620 StatusBindingFBD_VM_Data43 "contains Auth. Signal is encrypted, signal TAG not possible";
CM_ SG_ 620 StatusBindingFBD_VM_Data44 "contains Auth. Signal is encrypted, signal TAG not possible";
CM_ SG_ 620 StatusBindingFBD_VM_Data45 "contains Auth. Signal is encrypted, signal TAG not possible";
CM_ SG_ 620 StatusBindingFBD_VM_Data46 "contains Auth. Signal is encrypted, signal TAG not possible";
CM_ SG_ 620 StatusBindingFBD_VM_Data47 "contains Auth. Signal is encrypted, signal TAG not possible";
CM_ SG_ 620 StatusBindingFBD_VM_Data48 "contains Auth. Signal is encrypted, signal TAG not possible";
CM_ SG_ 620 StatusBindingFBD_VM_Data49 "contains Auth. Signal is encrypted, signal TAG not possible";
CM_ SG_ 620 StatusBindingFBD_VM_Data50 "contains Auth. Signal is encrypted, signal TAG not possible";
CM_ SG_ 620 StatusBindingFBD_VM_Data51 "contains Auth. Signal is encrypted, signal TAG not possible";
CM_ SG_ 620 StatusBindingFBD_VM_Data52 "contains Auth. Signal is encrypted, signal TAG not possible";
CM_ SG_ 620 StatusBindingFBD_VM_Data53 "contains Auth. Signal is encrypted, signal TAG not possible";
CM_ SG_ 620 StatusBindingFBD_VM_Data54 "contains Auth. Signal is encrypted, signal TAG not possible";
CM_ SG_ 620 StatusBindingFBD_VM_Data55 "contains Auth. Signal is encrypted, signal TAG not possible";
CM_ SG_ 620 StatusBindingFBD_VM_Data56 "contains Auth. Signal is encrypted, signal TAG not possible";
CM_ SG_ 620 StatusBindingFBD_VM_Data57 "contains Auth. Signal is encrypted, signal TAG not possible";
CM_ SG_ 620 StatusBindingFBD_VM_Data58 "contains Auth. Signal is encrypted, signal TAG not possible";
CM_ SG_ 620 StatusBindingFBD_VM_Data59 "contains Auth. Signal is encrypted, signal TAG not possible";
CM_ SG_ 620 StatusBindingFBD_VM_Data60 "contains Auth. Signal is encrypted, signal TAG not possible";
CM_ SG_ 625 StatusBindingFBD_VR_BindingStatu "contains actual binding status";
CM_ SG_ 625 StatusBindingFBD_VR_BindingCount "contains actual binding counter";
CM_ SG_ 625 StatusBindingFBD_VR_BindingSeque "contains actual binding sequence";
CM_ SG_ 625 StatusBindingFBD_VR_Data00 "contains Auth. Signal is encrypted, signal TAG not possible";
CM_ SG_ 625 StatusBindingFBD_VR_Data01 "contains Auth. Signal is encrypted, signal TAG not possible";
CM_ SG_ 625 StatusBindingFBD_VR_Data02 "contains Auth. Signal is encrypted, signal TAG not possible";
CM_ SG_ 625 StatusBindingFBD_VR_Data03 "contains Auth. Signal is encrypted, signal TAG not possible";
CM_ SG_ 625 StatusBindingFBD_VR_Data04 "contains Auth. Signal is encrypted, signal TAG not possible";
CM_ SG_ 625 StatusBindingFBD_VR_Data05 "contains Auth. Signal is encrypted, signal TAG not possible";
CM_ SG_ 625 StatusBindingFBD_VR_Data06 "contains Auth. Signal is encrypted, signal TAG not possible";
CM_ SG_ 625 StatusBindingFBD_VR_Data07 "contains Auth. Signal is encrypted, signal TAG not possible";
CM_ SG_ 625 StatusBindingFBD_VR_Data08 "contains Auth. Signal is encrypted, signal TAG not possible";
CM_ SG_ 625 StatusBindingFBD_VR_Data09 "contains Auth. Signal is encrypted, signal TAG not possible";
CM_ SG_ 625 StatusBindingFBD_VR_Data10 "contains Auth. Signal is encrypted, signal TAG not possible";
CM_ SG_ 625 StatusBindingFBD_VR_Data11 "contains Auth. Signal is encrypted, signal TAG not possible";
CM_ SG_ 625 StatusBindingFBD_VR_Data12 "contains Auth. Signal is encrypted, signal TAG not possible";
CM_ SG_ 625 StatusBindingFBD_VR_Data13 "contains Auth. Signal is encrypted, signal TAG not possible";
CM_ SG_ 625 StatusBindingFBD_VR_Data14 "contains Auth. Signal is encrypted, signal TAG not possible";
CM_ SG_ 625 StatusBindingFBD_VR_Data15 "contains Auth. Signal is encrypted, signal TAG not possible";
CM_ SG_ 625 StatusBindingFBD_VR_Data16 "contains Auth. Signal is encrypted, signal TAG not possible";
CM_ SG_ 625 StatusBindingFBD_VR_Data17 "contains Auth. Signal is encrypted, signal TAG not possible";
CM_ SG_ 625 StatusBindingFBD_VR_Data18 "contains Auth. Signal is encrypted, signal TAG not possible";
CM_ SG_ 625 StatusBindingFBD_VR_Data19 "contains Auth. Signal is encrypted, signal TAG not possible";
CM_ SG_ 625 StatusBindingFBD_VR_Data20 "contains Auth. Signal is encrypted, signal TAG not possible";
CM_ SG_ 625 StatusBindingFBD_VR_Data21 "contains Auth. Signal is encrypted, signal TAG not possible";
CM_ SG_ 625 StatusBindingFBD_VR_Data22 "contains Auth. Signal is encrypted, signal TAG not possible";
CM_ SG_ 625 StatusBindingFBD_VR_Data23 "contains Auth. Signal is encrypted, signal TAG not possible";
CM_ SG_ 625 StatusBindingFBD_VR_Data24 "contains Auth. Signal is encrypted, signal TAG not possible";
CM_ SG_ 625 StatusBindingFBD_VR_Data25 "contains Auth. Signal is encrypted, signal TAG not possible";
CM_ SG_ 625 StatusBindingFBD_VR_Data26 "contains Auth. Signal is encrypted, signal TAG not possible";
CM_ SG_ 625 StatusBindingFBD_VR_Data27 "contains Auth. Signal is encrypted, signal TAG not possible";
CM_ SG_ 625 StatusBindingFBD_VR_Data28 "contains Auth. Signal is encrypted, signal TAG not possible";
CM_ SG_ 625 StatusBindingFBD_VR_Data29 "contains Auth. Signal is encrypted, signal TAG not possible";
CM_ SG_ 625 StatusBindingFBD_VR_Data30 "contains Auth. Signal is encrypted, signal TAG not possible";
CM_ SG_ 625 StatusBindingFBD_VR_Data31 "contains Auth. Signal is encrypted, signal TAG not possible";
CM_ SG_ 625 StatusBindingFBD_VR_Data32 "contains Auth. Signal is encrypted, signal TAG not possible";
CM_ SG_ 625 StatusBindingFBD_VR_Data33 "contains Auth. Signal is encrypted, signal TAG not possible";
CM_ SG_ 625 StatusBindingFBD_VR_Data34 "contains Auth. Signal is encrypted, signal TAG not possible";
CM_ SG_ 625 StatusBindingFBD_VR_Data35 "contains Auth. Signal is encrypted, signal TAG not possible";
CM_ SG_ 625 StatusBindingFBD_VR_Data36 "contains Auth. Signal is encrypted, signal TAG not possible";
CM_ SG_ 625 StatusBindingFBD_VR_Data37 "contains Auth. Signal is encrypted, signal TAG not possible";
CM_ SG_ 625 StatusBindingFBD_VR_Data38 "contains Auth. Signal is encrypted, signal TAG not possible";
CM_ SG_ 625 StatusBindingFBD_VR_Data39 "contains Auth. Signal is encrypted, signal TAG not possible";
CM_ SG_ 625 StatusBindingFBD_VR_Data40 "contains Auth. Signal is encrypted, signal TAG not possible";
CM_ SG_ 625 StatusBindingFBD_VR_Data41 "contains Auth. Signal is encrypted, signal TAG not possible";
CM_ SG_ 625 StatusBindingFBD_VR_Data42 "contains Auth. Signal is encrypted, signal TAG not possible";
CM_ SG_ 625 StatusBindingFBD_VR_Data43 "contains Auth. Signal is encrypted, signal TAG not possible";
CM_ SG_ 625 StatusBindingFBD_VR_Data44 "contains Auth. Signal is encrypted, signal TAG not possible";
CM_ SG_ 625 StatusBindingFBD_VR_Data45 "contains Auth. Signal is encrypted, signal TAG not possible";
CM_ SG_ 625 StatusBindingFBD_VR_Data46 "contains Auth. Signal is encrypted, signal TAG not possible";
CM_ SG_ 625 StatusBindingFBD_VR_Data47 "contains Auth. Signal is encrypted, signal TAG not possible";
CM_ SG_ 625 StatusBindingFBD_VR_Data48 "contains Auth. Signal is encrypted, signal TAG not possible";
CM_ SG_ 625 StatusBindingFBD_VR_Data49 "contains Auth. Signal is encrypted, signal TAG not possible";
CM_ SG_ 625 StatusBindingFBD_VR_Data50 "contains Auth. Signal is encrypted, signal TAG not possible";
CM_ SG_ 625 StatusBindingFBD_VR_Data51 "contains Auth. Signal is encrypted, signal TAG not possible";
CM_ SG_ 625 StatusBindingFBD_VR_Data52 "contains Auth. Signal is encrypted, signal TAG not possible";
CM_ SG_ 625 StatusBindingFBD_VR_Data53 "contains Auth. Signal is encrypted, signal TAG not possible";
CM_ SG_ 625 StatusBindingFBD_VR_Data54 "contains Auth. Signal is encrypted, signal TAG not possible";
CM_ SG_ 625 StatusBindingFBD_VR_Data55 "contains Auth. Signal is encrypted, signal TAG not possible";
CM_ SG_ 625 StatusBindingFBD_VR_Data56 "contains Auth. Signal is encrypted, signal TAG not possible";
CM_ SG_ 625 StatusBindingFBD_VR_Data57 "contains Auth. Signal is encrypted, signal TAG not possible";
CM_ SG_ 625 StatusBindingFBD_VR_Data58 "contains Auth. Signal is encrypted, signal TAG not possible";
CM_ SG_ 625 StatusBindingFBD_VR_Data59 "contains Auth. Signal is encrypted, signal TAG not possible";
CM_ SG_ 625 StatusBindingFBD_VR_Data60 "contains Auth. Signal is encrypted, signal TAG not possible";
CM_ SG_ 286 StatusBLEConMonitoringFBD_HL_IRK "contains ConnectionID";
CM_ SG_ 286 StatusBLEConMonitoringFBD_HL_Mon "activation/deactivation of connection monitoring";
CM_ SG_ 286 StatusBLEConMonitoringFBD_HL_Bus "cycle time to send RSSI values to Connection on CAN bus (range: 0ms ... 2520ms / step: 10ms)";
CM_ SG_ 286 StatusBLEConMonitoringFBD_HL_BLE "active BLE nodes for connection monitoring";
CM_ SG_ 281 StatusBLEConMonitoringFBD_HM_IRK "contains ConnectionID";
CM_ SG_ 281 StatusBLEConMonitoringFBD_HM_Mon "activation/deactivation of connection monitoring";
CM_ SG_ 281 StatusBLEConMonitoringFBD_HM_Bus "cycle time to send RSSI values to Connection on CAN bus (range: 0ms ... 2520ms / step: 10ms)";
CM_ SG_ 281 StatusBLEConMonitoringFBD_HM_BLE "active BLE nodes for connection monitoring";
CM_ SG_ 287 StatusBLEConMonitoringFBD_HR_IRK "contains ConnectionID";
CM_ SG_ 287 StatusBLEConMonitoringFBD_HR_Mon "activation/deactivation of connection monitoring";
CM_ SG_ 287 StatusBLEConMonitoringFBD_HR_Bus "cycle time to send RSSI values to Connection on CAN bus (range: 0ms ... 2520ms / step: 10ms)";
CM_ SG_ 287 StatusBLEConMonitoringFBD_HR_BLE "active BLE nodes for connection monitoring";
CM_ SG_ 282 StatusBLEConMonitoringFBD_Miko_I "contains ConnectionID";
CM_ SG_ 282 StatusBLEConMonitoringFBD_Miko_M "activation/deactivation of connection monitoring";
CM_ SG_ 282 StatusBLEConMonitoringFBD_Miko_B "cycle time to send RSSI values to Connection on CAN bus (range: 0ms ... 2520ms / step: 10ms)";
CM_ SG_ 282 StatusBLEConMonitoringFBD_Miko_2 "active BLE nodes for connection monitoring";
CM_ SG_ 824 StatusBLEConMonitoringFBD_MM_IRK "contains ConnectionID";
CM_ SG_ 824 StatusBLEConMonitoringFBD_MM_Mon "activation/deactivation of connection monitoring";
CM_ SG_ 824 StatusBLEConMonitoringFBD_MM_Bus "cycle time to send RSSI values to Connection on CAN bus (range: 0ms ... 2520ms / step: 10ms)";
CM_ SG_ 824 StatusBLEConMonitoringFBD_MM_BLE "active BLE nodes for connection monitoring";
CM_ SG_ 283 StatusBLEConMonitoringFBD_Trunk_ "contains ConnectionID";
CM_ SG_ 283 StatusBLEConMonitoringFBD_Trun_2 "activation/deactivation of connection monitoring";
CM_ SG_ 283 StatusBLEConMonitoringFBD_Trun_3 "cycle time to send RSSI values to Connection on CAN bus (range: 0ms ... 2520ms / step: 10ms)";
CM_ SG_ 283 StatusBLEConMonitoringFBD_Trun_4 "active BLE nodes for connection monitoring";
CM_ SG_ 284 StatusBLEConMonitoringFBD_VL_IRK "contains ConnectionID";
CM_ SG_ 284 StatusBLEConMonitoringFBD_VL_Mon "activation/deactivation of connection monitoring";
CM_ SG_ 284 StatusBLEConMonitoringFBD_VL_Bus "cycle time to send RSSI values to Connection on CAN bus (range: 0ms ... 2520ms / step: 10ms)";
CM_ SG_ 284 StatusBLEConMonitoringFBD_VL_BLE "active BLE nodes for connection monitoring";
CM_ SG_ 280 StatusBLEConMonitoringFBD_VM_IRK "contains ConnectionID";
CM_ SG_ 280 StatusBLEConMonitoringFBD_VM_Mon "activation/deactivation of connection monitoring";
CM_ SG_ 280 StatusBLEConMonitoringFBD_VM_Bus "cycle time to send RSSI values to Connection on CAN bus (range: 0ms ... 2520ms / step: 10ms)";
CM_ SG_ 280 StatusBLEConMonitoringFBD_VM_BLE "active BLE nodes for connection monitoring";
CM_ SG_ 285 StatusBLEConMonitoringFBD_VR_IRK "contains ConnectionID";
CM_ SG_ 285 StatusBLEConMonitoringFBD_VR_Mon "activation/deactivation of connection monitoring";
CM_ SG_ 285 StatusBLEConMonitoringFBD_VR_Bus "cycle time to send RSSI values to Connection on CAN bus (range: 0ms ... 2520ms / step: 10ms)";
CM_ SG_ 285 StatusBLEConMonitoringFBD_VR_BLE "active BLE nodes for connection monitoring";
CM_ SG_ 376 StatusBLECSFBD_HL_SessionID "defines the channel sounding session ID within the active connection";
CM_ SG_ 376 StatusBLECSFBD_HL_IRKListID "defines the connected BLE device";
CM_ SG_ 376 StatusBLECSFBD_HL_DeviceGroup "defines the device group";
CM_ SG_ 376 StatusBLECSFBD_HL_Algorithm "Channel Sounding Algorithm";
CM_ SG_ 376 StatusBLECSFBD_HL_DistanceOffset "Constant offset due to RF front end (RFFE)";
CM_ SG_ 376 StatusBLECSFBD_HL_AntennaConfig "defines antenna configuration";
CM_ SG_ 376 StatusBLECSFBD_HL_TxPower "defines tx power for channel sounding (10dBm by Default)";
CM_ SG_ 376 StatusBLECSFBD_HL_Role "defines the role of the receiver";
CM_ SG_ 376 StatusBLECSFBD_HL_ProcedureResul "controls sending of procedure results";
CM_ SG_ 376 StatusBLECSFBD_HL_AntennaPathPro "defines the antenna path which is included in procedure results (Bit0 is antenna path 1, Bit1 is antenna path 2, Bit2 is antenna path 3, Bit3 is antenna path 4)";
CM_ SG_ 376 StatusBLECSFBD_HL_FBDonlyThresho "distance threshold based on BLE channel sounding";
CM_ SG_ 376 StatusBLECSFBD_HL_InlinePCT "defines if inline PCT is activated on the FBD side. Only relevant in case of reflector role";
CM_ SG_ 371 StatusBLECSFBD_HM_SessionID "defines the channel sounding session ID within the active connection";
CM_ SG_ 371 StatusBLECSFBD_HM_IRKListID "defines the connected BLE device";
CM_ SG_ 371 StatusBLECSFBD_HM_DeviceGroup "defines the device group";
CM_ SG_ 371 StatusBLECSFBD_HM_Algorithm "Channel Sounding Algorithm";
CM_ SG_ 371 StatusBLECSFBD_HM_DistanceOffset "Constant offset due to RF front end (RFFE)";
CM_ SG_ 371 StatusBLECSFBD_HM_AntennaConfig "defines antenna configuration";
CM_ SG_ 371 StatusBLECSFBD_HM_TxPower "defines tx power for channel sounding (10dBm by Default)";
CM_ SG_ 371 StatusBLECSFBD_HM_Role "defines the role of the receiver";
CM_ SG_ 371 StatusBLECSFBD_HM_ProcedureResul "controls sending of procedure results";
CM_ SG_ 371 StatusBLECSFBD_HM_AntennaPathPro "defines the antenna path which is included in procedure results (Bit0 is antenna path 1, Bit1 is antenna path 2, Bit2 is antenna path 3, Bit3 is antenna path 4)";
CM_ SG_ 371 StatusBLECSFBD_HM_FBDonlyThresho "distance threshold based on BLE channel sounding";
CM_ SG_ 371 StatusBLECSFBD_HM_InlinePCT "defines if inline PCT is activated on the FBD side. Only relevant in case of reflector role";
CM_ SG_ 377 StatusBLECSFBD_HR_SessionID "defines the channel sounding session ID within the active connection";
CM_ SG_ 377 StatusBLECSFBD_HR_IRKListID "defines the connected BLE device";
CM_ SG_ 377 StatusBLECSFBD_HR_DeviceGroup "defines the device group";
CM_ SG_ 377 StatusBLECSFBD_HR_Algorithm "Channel Sounding Algorithm";
CM_ SG_ 377 StatusBLECSFBD_HR_DistanceOffset "Constant offset due to RF front end (RFFE)";
CM_ SG_ 377 StatusBLECSFBD_HR_AntennaConfig "defines antenna configuration";
CM_ SG_ 377 StatusBLECSFBD_HR_TxPower "defines tx power for channel sounding (10dBm by Default)";
CM_ SG_ 377 StatusBLECSFBD_HR_Role "defines the role of the receiver";
CM_ SG_ 377 StatusBLECSFBD_HR_ProcedureResul "controls sending of procedure results";
CM_ SG_ 377 StatusBLECSFBD_HR_AntennaPathPro "defines the antenna path which is included in procedure results (Bit0 is antenna path 1, Bit1 is antenna path 2, Bit2 is antenna path 3, Bit3 is antenna path 4)";
CM_ SG_ 377 StatusBLECSFBD_HR_FBDonlyThresho "distance threshold based on BLE channel sounding";
CM_ SG_ 377 StatusBLECSFBD_HR_InlinePCT "defines if inline PCT is activated on the FBD side. Only relevant in case of reflector role";
CM_ SG_ 372 StatusBLECSFBD_Miko_SessionID "defines the channel sounding session ID within the active connection";
CM_ SG_ 372 StatusBLECSFBD_Miko_IRKListID "defines the connected BLE device";
CM_ SG_ 372 StatusBLECSFBD_Miko_DeviceGroup "defines the device group";
CM_ SG_ 372 StatusBLECSFBD_Miko_Algorithm "Channel Sounding Algorithm";
CM_ SG_ 372 StatusBLECSFBD_Miko_DistanceOffs "Constant offset due to RF front end (RFFE)";
CM_ SG_ 372 StatusBLECSFBD_Miko_AntennaConfi "defines antenna configuration";
CM_ SG_ 372 StatusBLECSFBD_Miko_TxPower "defines tx power for channel sounding (10dBm by Default)";
CM_ SG_ 372 StatusBLECSFBD_Miko_Role "defines the role of the receiver";
CM_ SG_ 372 StatusBLECSFBD_Miko_ProcedureRes "controls sending of procedure results";
CM_ SG_ 372 StatusBLECSFBD_Miko_AntennaPathP "defines the antenna path which is included in procedure results (Bit0 is antenna path 1, Bit1 is antenna path 2, Bit2 is antenna path 3, Bit3 is antenna path 4)";
CM_ SG_ 372 StatusBLECSFBD_Miko_FBDonlyThres "distance threshold based on BLE channel sounding";
CM_ SG_ 372 StatusBLECSFBD_Miko_InlinePCT "defines if inline PCT is activated on the FBD side. Only relevant in case of reflector role";
CM_ SG_ 380 StatusBLECSFBD_MM_SessionID "defines the channel sounding session ID within the active connection";
CM_ SG_ 380 StatusBLECSFBD_MM_IRKListID "defines the connected BLE device";
CM_ SG_ 380 StatusBLECSFBD_MM_DeviceGroup "defines the device group";
CM_ SG_ 380 StatusBLECSFBD_MM_Algorithm "Channel Sounding Algorithm";
CM_ SG_ 380 StatusBLECSFBD_MM_DistanceOffset "Constant offset due to RF front end (RFFE)";
CM_ SG_ 380 StatusBLECSFBD_MM_AntennaConfig "defines antenna configuration";
CM_ SG_ 380 StatusBLECSFBD_MM_TxPower "defines tx power for channel sounding (10dBm by Default)";
CM_ SG_ 380 StatusBLECSFBD_MM_Role "defines the role of the receiver";
CM_ SG_ 380 StatusBLECSFBD_MM_ProcedureResul "controls sending of procedure results";
CM_ SG_ 380 StatusBLECSFBD_MM_AntennaPathPro "defines the antenna path which is included in procedure results (Bit0 is antenna path 1, Bit1 is antenna path 2, Bit2 is antenna path 3, Bit3 is antenna path 4)";
CM_ SG_ 380 StatusBLECSFBD_MM_FBDonlyThresho "distance threshold based on BLE channel sounding";
CM_ SG_ 380 StatusBLECSFBD_MM_InlinePCT "defines if inline PCT is activated on the FBD side. Only relevant in case of reflector role";
CM_ SG_ 373 StatusBLECSFBD_Trunk_SessionID "defines the channel sounding session ID within the active connection";
CM_ SG_ 373 StatusBLECSFBD_Trunk_IRKListID "defines the connected BLE device";
CM_ SG_ 373 StatusBLECSFBD_Trunk_DeviceGroup "defines the device group";
CM_ SG_ 373 StatusBLECSFBD_Trunk_Algorithm "Channel Sounding Algorithm";
CM_ SG_ 373 StatusBLECSFBD_Trunk_DistanceOff "Constant offset due to RF front end (RFFE)";
CM_ SG_ 373 StatusBLECSFBD_Trunk_AntennaConf "defines antenna configuration";
CM_ SG_ 373 StatusBLECSFBD_Trunk_TxPower "defines tx power for channel sounding (10dBm by Default)";
CM_ SG_ 373 StatusBLECSFBD_Trunk_Role "defines the role of the receiver";
CM_ SG_ 373 StatusBLECSFBD_Trunk_ProcedureRe "controls sending of procedure results";
CM_ SG_ 373 StatusBLECSFBD_Trunk_AntennaPath "defines the antenna path which is included in procedure results (Bit0 is antenna path 1, Bit1 is antenna path 2, Bit2 is antenna path 3, Bit3 is antenna path 4)";
CM_ SG_ 373 StatusBLECSFBD_Trunk_FBDonlyThre "distance threshold based on BLE channel sounding";
CM_ SG_ 373 StatusBLECSFBD_Trunk_InlinePCT "defines if inline PCT is activated on the FBD side. Only relevant in case of reflector role";
CM_ SG_ 374 StatusBLECSFBD_VL_SessionID "defines the channel sounding session ID within the active connection";
CM_ SG_ 374 StatusBLECSFBD_VL_IRKListID "defines the connected BLE device";
CM_ SG_ 374 StatusBLECSFBD_VL_DeviceGroup "defines the device group";
CM_ SG_ 374 StatusBLECSFBD_VL_Algorithm "Channel Sounding Algorithm";
CM_ SG_ 374 StatusBLECSFBD_VL_DistanceOffset "Constant offset due to RF front end (RFFE)";
CM_ SG_ 374 StatusBLECSFBD_VL_AntennaConfig "defines antenna configuration";
CM_ SG_ 374 StatusBLECSFBD_VL_TxPower "defines tx power for channel sounding (10dBm by Default)";
CM_ SG_ 374 StatusBLECSFBD_VL_Role "defines the role of the receiver";
CM_ SG_ 374 StatusBLECSFBD_VL_ProcedureResul "controls sending of procedure results";
CM_ SG_ 374 StatusBLECSFBD_VL_AntennaPathPro "defines the antenna path which is included in procedure results (Bit0 is antenna path 1, Bit1 is antenna path 2, Bit2 is antenna path 3, Bit3 is antenna path 4)";
CM_ SG_ 374 StatusBLECSFBD_VL_FBDonlyThresho "distance threshold based on BLE channel sounding";
CM_ SG_ 374 StatusBLECSFBD_VL_InlinePCT "defines if inline PCT is activated on the FBD side. Only relevant in case of reflector role";
CM_ SG_ 370 StatusBLECSFBD_VM_SessionID "defines the channel sounding session ID within the active connection";
CM_ SG_ 370 StatusBLECSFBD_VM_IRKListID "defines the connected BLE device";
CM_ SG_ 370 StatusBLECSFBD_VM_DeviceGroup "defines the device group";
CM_ SG_ 370 StatusBLECSFBD_VM_Algorithm "Channel Sounding Algorithm";
CM_ SG_ 370 StatusBLECSFBD_VM_DistanceOffset "Constant offset due to RF front end (RFFE)";
CM_ SG_ 370 StatusBLECSFBD_VM_AntennaConfig "defines antenna configuration";
CM_ SG_ 370 StatusBLECSFBD_VM_TxPower "defines tx power for channel sounding (10dBm by Default)";
CM_ SG_ 370 StatusBLECSFBD_VM_Role "defines the role of the receiver";
CM_ SG_ 370 StatusBLECSFBD_VM_ProcedureResul "controls sending of procedure results";
CM_ SG_ 370 StatusBLECSFBD_VM_AntennaPathPro "defines the antenna path which is included in procedure results (Bit0 is antenna path 1, Bit1 is antenna path 2, Bit2 is antenna path 3, Bit3 is antenna path 4)";
CM_ SG_ 370 StatusBLECSFBD_VM_FBDonlyThresho "distance threshold based on BLE channel sounding";
CM_ SG_ 370 StatusBLECSFBD_VM_InlinePCT "defines if inline PCT is activated on the FBD side. Only relevant in case of reflector role";
CM_ SG_ 375 StatusBLECSFBD_VR_SessionID "defines the channel sounding session ID within the active connection";
CM_ SG_ 375 StatusBLECSFBD_VR_IRKListID "defines the connected BLE device";
CM_ SG_ 375 StatusBLECSFBD_VR_DeviceGroup "defines the device group";
CM_ SG_ 375 StatusBLECSFBD_VR_Algorithm "Channel Sounding Algorithm";
CM_ SG_ 375 StatusBLECSFBD_VR_DistanceOffset "Constant offset due to RF front end (RFFE)";
CM_ SG_ 375 StatusBLECSFBD_VR_AntennaConfig "defines antenna configuration";
CM_ SG_ 375 StatusBLECSFBD_VR_TxPower "defines tx power for channel sounding (10dBm by Default)";
CM_ SG_ 375 StatusBLECSFBD_VR_Role "defines the role of the receiver";
CM_ SG_ 375 StatusBLECSFBD_VR_ProcedureResul "controls sending of procedure results";
CM_ SG_ 375 StatusBLECSFBD_VR_AntennaPathPro "defines the antenna path which is included in procedure results (Bit0 is antenna path 1, Bit1 is antenna path 2, Bit2 is antenna path 3, Bit3 is antenna path 4)";
CM_ SG_ 375 StatusBLECSFBD_VR_FBDonlyThresho "distance threshold based on BLE channel sounding";
CM_ SG_ 375 StatusBLECSFBD_VR_InlinePCT "defines if inline PCT is activated on the FBD side. Only relevant in case of reflector role";
CM_ SG_ 656 StatusBLEDeviceNameFBD_HL_Charac "contains 1st character of BLE device name";
CM_ SG_ 656 StatusBLEDeviceNameFBD_HL_Char_2 "contains 2nd character of BLE device name";
CM_ SG_ 656 StatusBLEDeviceNameFBD_HL_Char_3 "contains 3rd character of BLE device name";
CM_ SG_ 656 StatusBLEDeviceNameFBD_HL_Char_4 "contains 4th character of BLE device name";
CM_ SG_ 656 StatusBLEDeviceNameFBD_HL_Char_5 "contains 5th character of BLE device name";
CM_ SG_ 656 StatusBLEDeviceNameFBD_HL_Char_6 "contains 6th character of BLE device name";
CM_ SG_ 656 StatusBLEDeviceNameFBD_HL_Char_7 "contains 7th character of BLE device name";
CM_ SG_ 656 StatusBLEDeviceNameFBD_HL_Char_8 "contains 8th character of BLE device name";
CM_ SG_ 656 StatusBLEDeviceNameFBD_HL_Char_9 "contains 9th character of BLE device name";
CM_ SG_ 656 StatusBLEDeviceNameFBD_HL_Cha_10 "contains 10th character of BLE device name";
CM_ SG_ 656 StatusBLEDeviceNameFBD_HL_Cha_11 "contains 11th character of BLE device name";
CM_ SG_ 656 StatusBLEDeviceNameFBD_HL_Cha_12 "contains 12th character of BLE device name";
CM_ SG_ 656 StatusBLEDeviceNameFBD_HL_Cha_13 "contains 13th character of BLE device name";
CM_ SG_ 656 StatusBLEDeviceNameFBD_HL_Cha_14 "contains 14th character of BLE device name";
CM_ SG_ 656 StatusBLEDeviceNameFBD_HL_Cha_15 "contains 15th character of BLE device name";
CM_ SG_ 656 StatusBLEDeviceNameFBD_HL_Cha_16 "contains 16th character of BLE device name";
CM_ SG_ 656 StatusBLEDeviceNameFBD_HL_Cha_17 "contains 17th character of BLE device name";
CM_ SG_ 656 StatusBLEDeviceNameFBD_HL_Cha_18 "contains 18th character of BLE device name";
CM_ SG_ 656 StatusBLEDeviceNameFBD_HL_Cha_19 "contains 19th character of BLE device name";
CM_ SG_ 656 StatusBLEDeviceNameFBD_HL_Cha_20 "contains 20th character of BLE device name";
CM_ SG_ 656 StatusBLEDeviceNameFBD_HL_Cha_21 "contains 21st character of BLE device name";
CM_ SG_ 656 StatusBLEDeviceNameFBD_HL_Cha_22 "contains 22nd character of BLE device name";
CM_ SG_ 656 StatusBLEDeviceNameFBD_HL_Cha_23 "contains 23rd character of BLE device name";
CM_ SG_ 656 StatusBLEDeviceNameFBD_HL_Cha_24 "contains 24th character of BLE device name";
CM_ SG_ 656 StatusBLEDeviceNameFBD_HL_Cha_25 "contains 25th character of BLE device name";
CM_ SG_ 656 StatusBLEDeviceNameFBD_HL_Cha_26 "contains 26th character of BLE device name";
CM_ SG_ 656 StatusBLEDeviceNameFBD_HL_Cha_27 "contains 27th character of BLE device name";
CM_ SG_ 656 StatusBLEDeviceNameFBD_HL_Cha_28 "contains 28th character of BLE device name";
CM_ SG_ 656 StatusBLEDeviceNameFBD_HL_Cha_29 "contains 29th character of BLE device name";
CM_ SG_ 656 StatusBLEDeviceNameFBD_HL_Cha_30 "contains 30th character of BLE device name";

BA_DEF_ BO_ "VFrameFormat" ENUM "StandardCAN","ExtendedCAN","reserved","J1939PG","reserved","reserved","reserved","reserved","reserved","reserved","reserved","reserved","reserved","reserved","StandardCAN_FD","ExtendedCAN_FD";
BA_DEF_DEF_ "VFrameFormat" "StandardCAN";
BA_ "VFrameFormat" BO_ 486 14;
BA_ "VFrameFormat" BO_ 481 14;
BA_ "VFrameFormat" BO_ 487 14;
BA_ "VFrameFormat" BO_ 482 14;
BA_ "VFrameFormat" BO_ 442 14;
BA_ "VFrameFormat" BO_ 488 14;
BA_ "VFrameFormat" BO_ 489 14;
BA_ "VFrameFormat" BO_ 483 14;
BA_ "VFrameFormat" BO_ 484 14;
BA_ "VFrameFormat" BO_ 480 14;
BA_ "VFrameFormat" BO_ 485 14;
BA_ "VFrameFormat" BO_ 276 14;
BA_ "VFrameFormat" BO_ 271 14;
BA_ "VFrameFormat" BO_ 277 14;
BA_ "VFrameFormat" BO_ 272 14;
BA_ "VFrameFormat" BO_ 822 14;
BA_ "VFrameFormat" BO_ 273 14;
BA_ "VFrameFormat" BO_ 274 14;
BA_ "VFrameFormat" BO_ 270 14;
BA_ "VFrameFormat" BO_ 275 14;
BA_ "VFrameFormat" BO_ 626 14;
BA_ "VFrameFormat" BO_ 621 14;
BA_ "VFrameFormat" BO_ 627 14;
BA_ "VFrameFormat" BO_ 622 14;
BA_ "VFrameFormat" BO_ 862 14;
BA_ "VFrameFormat" BO_ 623 14;
BA_ "VFrameFormat" BO_ 624 14;
BA_ "VFrameFormat" BO_ 620 14;
BA_ "VFrameFormat" BO_ 625 14;
BA_ "VFrameFormat" BO_ 376 14;
BA_ "VFrameFormat" BO_ 371 14;
BA_ "VFrameFormat" BO_ 377 14;
BA_ "VFrameFormat" BO_ 372 14;
BA_ "VFrameFormat" BO_ 380 14;
BA_ "VFrameFormat" BO_ 373 14;
BA_ "VFrameFormat" BO_ 374 14;
BA_ "VFrameFormat" BO_ 370 14;
BA_ "VFrameFormat" BO_ 375 14;
BA_ "VFrameFormat" BO_ 656 14;
